VERSION ""

NS_ :

BS_:

BU_: MVS RCR_R RCR_L SNR ADAS ADAS_GW ENM THM CHR BAT BEV BEV_GW MET C_ECU C_ECU_GW

BO_ 824 ADAS338: 32 ADAS
 SG_ ADAS338_22_0_OBJECT16_WINKER : 176|2@1+ (1,0) [0|0] ""  MET
 SG_ ADAS338_22_2_OBJECT16_BRAKE : 178|1@1+ (1,0) [0|0] ""  MET
 SG_ ADAS338_22_3_OBJECT16_BLINK : 179|2@1+ (1,0) [0|0] ""  MET
 SG_ ADAS338_22_5_OBJECT16_Z : 181|11@1+ (0.1,-20) [0|0] "m"  MET
 SG_ ADAS338_20_0_OBJECT16_X : 160|9@1+ (0.1,-15) [0|0] "m"  MET
 SG_ ADAS338_19_1_OBJECT16_ANGLE : 153|7@1+ (5,0) [0|0] "deg"  MET
 SG_ ADAS338_18_0_OBJECT16_COLOR : 144|4@1+ (1,0) [0|0] ""  MET
 SG_ ADAS338_18_4_OBJECT16_SHAPE : 148|4@1+ (1,0) [0|0] ""  MET
 SG_ ADAS338_17_0_OBJECT15_WINKER : 136|2@1+ (1,0) [0|0] ""  MET
 SG_ ADAS338_17_2_OBJECT15_BRAKE : 138|1@1+ (1,0) [0|0] ""  MET
 SG_ ADAS338_17_3_OBJECT15_BLINK : 139|2@1+ (1,0) [0|0] ""  MET
 SG_ ADAS338_17_5_OBJECT15_Z : 141|11@1+ (0.1,-20) [0|0] "m"  MET
 SG_ ADAS338_15_0_OBJECT15_X : 120|9@1+ (0.1,-15) [0|0] "m"  MET
 SG_ ADAS338_14_1_OBJECT15_ANGLE : 113|7@1+ (5,0) [0|0] "deg"  MET
 SG_ ADAS338_13_0_OBJECT15_COLOR : 104|4@1+ (1,0) [0|0] ""  MET
 SG_ ADAS338_13_4_OBJECT15_SHAPE : 108|4@1+ (1,0) [0|0] ""  MET
 SG_ ADAS338_12_0_OBJECT14_WINKER : 96|2@1+ (1,0) [0|0] ""  MET
 SG_ ADAS338_12_2_OBJECT14_BRAKE : 98|1@1+ (1,0) [0|0] ""  MET
 SG_ ADAS338_12_3_OBJECT14_BLINK : 99|2@1+ (1,0) [0|0] ""  MET
 SG_ ADAS338_12_5_OBJECT14_Z : 101|11@1+ (0.1,-20) [0|0] "m"  MET
 SG_ ADAS338_10_0_OBJECT14_X : 80|9@1+ (0.1,-15) [0|0] "m"  MET
 SG_ ADAS338_9_1_OBJECT14_ANGLE : 73|7@1+ (5,0) [0|0] "deg"  MET
 SG_ ADAS338_8_0_OBJECT14_COLOR : 64|4@1+ (1,0) [0|0] ""  MET
 SG_ ADAS338_8_4_OBJECT14_SHAPE : 68|4@1+ (1,0) [0|0] ""  MET
 SG_ ADAS338_7_0_OBJECT13_WINKER : 56|2@1+ (1,0) [0|0] ""  MET
 SG_ ADAS338_7_2_OBJECT13_BRAKE : 58|1@1+ (1,0) [0|0] ""  MET
 SG_ ADAS338_7_3_OBJECT13_BLINK : 59|2@1+ (1,0) [0|0] ""  MET
 SG_ ADAS338_7_5_OBJECT13_Z : 61|11@1+ (0.1,-20) [0|0] "m"  MET
 SG_ ADAS338_5_0_OBJECT13_X : 40|9@1+ (0.1,-15) [0|0] "m"  MET
 SG_ ADAS338_4_1_OBJECT13_ANGLE : 33|7@1+ (5,0) [0|0] "deg"  MET
 SG_ ADAS338_3_0_OBJECT13_COLOR : 24|4@1+ (1,0) [0|0] ""  MET
 SG_ ADAS338_3_4_OBJECT13_SHAPE : 28|4@1+ (1,0) [0|0] ""  MET
 SG_ ADAS338_2_0_E2E_COUNTER : 16|8@1+ (1,0) [0|255] ""  MET
 SG_ ADAS338_0_0_E2E_CRC : 0|16@1+ (1,0) [0|65535] ""  MET

BO_ 823 ADAS337: 32 ADAS
 SG_ ADAS337_22_0_OBJECT12_WINKER : 176|2@1+ (1,0) [0|0] ""  MET
 SG_ ADAS337_22_2_OBJECT12_BRAKE : 178|1@1+ (1,0) [0|0] ""  MET
 SG_ ADAS337_22_3_OBJECT12_BLINK : 179|2@1+ (1,0) [0|0] ""  MET
 SG_ ADAS337_22_5_OBJECT12_Z : 181|11@1+ (0.1,-20) [0|0] "m"  MET
 SG_ ADAS337_20_0_OBJECT12_X : 160|9@1+ (0.1,-15) [0|0] "m"  MET
 SG_ ADAS337_19_1_OBJECT12_ANGLE : 153|7@1+ (5,0) [0|0] "deg"  MET
 SG_ ADAS337_18_0_OBJECT12_COLOR : 144|4@1+ (1,0) [0|0] ""  MET
 SG_ ADAS337_18_4_OBJECT12_SHAPE : 148|4@1+ (1,0) [0|0] ""  MET
 SG_ ADAS337_17_0_OBJECT11_WINKER : 136|2@1+ (1,0) [0|0] ""  MET
 SG_ ADAS337_17_2_OBJECT11_BRAKE : 138|1@1+ (1,0) [0|0] ""  MET
 SG_ ADAS337_17_3_OBJECT11_BLINK : 139|2@1+ (1,0) [0|0] ""  MET
 SG_ ADAS337_17_5_OBJECT11_Z : 141|11@1+ (0.1,-20) [0|0] "m"  MET
 SG_ ADAS337_15_0_OBJECT11_X : 120|9@1+ (0.1,-15) [0|0] "m"  MET
 SG_ ADAS337_14_1_OBJECT11_ANGLE : 113|7@1+ (5,0) [0|0] "deg"  MET
 SG_ ADAS337_13_0_OBJECT11_COLOR : 104|4@1+ (1,0) [0|0] ""  MET
 SG_ ADAS337_13_4_OBJECT11_SHAPE : 108|4@1+ (1,0) [0|0] ""  MET
 SG_ ADAS337_12_0_OBJECT10_WINKER : 96|2@1+ (1,0) [0|0] ""  MET
 SG_ ADAS337_12_2_OBJECT10_BRAKE : 98|1@1+ (1,0) [0|0] ""  MET
 SG_ ADAS337_12_3_OBJECT10_BLINK : 99|2@1+ (1,0) [0|0] ""  MET
 SG_ ADAS337_12_5_OBJECT10_Z : 101|11@1+ (0.1,-20) [0|0] "m"  MET
 SG_ ADAS337_10_0_OBJECT10_X : 80|9@1+ (0.1,-15) [0|0] "m"  MET
 SG_ ADAS337_9_1_OBJECT10_ANGLE : 73|7@1+ (5,0) [0|0] "deg"  MET
 SG_ ADAS337_8_0_OBJECT10_COLOR : 64|4@1+ (1,0) [0|0] ""  MET
 SG_ ADAS337_8_4_OBJECT10_SHAPE : 68|4@1+ (1,0) [0|0] ""  MET
 SG_ ADAS337_7_0_OBJECT9_WINKER : 56|2@1+ (1,0) [0|0] ""  MET
 SG_ ADAS337_7_2_OBJECT9_BRAKE : 58|1@1+ (1,0) [0|0] ""  MET
 SG_ ADAS337_7_3_OBJECT9_BLINK : 59|2@1+ (1,0) [0|0] ""  MET
 SG_ ADAS337_7_5_OBJECT9_Z : 61|11@1+ (0.1,-20) [0|0] "m"  MET
 SG_ ADAS337_5_0_OBJECT9_X : 40|9@1+ (0.1,-15) [0|0] "m"  MET
 SG_ ADAS337_4_1_OBJECT9_ANGLE : 33|7@1+ (5,0) [0|0] "deg"  MET
 SG_ ADAS337_3_0_OBJECT9_COLOR : 24|4@1+ (1,0) [0|0] ""  MET
 SG_ ADAS337_3_4_OBJECT9_SHAPE : 28|4@1+ (1,0) [0|0] ""  MET
 SG_ ADAS337_2_0_E2E_COUNTER : 16|8@1+ (1,0) [0|255] ""  MET
 SG_ ADAS337_0_0_E2E_CRC : 0|16@1+ (1,0) [0|65535] ""  MET

BO_ 822 ADAS336: 32 ADAS
 SG_ ADAS336_22_0_OBJECT8_WINKER : 176|2@1+ (1,0) [0|0] ""  MET
 SG_ ADAS336_22_2_OBJECT8_BRAKE : 178|1@1+ (1,0) [0|0] ""  MET
 SG_ ADAS336_22_3_OBJECT8_BLINK : 179|2@1+ (1,0) [0|0] ""  MET
 SG_ ADAS336_22_5_OBJECT8_Z : 181|11@1+ (0.1,-20) [0|0] "m"  MET
 SG_ ADAS336_20_0_OBJECT8_X : 160|9@1+ (0.1,-15) [0|0] "m"  MET
 SG_ ADAS336_19_1_OBJECT8_ANGLE : 153|7@1+ (5,0) [0|0] "deg"  MET
 SG_ ADAS336_18_0_OBJECT8_COLOR : 144|4@1+ (1,0) [0|0] ""  MET
 SG_ ADAS336_18_4_OBJECT8_SHAPE : 148|4@1+ (1,0) [0|0] ""  MET
 SG_ ADAS336_17_0_OBJECT7_WINKER : 136|2@1+ (1,0) [0|0] ""  MET
 SG_ ADAS336_17_2_OBJECT7_BRAKE : 138|1@1+ (1,0) [0|0] ""  MET
 SG_ ADAS336_17_3_OBJECT7_BLINK : 139|2@1+ (1,0) [0|0] ""  MET
 SG_ ADAS336_17_5_OBJECT7_Z : 141|11@1+ (0.1,-20) [0|0] "m"  MET
 SG_ ADAS336_15_0_OBJECT7_X : 120|9@1+ (0.1,-15) [0|0] "m"  MET
 SG_ ADAS336_14_1_OBJECT7_ANGLE : 113|7@1+ (5,0) [0|0] "deg"  MET
 SG_ ADAS336_13_0_OBJECT7_COLOR : 104|4@1+ (1,0) [0|0] ""  MET
 SG_ ADAS336_13_4_OBJECT7_SHAPE : 108|4@1+ (1,0) [0|0] ""  MET
 SG_ ADAS336_12_0_OBJECT6_WINKER : 96|2@1+ (1,0) [0|0] ""  MET
 SG_ ADAS336_12_2_OBJECT6_BRAKE : 98|1@1+ (1,0) [0|0] ""  MET
 SG_ ADAS336_12_3_OBJECT6_BLINK : 99|2@1+ (1,0) [0|0] ""  MET
 SG_ ADAS336_12_5_OBJECT6_Z : 101|11@1+ (0.1,-20) [0|0] "m"  MET
 SG_ ADAS336_10_0_OBJECT6_X : 80|9@1+ (0.1,-15) [0|0] "m"  MET
 SG_ ADAS336_9_1_OBJECT6_ANGLE : 73|7@1+ (5,0) [0|0] "deg"  MET
 SG_ ADAS336_8_0_OBJECT6_COLOR : 64|4@1+ (1,0) [0|0] ""  MET
 SG_ ADAS336_8_4_OBJECT6_SHAPE : 68|4@1+ (1,0) [0|0] ""  MET
 SG_ ADAS336_7_0_OBJECT5_WINKER : 56|2@1+ (1,0) [0|0] ""  MET
 SG_ ADAS336_7_2_OBJECT5_BRAKE : 58|1@1+ (1,0) [0|0] ""  MET
 SG_ ADAS336_7_3_OBJECT5_BLINK : 59|2@1+ (1,0) [0|0] ""  MET
 SG_ ADAS336_7_5_OBJECT5_Z : 61|11@1+ (0.1,-20) [0|0] "m"  MET
 SG_ ADAS336_5_0_OBJECT5_X : 40|9@1+ (0.1,-15) [0|0] "m"  MET
 SG_ ADAS336_4_1_OBJECT5_ANGLE : 33|7@1+ (5,0) [0|0] "deg"  MET
 SG_ ADAS336_3_0_OBJECT5_COLOR : 24|4@1+ (1,0) [0|0] ""  MET
 SG_ ADAS336_3_4_OBJECT5_SHAPE : 28|4@1+ (1,0) [0|0] ""  MET
 SG_ ADAS336_2_0_E2E_COUNTER : 16|8@1+ (1,0) [0|255] ""  MET
 SG_ ADAS336_0_0_E2E_CRC : 0|16@1+ (1,0) [0|65535] ""  MET

BO_ 821 ADAS335: 32 ADAS
 SG_ ADAS335_22_0_OBJECT4_WINKER : 176|2@1+ (1,0) [0|0] ""  MET
 SG_ ADAS335_22_2_OBJECT4_BRAKE : 178|1@1+ (1,0) [0|0] ""  MET
 SG_ ADAS335_22_3_OBJECT4_BLINK : 179|2@1+ (1,0) [0|0] ""  MET
 SG_ ADAS335_22_5_OBJECT4_Z : 181|11@1+ (0.1,-20) [0|0] "m"  MET
 SG_ ADAS335_20_0_OBJECT4_X : 160|9@1+ (0.1,-15) [0|0] "m"  MET
 SG_ ADAS335_19_1_OBJECT4_ANGLE : 153|7@1+ (5,0) [0|0] "deg"  MET
 SG_ ADAS335_18_0_OBJECT4_COLOR : 144|4@1+ (1,0) [0|0] ""  MET
 SG_ ADAS335_18_4_OBJECT4_SHAPE : 148|4@1+ (1,0) [0|0] ""  MET
 SG_ ADAS335_17_0_OBJECT3_WINKER : 136|2@1+ (1,0) [0|0] ""  MET
 SG_ ADAS335_17_2_OBJECT3_BRAKE : 138|1@1+ (1,0) [0|0] ""  MET
 SG_ ADAS335_17_3_OBJECT3_BLINK : 139|2@1+ (1,0) [0|0] ""  MET
 SG_ ADAS335_17_5_OBJECT3_Z : 141|11@1+ (0.1,-20) [0|0] "m"  MET
 SG_ ADAS335_15_0_OBJECT3_X : 120|9@1+ (0.1,-15) [0|0] "m"  MET
 SG_ ADAS335_14_1_OBJECT3_ANGLE : 113|7@1+ (5,0) [0|0] "deg"  MET
 SG_ ADAS335_13_0_OBJECT3_COLOR : 104|4@1+ (1,0) [0|0] ""  MET
 SG_ ADAS335_13_4_OBJECT3_SHAPE : 108|4@1+ (1,0) [0|0] ""  MET
 SG_ ADAS335_12_0_OBJECT2_WINKER : 96|2@1+ (1,0) [0|0] ""  MET
 SG_ ADAS335_12_2_OBJECT2_BRAKE : 98|1@1+ (1,0) [0|0] ""  MET
 SG_ ADAS335_12_3_OBJECT2_BLINK : 99|2@1+ (1,0) [0|0] ""  MET
 SG_ ADAS335_12_5_OBJECT2_Z : 101|11@1+ (0.1,-20) [0|0] "m"  MET
 SG_ ADAS335_10_0_OBJECT2_X : 80|9@1+ (0.1,-15) [0|0] "m"  MET
 SG_ ADAS335_9_1_OBJECT2_ANGLE : 73|7@1+ (5,0) [0|0] "deg"  MET
 SG_ ADAS335_8_0_OBJECT2_COLOR : 64|4@1+ (1,0) [0|0] ""  MET
 SG_ ADAS335_8_4_OBJECT2_SHAPE : 68|4@1+ (1,0) [0|0] ""  MET
 SG_ ADAS335_7_0_OBJECT1_WINKER : 56|2@1+ (1,0) [0|0] ""  MET
 SG_ ADAS335_7_2_OBJECT1_BRAKE : 58|1@1+ (1,0) [0|0] ""  MET
 SG_ ADAS335_7_3_OBJECT1_BLINK : 59|2@1+ (1,0) [0|0] ""  MET
 SG_ ADAS335_7_5_OBJECT1_Z : 61|11@1+ (0.1,-20) [0|0] "m"  MET
 SG_ ADAS335_5_0_OBJECT1_X : 40|9@1+ (0.1,-15) [0|0] "m"  MET
 SG_ ADAS335_4_1_OBJECT1_ANGLE : 33|7@1+ (5,0) [0|0] "deg"  MET
 SG_ ADAS335_3_0_OBJECT1_COLOR : 24|4@1+ (1,0) [0|0] ""  MET
 SG_ ADAS335_3_4_OBJECT1_SHAPE : 28|4@1+ (1,0) [0|0] ""  MET
 SG_ ADAS335_2_0_E2E_COUNTER : 16|8@1+ (1,0) [0|255] ""  MET
 SG_ ADAS335_0_0_E2E_CRC : 0|16@1+ (1,0) [0|65535] ""  MET

BO_ 817 ADAS331: 32 ADAS

BO_ 813 ADAS32D: 32 ADAS
 SG_ ADAS32D_2_0_E2E_COUNTER : 16|8@1+ (1,0) [0|255] ""  MET
 SG_ ADAS32D_0_0_E2E_CRC : 0|16@1+ (1,0) [0|65535] ""  MET

BO_ 812 ADAS32C: 32 ADAS
 SG_ ADAS32C_2_0_E2E_COUNTER : 16|8@1+ (1,0) [0|255] ""  MET
 SG_ ADAS32C_0_0_E2E_CRC : 0|16@1+ (1,0) [0|65535] ""  MET

BO_ 797 ADAS31D: 32 ADAS
 SG_ ADAS31D_7_0_LANE_DEP_EFFE_LANE : 56|3@1+ (1,0) [0|0] ""  MET
 SG_ ADAS31D_7_3_LANE_DEP_EFFE_BLINK : 59|1@1+ (1,0) [0|0] ""  MET
 SG_ ADAS31D_7_4_LANE_DEP_EFFE_COLOR : 60|2@1+ (1,0) [0|0] ""  MET
 SG_ ADAS31D_7_6_LANE_DEP_EFFE_LR : 62|2@1+ (1,0) [0|0] ""  MET
 SG_ ADAS31D_6_0_ALC_ICON_LEFT_COLOR : 48|2@1+ (1,0) [0|0] ""  MET
 SG_ ADAS31D_6_2_ALC_ICON_RIGHT_COLOR : 50|2@1+ (1,0) [0|0] ""  MET
 SG_ ADAS31D_6_4_ALC_ICON_LEFT : 52|2@1+ (1,0) [0|0] ""  MET
 SG_ ADAS31D_6_6_ALC_ICON_RIGHT : 54|2@1+ (1,0) [0|0] ""  MET
 SG_ ADAS31D_5_2_LANE_CHANGE_LANE3 : 42|3@1+ (1,0) [0|0] ""  MET
 SG_ ADAS31D_5_5_LANE_CHANGE_LANE2 : 45|3@1+ (1,0) [0|0] ""  MET
 SG_ ADAS31D_4_0_LANE_CHANGE_LANE1 : 32|3@1+ (1,0) [0|0] ""  MET
 SG_ ADAS31D_4_3_LANE_CHANGE_COLOR : 35|1@1+ (1,0) [0|0] ""  MET
 SG_ ADAS31D_4_4_LANE_CHANGE_LR : 36|2@1+ (1,0) [0|0] ""  MET
 SG_ ADAS31D_4_6_VEHICLE_OFFSET_COLOR : 38|2@1+ (1,0) [0|0] ""  MET
 SG_ ADAS31D_3_0_VEHICLE_OFFSET_WIDTH : 24|3@1+ (0.2,0) [0|0] "m"  MET
 SG_ ADAS31D_3_3_VEHICLE_OFFSET_LANE : 27|3@1+ (1,0) [0|0] ""  MET
 SG_ ADAS31D_3_6_VEHICLE_OFFSET_LR : 30|2@1+ (1,0) [0|0] ""  MET
 SG_ ADAS31D_2_0_E2E_COUNTER : 16|8@1+ (1,0) [0|255] ""  MET
 SG_ ADAS31D_0_0_E2E_CRC : 0|16@1+ (1,0) [0|65535] ""  MET

BO_ 796 ADAS31C: 32 ADAS
 SG_ ADAS31C_25_0_LANE6_END_X : 200|9@1+ (0.1,-15) [0|0] ""  MET
 SG_ ADAS31C_24_1_LANE6_END_Z : 193|7@1+ (2,-20) [0|0] ""  MET
 SG_ ADAS31C_23_0_LANE6_MID3_X : 184|9@1+ (0.1,-15) [0|0] ""  MET
 SG_ ADAS31C_22_1_LANE6_MID3_Z : 177|7@1+ (2,-20) [0|0] ""  MET
 SG_ ADAS31C_21_0_LANE6_MID2_X : 168|9@1+ (0.1,-15) [0|0] ""  MET
 SG_ ADAS31C_20_1_LANE6_MID2_Z : 161|7@1+ (2,-20) [0|0] ""  MET
 SG_ ADAS31C_19_0_LANE6_MID1_X : 152|9@1+ (0.1,-15) [0|0] ""  MET
 SG_ ADAS31C_18_1_LANE6_MID1_Z : 145|7@1+ (2,-20) [0|0] ""  MET
 SG_ ADAS31C_17_0_LANE6_START_X : 136|9@1+ (0.1,-15) [0|0] ""  MET
 SG_ ADAS31C_16_1_LANE6_START_Z : 129|7@1+ (2,-20) [0|0] ""  MET
 SG_ ADAS31C_15_0_LANE6_BLINK : 120|1@1+ (1,0) [0|0] ""  MET
 SG_ ADAS31C_15_1_LANE6_DISP : 121|1@1+ (1,0) [0|0] ""  MET
 SG_ ADAS31C_15_3_LANE6_COLOR : 123|3@1+ (1,0) [0|0] ""  MET
 SG_ ADAS31C_15_5_LANE6_TYPE : 125|3@1+ (1,0) [0|0] ""  MET
 SG_ ADAS31C_14_0_LANE6_NO : 112|3@1+ (1,0) [0|0] ""  MET
 SG_ ADAS31C_14_5_LANE5_NO : 117|3@1+ (1,0) [0|0] ""  MET
 SG_ ADAS31C_13_0_LANE5_END_X : 104|9@1+ (0.1,-15) [0|0] "m"  MET
 SG_ ADAS31C_12_1_LANE5_END_Z : 97|7@1+ (2,-20) [0|0] "m"  MET
 SG_ ADAS31C_11_0_LANE5_MID3_X : 88|9@1+ (0.1,-15) [0|0] "m"  MET
 SG_ ADAS31C_10_1_LANE5_MID3_Z : 81|7@1+ (2,-20) [0|0] "m"  MET
 SG_ ADAS31C_9_0_LANE5_MID2_X : 72|9@1+ (0.1,-15) [0|0] "m"  MET
 SG_ ADAS31C_8_1_LANE5_MID2_Z : 65|7@1+ (2,-20) [0|0] "m"  MET
 SG_ ADAS31C_7_0_LANE5_MID1_X : 56|9@1+ (0.1,-15) [0|0] "m"  MET
 SG_ ADAS31C_6_1_LANE5_MID1_Z : 49|7@1+ (2,-20) [0|0] "m"  MET
 SG_ ADAS31C_5_0_LANE5_START_X : 40|9@1+ (0.1,-15) [0|0] "m"  MET
 SG_ ADAS31C_4_1_LANE5_START_Z : 33|7@1+ (2,-20) [0|0] "m"  MET
 SG_ ADAS31C_3_0_LANE5_BLINK : 24|1@1+ (1,0) [0|0] ""  MET
 SG_ ADAS31C_3_1_LANE5_DISP : 25|1@1+ (1,0) [0|0] ""  MET
 SG_ ADAS31C_3_2_LANE5_COLOR : 26|3@1+ (1,0) [0|0] ""  MET
 SG_ ADAS31C_3_5_LANE5_TYPE : 29|3@1+ (1,0) [0|0] ""  MET
 SG_ ADAS31C_2_0_E2E_COUNTER : 16|8@1+ (1,0) [0|255] ""  MET
 SG_ ADAS31C_0_0_E2E_CRC : 0|16@1+ (1,0) [0|65535] ""  MET

BO_ 795 ADAS31B: 32 ADAS
 SG_ ADAS31B_31_0_LANE_DRAW_DISTANCE : 248|9@1+ (0.5,-20) [0|0] "m"  MET
 SG_ ADAS31B_30_1_INTERSECTION_MODE : 241|1@1+ (1,0) [0|0] ""  MET
 SG_ ADAS31B_29_0_ROAD2_END : 232|8@1+ (1,-20) [0|0] "m"  MET
 SG_ ADAS31B_28_0_ROAD2_START : 224|8@1+ (1,-20) [0|0] "m"  MET
 SG_ ADAS31B_27_1_ROAD2_LANE2 : 217|3@1+ (1,0) [0|0] ""  MET
 SG_ ADAS31B_27_4_ROAD2_LANE1 : 220|3@1+ (1,0) [0|0] ""  MET
 SG_ ADAS31B_27_7_ROAD2_BLINK : 223|1@1+ (1,0) [0|0] ""  MET
 SG_ ADAS31B_26_0_ROAD2_END_DRAW : 208|1@1+ (1,0) [0|0] ""  MET
 SG_ ADAS31B_26_1_ROAD2_START_DRAW : 209|1@1+ (1,0) [0|0] ""  MET
 SG_ ADAS31B_26_1_ROAD2_ANIMATION : 210|3@1+ (1,0) [0|0] ""  MET
 SG_ ADAS31B_26_5_ROAD2_COLOR : 213|3@1+ (1,0) [0|0] ""  MET
 SG_ ADAS31B_25_0_LANE4_END_X : 200|9@1+ (0.1,-15) [0|0] ""  MET
 SG_ ADAS31B_24_1_LANE4_END_Z : 193|7@1+ (2,-20) [0|0] ""  MET
 SG_ ADAS31B_23_0_LANE4_MID3_X : 184|9@1+ (0.1,-15) [0|0] ""  MET
 SG_ ADAS31B_22_1_LANE4_MID3_Z : 177|7@1+ (2,-20) [0|0] ""  MET
 SG_ ADAS31B_21_0_LANE4_MID2_X : 168|9@1+ (0.1,-15) [0|0] ""  MET
 SG_ ADAS31B_20_1_LANE4_MID2_Z : 161|7@1+ (2,-20) [0|0] ""  MET
 SG_ ADAS31B_19_0_LANE4_MID1_X : 152|9@1+ (0.1,-15) [0|0] ""  MET
 SG_ ADAS31B_18_1_LANE4_MID1_Z : 145|7@1+ (2,-20) [0|0] ""  MET
 SG_ ADAS31B_17_0_LANE4_START_X : 136|9@1+ (0.1,-15) [0|0] ""  MET
 SG_ ADAS31B_16_1_LANE4_START_Z : 129|7@1+ (2,-20) [0|0] ""  MET
 SG_ ADAS31B_15_0_LANE4_BLINK : 120|1@1+ (1,0) [0|0] ""  MET
 SG_ ADAS31B_15_1_LANE4_DISP : 121|1@1+ (1,0) [0|0] ""  MET
 SG_ ADAS31B_15_3_LANE4_COLOR : 123|3@1+ (1,0) [0|0] ""  MET
 SG_ ADAS31B_15_5_LANE4_TYPE : 125|3@1+ (1,0) [0|0] ""  MET
 SG_ ADAS31B_14_0_LANE4_NO : 112|3@1+ (1,0) [0|0] ""  MET
 SG_ ADAS31B_14_5_LANE3_NO : 117|3@1+ (1,0) [0|0] ""  MET
 SG_ ADAS31B_13_0_LANE3_END_X : 104|9@1+ (0.1,-15) [0|0] "m"  MET
 SG_ ADAS31B_12_1_LANE3_END_Z : 97|7@1+ (2,-20) [0|0] "m"  MET
 SG_ ADAS31B_11_0_LANE3_MID3_X : 88|9@1+ (0.1,-15) [0|0] "m"  MET
 SG_ ADAS31B_10_1_LANE3_MID3_Z : 81|7@1+ (2,-20) [0|0] "m"  MET
 SG_ ADAS31B_9_0_LANE3_MID2_X : 72|9@1+ (0.1,-15) [0|0] "m"  MET
 SG_ ADAS31B_8_1_LANE3_MID2_Z : 65|7@1+ (2,-20) [0|0] "m"  MET
 SG_ ADAS31B_7_0_LANE3_MID1_X : 56|9@1+ (0.1,-15) [0|0] "m"  MET
 SG_ ADAS31B_6_1_LANE3_MID1_Z : 49|7@1+ (2,-20) [0|0] "m"  MET
 SG_ ADAS31B_5_0_LANE3_START_X : 40|9@1+ (0.1,-15) [0|0] "m"  MET
 SG_ ADAS31B_4_1_LANE3_START_Z : 33|7@1+ (2,-20) [0|0] "m"  MET
 SG_ ADAS31B_3_0_LANE3_BLINK : 24|1@1+ (1,0) [0|0] ""  MET
 SG_ ADAS31B_3_1_LANE3_DISP : 25|1@1+ (1,0) [0|0] ""  MET
 SG_ ADAS31B_3_2_LANE3_COLOR : 26|3@1+ (1,0) [0|0] ""  MET
 SG_ ADAS31B_3_5_LANE3_TYPE : 29|3@1+ (1,0) [0|0] ""  MET

BO_ 794 ADAS31A: 32 ADAS
 SG_ ADAS31A_30_1_LANE_DEP_LANE_COLOR : 241|3@1+ (1,0) [0|7] ""  MET
 SG_ ADAS31A_30_4_LANE_DEP_LANE_TYPE : 244|2@1+ (1,0) [0|3] ""  MET
 SG_ ADAS31A_30_6_LANE_DEP_LANE_LEFT : 246|1@1+ (1,0) [0|1] ""  MET
 SG_ ADAS31A_30_7_LANE_DEP_LANE_RIGHT : 247|1@1+ (1,0) [0|1] ""  MET
 SG_ ADAS31A_29_0_ROAD1_END : 232|8@1+ (1,-20) [0|255] "m"  MET
 SG_ ADAS31A_28_0_ROAD1_START : 224|8@1+ (1,-20) [0|255] "m"  MET
 SG_ ADAS31A_27_1_ROAD1_LANE2 : 217|3@1+ (1,0) [0|7] ""  MET
 SG_ ADAS31A_27_4_ROAD1_LANE1 : 220|3@1+ (1,0) [0|7] ""  MET
 SG_ ADAS31A_27_7_ROAD1_BLINK : 223|1@1+ (1,0) [0|1] ""  MET
 SG_ ADAS31A_26_0_ROAD1_END_DRAW : 208|1@1+ (1,0) [0|1] ""  MET
 SG_ ADAS31A_26_1_ROAD1_START_DRAW : 209|1@1+ (1,0) [0|1] ""  MET
 SG_ ADAS31A_26_2_ROAD1_ANIMATION : 210|3@1+ (1,0) [0|7] ""  MET
 SG_ ADAS31A_26_5_ROAD1_COLOR : 213|3@1+ (1,0) [0|7] ""  MET
 SG_ ADAS31A_25_0_LANE2_END_X : 200|9@1+ (0.1,-15) [0|511] ""  MET
 SG_ ADAS31A_24_1_LANE2_END_Z : 193|7@1+ (2,-20) [0|127] ""  MET
 SG_ ADAS31A_23_0_LANE2_MID3_X : 184|9@1+ (0.1,-15) [0|511] ""  MET
 SG_ ADAS31A_22_1_LANE2_MID3_Z : 177|7@1+ (2,-20) [0|127] ""  MET
 SG_ ADAS31A_21_0_LANE2_MID2_X : 168|9@1+ (0.1,-15) [0|511] ""  MET
 SG_ ADAS31A_20_1_LANE2_MID2_Z : 161|7@1+ (2,-20) [0|127] ""  MET
 SG_ ADAS31A_19_0_LANE2_MID1_X : 152|9@1+ (0.1,-15) [0|511] ""  MET
 SG_ ADAS31A_18_1_LANE2_MID1_Z : 145|7@1+ (2,-20) [0|127] ""  MET
 SG_ ADAS31A_17_0_LANE2_START_X : 136|9@1+ (0.1,-15) [0|511] ""  MET
 SG_ ADAS31A_16_1_LANE2_START_Z : 129|7@1+ (2,-20) [0|127] ""  MET
 SG_ ADAS31A_15_0_LANE2_BLINK : 120|1@1+ (1,0) [0|1] ""  MET
 SG_ ADAS31A_15_1_LANE2_DISP : 121|1@1+ (1,0) [0|1] ""  MET
 SG_ ADAS31A_15_3_LANE2_COLOR : 123|3@1+ (1,0) [0|7] ""  MET
 SG_ ADAS31A_15_5_LANE2_TYPE : 125|3@1+ (1,0) [0|7] ""  MET
 SG_ ADAS31A_14_0_LANE2_NO : 112|3@1+ (1,0) [0|7] ""  MET
 SG_ ADAS31A_14_5_LANE1_NO : 117|3@1+ (1,0) [0|7] ""  MET
 SG_ ADAS31A_13_0_LANE1_END_X : 104|9@1+ (0.1,-15) [0|511] "m"  MET
 SG_ ADAS31A_12_1_LANE1_END_Z : 97|7@1+ (2,-20) [0|127] "m"  MET
 SG_ ADAS31A_11_0_LANE1_MID3_X : 88|9@1+ (0.1,-15) [0|511] "m"  MET
 SG_ ADAS31A_10_1_LANE1_MID3_Z : 81|7@1+ (2,-20) [0|127] "m"  MET
 SG_ ADAS31A_9_0_LANE1_MID2_X : 72|9@1+ (0.1,-15) [0|511] "m"  MET
 SG_ ADAS31A_8_1_LANE1_MID2_Z : 65|7@1+ (2,-20) [0|127] "m"  MET
 SG_ ADAS31A_7_0_LANE1_MID1_X : 56|9@1+ (0.1,-15) [0|511] "m"  MET
 SG_ ADAS31A_6_1_LANE1_MID1_Z : 49|7@1+ (2,-20) [0|127] "m"  MET
 SG_ ADAS31A_5_0_LANE1_START_X : 40|9@1+ (0.1,-15) [0|511] "m"  MET
 SG_ ADAS31A_4_1_LANE1_START_Z : 33|7@1+ (2,-20) [0|127] "m"  MET
 SG_ ADAS31A_3_0_LANE1_BLINK : 24|1@1+ (1,0) [0|1] ""  MET
 SG_ ADAS31A_3_1_LANE1_DISP : 25|1@1+ (1,0) [0|1] ""  MET
 SG_ ADAS31A_3_2_LANE1_COLOR : 26|3@1+ (1,0) [0|7] ""  MET
 SG_ ADAS31A_3_5_LANE1_TYPE : 29|3@1+ (1,0) [0|7] ""  MET
 SG_ ADAS31A_2_0_E2E_COUNTER : 16|8@1+ (1,0) [0|255] ""  MET
 SG_ ADAS31A_0_0_E2E_CRC : 0|16@1+ (1,0) [0|65535] ""  MET

BO_ 793 ADAS319: 32 ADAS
 SG_ ADAS319_2_0_E2E_COUNTER : 16|8@1+ (1,0) [0|255] ""  MET
 SG_ ADAS319_0_0_E2E_CRC : 0|16@1+ (1,0) [0|65535] ""  MET

BO_ 792 ADAS318: 32 ADAS
 SG_ ADAS318_31_3_FCW_INIT_LAMP : 251|1@1+ (1,0) [0|1] ""  MET
 SG_ ADAS318_31_2_ADAS_CAUTION_INIT : 250|1@1+ (1,0) [0|1] ""  MET
 SG_ ADAS318_31_1_LANE_DEP_INIT : 249|1@1+ (1,0) [0|1] ""  MET
 SG_ ADAS318_31_0_PRECRASH_INIT : 248|1@1+ (1,0) [0|1] ""  MET
 SG_ ADAS318_18_0_DISP_RE_WRNG : 144|2@1+ (1,0) [0|3] ""  MET
 SG_ ADAS318_17_6_DISP_RE_SIDE_WRNG : 142|2@1+ (1,0) [0|3] ""  MET
 SG_ ADAS318_17_4_DISP_FR_SIDE_WRNG : 140|2@1+ (1,0) [0|3] ""  MET
 SG_ ADAS318_17_2_DISP_FR_WRNG : 138|2@1+ (1,0) [0|3] ""  MET
 SG_ ADAS318_17_0_DISP_ALL_WRNG : 136|2@1+ (1,0) [0|3] ""  MET
 SG_ ADAS318_13_0_MSG_SIGN_UNRECOG : 104|1@1+ (1,0) [0|1] ""  MET
 SG_ ADAS318_12_7_MSG_STRG_TS_WRNG : 103|1@1+ (1,0) [0|1] ""  MET
 SG_ ADAS318_12_6_MSG_ADAS_SYS_ICON : 102|1@1+ (1,0) [0|1] ""  MET
 SG_ ADAS318_12_5_MSG_ADAS_FUNC_OFF : 101|1@1+ (1,0) [0|1] ""  MET
 SG_ ADAS318_12_4_MSG_ADAS_HALT : 100|1@1+ (1,0) [0|1] ""  MET
 SG_ ADAS318_12_3_MSG_ADAS_FAIL : 99|1@1+ (1,0) [0|1] ""  MET
 SG_ ADAS318_12_2_MSG_PASS_MRM_HALT : 98|1@1+ (1,0) [0|1] ""  MET
 SG_ ADAS318_12_1_MSG_PASS_MRM_FAIL : 97|1@1+ (1,0) [0|1] ""  MET
 SG_ ADAS318_12_0_MSG_SNR_HALT : 96|1@1+ (1,0) [0|1] ""  MET
 SG_ ADAS318_11_7_MSG_RAB_PED_HALT : 95|1@1+ (1,0) [0|1] ""  MET
 SG_ ADAS318_11_6_MSG_RAB_PED_FAIL : 94|1@1+ (1,0) [0|1] ""  MET
 SG_ ADAS318_11_5_MSG_RAB_HALT : 93|1@1+ (1,0) [0|1] ""  MET
 SG_ ADAS318_11_4_MSG_RAB_FAIL : 92|1@1+ (1,0) [0|1] ""  MET
 SG_ ADAS318_11_3_MSG_RCR_HALT_BLK : 91|1@1+ (1,0) [0|1] ""  MET
 SG_ ADAS318_11_2_MSG_RCR_HALT : 90|1@1+ (1,0) [0|1] ""  MET
 SG_ ADAS318_11_1_MSG_RCR_FAIL : 89|1@1+ (1,0) [0|1] ""  MET
 SG_ ADAS318_11_0_MSG_FCR_HALT : 88|1@1+ (1,0) [0|1] ""  MET
 SG_ ADAS318_10_7_MSG_FCR_FAIL : 87|1@1+ (1,0) [0|1] ""  MET
 SG_ ADAS318_10_6_MSG_MCAM_HALT : 86|1@1+ (1,0) [0|1] ""  MET
 SG_ ADAS318_10_5_MSG_MCAM_FAIL : 85|1@1+ (1,0) [0|1] ""  MET
 SG_ ADAS318_10_4_MSG_EYE_HALT : 84|1@1+ (1,0) [0|1] ""  MET
 SG_ ADAS318_10_3_MSG_EYE_HALT_TEMP : 83|1@1+ (1,0) [0|1] ""  MET
 SG_ ADAS318_10_2_MSG_EYE_HALT_WTR : 82|1@1+ (1,0) [0|1] ""  MET
 SG_ ADAS318_10_1_MSG_EYE_FAIL : 81|1@1+ (1,0) [0|1] ""  MET
 SG_ ADAS318_10_0_MSG_ADASECU_FAIL : 80|1@1+ (1,0) [0|1] ""  MET
 SG_ ADAS318_9_1_STRG_HAP_WRNG_IND : 73|1@1+ (1,0) [0|1] ""  MET
 SG_ ADAS318_9_0_STRG_TS_WRNG_IND : 72|1@1+ (1,0) [0|1] ""  MET
 SG_ ADAS318_8_7_ELK_OFF_IND : 71|1@1+ (1,0) [0|1] ""  MET
 SG_ ADAS318_8_6_AES_OFF_IND : 70|1@1+ (1,0) [0|1] ""  MET
 SG_ ADAS318_8_5_LDP_OFF_IND : 69|1@1+ (1,0) [0|1] ""  MET
 SG_ ADAS318_8_4_LKS_WRNG_IND : 68|1@1+ (1,0) [0|1] ""  MET
 SG_ ADAS318_8_3_ACC_WRNG_IND : 67|1@1+ (1,0) [0|1] ""  MET
 SG_ ADAS318_8_2_MRM_WRNG_IND : 66|1@1+ (1,0) [0|1] ""  MET
 SG_ ADAS318_8_0_DDAW_STATE_IND : 64|2@1+ (1,0) [0|3] ""  MET
 SG_ ADAS318_7_6_ISA_STATE_IND : 62|2@1+ (1,0) [0|3] ""  MET
 SG_ ADAS318_7_4_RAB_STATE_IND : 60|2@1+ (1,0) [0|3] ""  MET
 SG_ ADAS318_7_2_ACPE_STATE_IND : 58|2@1+ (1,0) [0|3] ""  MET
 SG_ ADAS318_7_0_ADAS_STATE_IND : 56|2@1+ (1,0) [0|3] ""  MET
 SG_ ADAS318_6_2_RAB_PED_STATE_IND : 50|2@1+ (1,0) [0|3] ""  MET
 SG_ ADAS318_6_0_SNR_STATE_IND : 48|2@1+ (1,0) [0|3] ""  MET
 SG_ ADAS318_5_6_SRVD_STATE_IND : 46|2@1+ (1,0) [0|3] ""  MET
 SG_ ADAS318_5_4_FCTB_STATE_IND : 44|2@1+ (1,0) [0|3] ""  MET
 SG_ ADAS318_5_2_MCAM_STATE_IND : 42|2@1+ (1,0) [0|3] ""  MET
 SG_ ADAS318_5_0_EYESIGHT_STATE_IND : 40|2@1+ (1,0) [0|3] ""  MET
 SG_ ADAS318_3_4_ADAS_CAUTION_IND : 28|2@1+ (1,0) [0|3] ""  MET
 SG_ ADAS318_3_2_LANE_DEP_STATE_IND : 26|2@1+ (1,0) [0|3] ""  MET
 SG_ ADAS318_3_0_PRECRASH_STATE_IND : 24|2@1+ (1,0) [0|3] ""  MET
 SG_ ADAS318_2_0_E2E_COUNTER : 16|8@1+ (1,0) [0|255] ""  MET
 SG_ ADAS318_0_0_E2E_CRC : 0|16@1+ (1,0) [0|65535] ""  MET

BO_ 791 ADAS317: 32 ADAS
 SG_ ADAS317_18_0_LIGHT_EAM_GREEN2 : 144|2@1+ (1,0) [0|3] "" Vector__XXX
 SG_ ADAS317_17_0_LIGHT_EAM_GREEN1 : 136|2@1+ (1,0) [0|3] "" Vector__XXX
 SG_ ADAS317_17_4_LIGHT_EAM_BLUE : 140|2@1+ (1,0) [0|3] "" Vector__XXX
 SG_ ADAS317_16_0_LIGHT_EAM_YELLOW : 128|4@1+ (1,0) [0|15] "" Vector__XXX
 SG_ ADAS317_16_4_LIGHT_EAM_RED : 132|4@1+ (1,0) [0|15] "" Vector__XXX
 SG_ ADAS317_15_0_LINK_ICON_POSITION : 120|2@1+ (1,0) [0|3] ""  MET
 SG_ ADAS317_15_2_LINK_ICON_SPD_SIGN : 122|2@1+ (1,0) [0|3] ""  MET
 SG_ ADAS317_15_4_LINK_ICON_CC : 124|2@1+ (1,0) [0|3] ""  MET
 SG_ ADAS317_14_0_SPD_CONT_ICON_COLOR : 112|3@1+ (1,0) [0|7] ""  MET
 SG_ ADAS317_14_3_SPD_CONT_ICON_BLINK : 115|1@1+ (1,0) [0|1] ""  MET
 SG_ ADAS317_14_4_SPD_CONT_ICON_DIST : 116|12@1+ (1,0) [0|4095] ""  MET
 SG_ ADAS317_12_0_SPD_CONT_ICON_SPEED : 96|8@1+ (1,0) [0|255] ""  MET
 SG_ ADAS317_11_0_SPD_CONT_ICON_TYPE : 88|6@1+ (1,0) [0|63] ""  MET
 SG_ ADAS317_10_0_SAFETY_MODE_PATTERN : 80|2@1+ (1,0) [0|3] ""  MET
 SG_ ADAS317_10_2_SAFETY_MODE_COLOR : 82|3@1+ (1,0) [0|7] ""  MET
 SG_ ADAS317_10_5_PDA_STEER_ICON : 85|2@1+ (1,0) [0|3] ""  MET
 SG_ ADAS317_9_0_FCW_INIT : 72|1@1+ (1,0) [0|1] ""  MET
 SG_ ADAS317_9_1_FCTI_ICON_LEFT : 73|2@1+ (1,0) [0|3] ""  MET
 SG_ ADAS317_9_3_FCTI_ICON_RIGHT : 75|2@1+ (1,0) [0|3] ""  MET
 SG_ ADAS317_9_5_IND_SAFETY_MODE : 77|1@1+ (1,0) [0|1] ""  MET
 SG_ ADAS317_9_6_LIMITER_BACK_SPEED : 78|1@1+ (1,0) [0|1] ""  MET
 SG_ ADAS317_8_0_LCF_ICON : 64|3@1+ (1,0) [0|7] ""  MET
 SG_ ADAS317_8_3_LCF_ICON_WORD : 67|1@1+ (1,0) [0|1] ""  MET
 SG_ ADAS317_8_4_AD_DRV_ICON : 68|2@1+ (1,0) [0|3] ""  MET
 SG_ ADAS317_8_6_ODD_ROAD_ICON : 70|1@1+ (1,0) [0|1] ""  MET
 SG_ ADAS317_7_0_INFO_SET_SPD : 56|8@1+ (1,0) [0|255] "km/h or MPH"  MET
 SG_ ADAS317_6_0_INFO_MAIN_CC : 48|3@1+ (1,0) [0|7] ""  MET
 SG_ ADAS317_6_3_HOLD_DISP : 51|1@1+ (1,0) [0|1] ""  MET
 SG_ ADAS317_5_1_ATTENUAT_MUTE : 41|2@1+ (1,0) [0|3] ""  MET
 SG_ ADAS317_5_3_SOUND_STOP_FLAG : 43|1@1+ (1,0) [0|1] ""  MET
 SG_ ADAS317_5_4_ALARMCODE_SOUND : 44|10@1+ (1,0) [0|1023] ""  MET
 SG_ ADAS317_4_6_ALARMCODE_DISP : 38|10@1+ (1,0) [0|1023] ""  MET
 SG_ ADAS317_2_0_E2E_COUNTER : 16|8@1+ (1,0) [0|255] ""  MET
 SG_ ADAS317_0_0_E2E_CRC : 0|16@1+ (1,0) [0|65535] ""  MET

BO_ 276 SNR114: 32 Vector__XXX

BO_ 2564481097 OBC18DAE049: 8 BEV_GW
 SG_ OBC18DAE049_DIAG_DATA : 7|64@0+ (1,0) [0|1.844674407371E+19] ""  C_ECU_GW

BO_ 2564442592 DNT18DA49E0: 8 C_ECU_GW
 SG_ DNT18DA49E0_DIAG_DATA : 7|64@0+ (1,0) [0|1.844674407371E+19] ""  BEV_GW

BO_ 1099 EVCC44B: 32 C_ECU_GW
 SG_ EVCC44B_27_0_EVSE_ID_7_EVCC : 216|32@1+ (1,0) [0|31] ""  CHR
 SG_ EVCC44B_23_0_EVSE_ID_6_EVCC : 184|32@1+ (1,0) [0|31] ""  CHR
 SG_ EVCC44B_19_0_EVSE_ID_5_EVCC : 152|32@1+ (1,0) [0|31] ""  CHR
 SG_ EVCC44B_15_0_EVSE_ID_4_EVCC : 120|32@1+ (1,0) [0|31] ""  CHR
 SG_ EVCC44B_11_0_EVSE_ID_3_EVCC : 88|32@1+ (1,0) [0|31] ""  CHR
 SG_ EVCC44B_7_0_EVSE_ID_2_EVCC : 56|32@1+ (1,0) [0|31] ""  CHR
 SG_ EVCC44B_3_0_EVSE_ID_1_EVCC : 24|32@1+ (1,0) [0|31] ""  CHR
 SG_ EVCC44B_2_0_E2E_COUNTER : 16|8@1+ (1,0) [0|255] "" Vector__XXX
 SG_ EVCC44B_0_0_E2E_CRC : 0|16@1+ (1,0) [0|65535] "" Vector__XXX

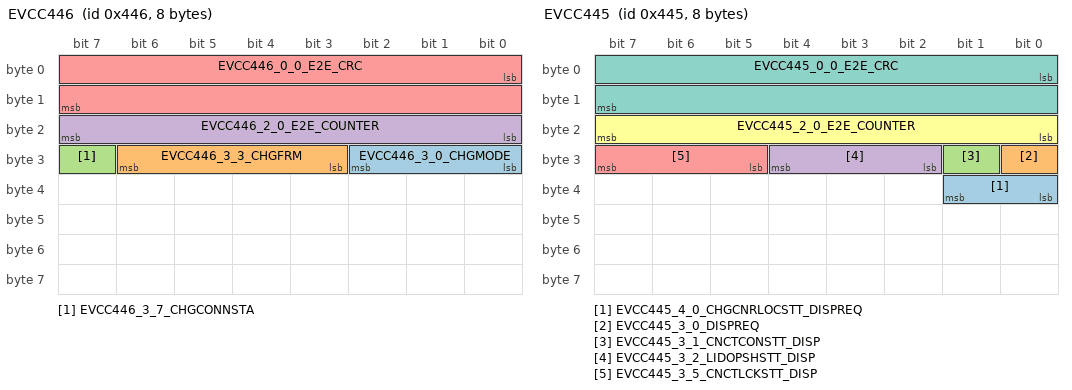
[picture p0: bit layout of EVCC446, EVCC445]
BO_ 1094 EVCC446: 8 C_ECU_GW
 SG_ EVCC446_3_0_CHGMODE : 24|3@1+ (1,0) [0|7] ""  MET
 SG_ EVCC446_3_3_CHGFRM : 27|4@1+ (1,0) [0|15] ""  MET
 SG_ EVCC446_3_7_CHGCONNSTA : 31|1@1+ (1,0) [0|1] ""  MET
 SG_ EVCC446_2_0_E2E_COUNTER : 16|8@1+ (1,0) [0|255] ""  MET
 SG_ EVCC446_0_0_E2E_CRC : 0|16@1+ (1,0) [0|65535] ""  MET

BO_ 1093 EVCC445: 8 C_ECU_GW
 SG_ EVCC445_4_0_CHGCNRLOCSTT_DISPREQ : 32|2@1+ (1,0) [0|2] ""  MET
 SG_ EVCC445_3_0_DISPREQ : 24|1@1+ (1,0) [0|1] "" Vector__XXX
 SG_ EVCC445_3_1_CNCTCONSTT_DISP : 25|1@1+ (1,0) [0|1] ""  MET
 SG_ EVCC445_3_2_LIDOPSHSTT_DISP : 26|3@1+ (1,0) [0|2] ""  MET
 SG_ EVCC445_3_5_CNCTLCKSTT_DISP : 29|3@1+ (1,0) [0|2] ""  MET
 SG_ EVCC445_2_0_E2E_COUNTER : 16|8@1+ (1,0) [0|255] "" Vector__XXX
 SG_ EVCC445_0_0_E2E_CRC : 0|16@1+ (1,0) [0|65535] "" Vector__XXX

BO_ 112 SFT070: 64 BEV_GW
 SG_ SFT070_10_1_PER_UNLOCK : 81|1@1+ (1,0) [0|0] "" Vector__XXX
 SG_ SFT070_6_1_SFT_SYS_FAIL : 49|1@1+ (1,0) [0|1] "" Vector__XXX
 SG_ SFT070_6_2_SFT_DIAGCODE_INFO : 50|22@1+ (1,0) [0|4194303] "" Vector__XXX
 SG_ SFT070_5_2_SFT_FAILSAFE_REQ : 42|2@1+ (1,0) [0|3] "" Vector__XXX
 SG_ SFT070_5_4_SFT_FAILMASSAGE_REQ : 44|3@1+ (1,0) [0|7] ""  MET
 SG_ SFT070_5_7_SFT_REJECT_AUTOPARK : 47|1@1+ (1,0) [0|1] "" Vector__XXX
 SG_ SFT070_4_0_SFT_DRIVER_OPR : 32|3@1+ (1,0) [0|7] ""  C_ECU
 SG_ SFT070_4_3_SFT_PSW : 35|1@1+ (1,0) [0|1] ""  C_ECU
 SG_ SFT070_4_4_SFT_BUZZER : 36|3@1+ (1,0) [0|7] ""  MET
 SG_ SFT070_4_7_SFT_MASSAGE_REQ : 39|3@1+ (1,0) [0|7] ""  MET
 SG_ SFT070_3_0_TARGET_RANGE : 24|3@1+ (1,0) [0|7] ""  C_ECU
 SG_ SFT070_3_3_PARKING_GEAR_INFO : 27|2@1+ (1,0) [0|3] "" Vector__XXX
 SG_ SFT070_3_5_DRIVER_REQ_RANGE : 29|3@1+ (1,0) [0|7] ""  C_ECU
 SG_ SFT070_2_0_E2E_COUNTER : 16|8@1+ (1,0) [0|255] ""  MET,C_ECU
 SG_ SFT070_0_0_E2E_CRC : 0|16@1+ (1,0) [0|65535] ""  MET,C_ECU

BO_ 1551 ENM60F: 32 ENM
 SG_ ENM60F_26_0_ACCMHVPWR_LC : 208|17@1+ (1,0) [0|101060] "kWh"  C_ECU_GW
 SG_ ENM60F_23_7_ACCMHVPWR_TRIPB : 191|17@1+ (1,0) [0|131060] "kWh"  C_ECU_GW
 SG_ ENM60F_21_6_ACCMHVPWR_TRIPA : 174|17@1+ (1,0) [0|131060] "kWh"  C_ECU_GW
 SG_ ENM60F_20_4_OTRACCMHVRATE_LC : 164|10@1+ (0.1,0) [0|100] "％"  C_ECU_GW
 SG_ ENM60F_19_2_ACOUTACCMRATE_LC : 154|10@1+ (0.1,0) [0|100] "％"  C_ECU_GW
 SG_ ENM60F_18_0_BADJACCMHVRATE_LC : 144|10@1+ (0.1,0) [0|100] "％"  C_ECU_GW
 SG_ ENM60F_16_6_ACNACCMHVRATE_LC : 134|10@1+ (0.1,0) [0|100] "％"  C_ECU_GW
 SG_ ENM60F_15_4_MOTACCMHVRATE_LC : 124|10@1+ (0.1,0) [0|100] "％"  C_ECU_GW
 SG_ ENM60F_14_2_OTRACCMHVRATE_TRIPB : 114|10@1+ (0.1,0) [0|100] "％"  C_ECU_GW
 SG_ ENM60F_13_0_ACOUTACCMRATE_TRIPB : 104|10@1+ (0.1,0) [0|100] "％"  C_ECU_GW
 SG_ ENM60F_11_6_BADJACCMHVRATE_TRIPB : 94|10@1+ (0.1,0) [0|100] "％"  C_ECU_GW
 SG_ ENM60F_10_4_ACNACCMHVRATE_TRIPB : 84|10@1+ (0.1,0) [0|100] "％"  C_ECU_GW
 SG_ ENM60F_9_2_MOTACCMHVRATE_TRIPB : 74|10@1+ (0.1,0) [0|100] "％"  C_ECU_GW
 SG_ ENM60F_8_0_OTRACCMHVRATE_TRIPA : 64|10@1+ (0.1,0) [0|100] "％"  C_ECU_GW
 SG_ ENM60F_6_6_ACOUTACCMRATE_TRIPA : 54|10@1+ (0.1,0) [0|100] "％"  C_ECU_GW
 SG_ ENM60F_5_4_BADJACCMHVRATE_TRIPA : 44|10@1+ (0.1,0) [0|100] "％"  C_ECU_GW
 SG_ ENM60F_4_2_ACNACCMHVRATE_TRIPA : 34|10@1+ (0.1,0) [0|100] "％"  C_ECU_GW
 SG_ ENM60F_3_0_MOTACCMHVRATE_TRIPA : 24|10@1+ (0.1,0) [0|100] "％"  C_ECU_GW
 SG_ ENM60F_2_0_E2E_COUNTER : 16|8@1+ (1,0) [0|255] ""  C_ECU_GW
 SG_ ENM60F_0_0_E2E_CRC : 0|16@1+ (1,0) [0|65535] ""  C_ECU_GW

BO_ 1550 ENM60E: 32 ENM
 SG_ ENM60E_28_0_DRNDISPREQ : 224|5@1+ (1,0) [0|31] ""  C_ECU_GW
 SG_ ENM60E_27_0_INJDISPREQ : 216|5@1+ (1,0) [0|31] ""  C_ECU_GW
 SG_ ENM60E_26_0_HVBTHMADJSTT : 208|1@1+ (1,0) [0|1] ""  C_ECU_GW
 SG_ ENM60E_26_1_ACNOFFCMD : 209|2@1+ (1,0) [0|3] ""  C_ECU_GW
 SG_ ENM60E_26_3_IJDRMDONOFF : 210|1@1+ (1,0) [0|1] ""  C_ECU_GW
 SG_ ENM60E_26_4_ACNHVDDRVADM : 211|1@1+ (1,0) [0|1] ""  C_ECU,C_ECU_GW
 SG_ ENM60E_26_5_ACNINHSIG : 212|1@1+ (1,0) [0|1] ""  C_ECU_GW
 SG_ ENM60E_25_0_CNSPPWR_RATE : 200|8@1+ (1,0) [0|100] "%"  C_ECU_GW
 SG_ ENM60E_24_0_V2LPWR_RATE : 192|8@1+ (1,0) [0|100] "%"  C_ECU_GW
 SG_ ENM60E_23_0_HVBCNSPPWR_RATE : 184|8@1+ (1,0) [0|100] "%"  C_ECU_GW
 SG_ ENM60E_22_0_ACNPWR_RATE : 176|8@1+ (1,0) [0|100] "%"  C_ECU_GW
 SG_ ENM60E_21_0_DRVPWR_RATE : 168|8@1+ (1,0) [0|100] "%"  C_ECU_GW
 SG_ ENM60E_20_0_AVECNSPPWR15 : 160|8@1+ (0.1,0) [0|25.5] "km/kWh"  C_ECU_GW
 SG_ ENM60E_19_0_AVECNSPPWR14 : 152|8@1+ (0.1,0) [0|25.5] "km/kWh"  C_ECU_GW
 SG_ ENM60E_18_0_AVECNSPPWR13 : 144|8@1+ (0.1,0) [0|25.5] "km/kWh"  C_ECU_GW
 SG_ ENM60E_17_0_AVECNSPPWR12 : 136|8@1+ (0.1,0) [0|25.5] "km/kWh"  C_ECU_GW
 SG_ ENM60E_16_0_AVECNSPPWR11 : 128|8@1+ (0.1,0) [0|25.5] "km/kWh"  C_ECU_GW
 SG_ ENM60E_15_0_AVECNSPPWR10 : 120|8@1+ (0.1,0) [0|25.5] "km/kWh"  C_ECU_GW
 SG_ ENM60E_14_0_AVECNSPPWR9 : 112|8@1+ (0.1,0) [0|25.5] "km/kWh"  C_ECU_GW
 SG_ ENM60E_13_0_AVECNSPPWR8 : 104|8@1+ (0.1,0) [0|25.5] "km/kWh"  C_ECU_GW
 SG_ ENM60E_12_0_AVECNSPPWR7 : 96|8@1+ (0.1,0) [0|25.5] "km/kWh"  C_ECU_GW
 SG_ ENM60E_11_0_AVECNSPPWR6 : 88|8@1+ (0.1,0) [0|25.5] "km/kWh"  C_ECU_GW
 SG_ ENM60E_10_0_AVECNSPPWR5 : 80|8@1+ (0.1,0) [0|25.5] "km/kWh"  C_ECU_GW
 SG_ ENM60E_9_0_AVECNSPPWR4 : 72|8@1+ (0.1,0) [0|25.5] "km/kWh"  C_ECU_GW
 SG_ ENM60E_8_0_AVECNSPPWR3 : 64|8@1+ (0.1,0) [0|25.5] "km/kWh"  C_ECU_GW
 SG_ ENM60E_7_0_AVECNSPPWR2 : 56|8@1+ (0.1,0) [0|25.5] "km/kWh"  C_ECU_GW
 SG_ ENM60E_6_0_AVECNSPPWR1 : 48|8@1+ (0.1,0) [0|25.5] "km/kWh"  C_ECU_GW
 SG_ ENM60E_5_0_HVBAVETEMP : 40|8@1+ (0.5,-40) [-40|87.5] "℃"  C_ECU_GW
 SG_ ENM60E_4_0_AUXCNSPPWR : 32|8@1+ (20,0) [0|5100] "W"  C_ECU_GW
 SG_ ENM60E_3_0_ACNCNSPPWR : 24|8@1+ (100,0) [0|25500] "W"  C_ECU_GW
 SG_ ENM60E_2_0_E2E_COUNTER : 16|8@1+ (1,0) [0|255] ""  C_ECU,C_ECU_GW
 SG_ ENM60E_0_0_E2E_CRC : 0|16@1+ (1,0) [0|65535] ""  C_ECU,C_ECU_GW

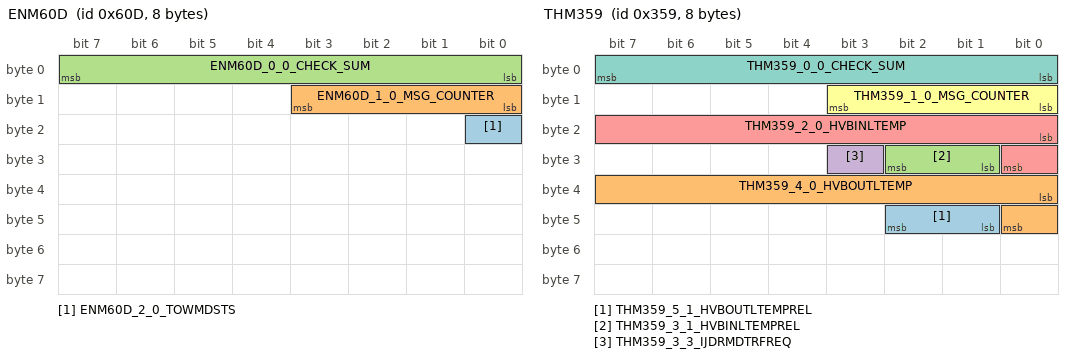
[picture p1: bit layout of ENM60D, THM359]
BO_ 1549 ENM60D: 8 ENM
 SG_ ENM60D_2_0_TOWMDSTS : 16|1@1+ (1,0) [0|1] ""  MVS,RCR_L,SNR,ADAS,MET,C_ECU_GW
 SG_ ENM60D_1_0_MSG_COUNTER : 8|4@1+ (1,0) [0|15] ""  MVS,RCR_L,SNR,ADAS,MET,C_ECU_GW
 SG_ ENM60D_0_0_CHECK_SUM : 0|8@1+ (1,0) [0|255] ""  MVS,RCR_L,SNR,ADAS,MET,C_ECU_GW

BO_ 1548 ENM60C: 32 ENM
 SG_ ENM60C_27_2_VEHPWRTRIPLOG : 218|27@1+ (0.01,0) [0|999999.99] "kWh"  C_ECU_GW
 SG_ ENM60C_26_0_HVBWIN : 208|10@1+ (1,0) [0|999] "kW"  C_ECU_GW
 SG_ ENM60C_24_6_THMADJPRDWIN : 198|10@1+ (1,0) [0|100] "%"  C_ECU_GW
 SG_ ENM60C_23_3_ACNOFF_DRVRANG : 187|11@1+ (1,0) [0|1999] "km"  MET,C_ECU_GW
 SG_ ENM60C_22_0_ACNON_DRVRANG : 176|11@1+ (1,0) [0|1999] "km"  MET,C_ECU_GW
 SG_ ENM60C_21_2_HVBTEMPSTT : 170|3@1+ (1,0) [0|7] ""  MET,C_ECU_GW
 SG_ ENM60C_20_4_OUTLMTDISREQ : 164|3@1+ (1,0) [0|7] ""  MET,C_ECU_GW
 SG_ ENM60C_20_7_CHGLMTDISREQ : 167|3@1+ (1,0) [0|7] ""  MET,C_ECU_GW
 SG_ ENM60C_19_1_VEHPWREFF_TRIPB : 153|11@1+ (0.1,0) [0|19.9] "km/kWh"  MET,C_ECU_GW
 SG_ ENM60C_17_6_VEHPWREFF_TRIPA : 142|11@1+ (0.1,0) [0|19.9] "km/kWh"  MET,C_ECU_GW
 SG_ ENM60C_16_3_VEHPWREFF_ODO : 131|11@1+ (0.1,0) [0|19.9] "km/kWh"  C_ECU_GW
 SG_ ENM60C_15_0_VEHPWREFF : 120|11@1+ (0.1,0) [0|19.9] "km/kWh"  MET,C_ECU_GW
 SG_ ENM60C_14_0_PRCNSTT : 112|2@1+ (1,0) [0|3] ""  C_ECU_GW
 SG_ ENM60C_14_2_PRCNSTTFBK : 114|2@1+ (1,0) [0|3] ""  C_ECU_GW
 SG_ ENM60C_14_4_ACNLMTDISREQ : 116|3@1+ (1,0) [0|7] ""  MET,C_ECU_GW
 SG_ ENM60C_13_0_STCTDISPREQ : 104|3@1+ (1,0) [0|7] ""  C_ECU_GW
 SG_ ENM60C_13_3_VEHPRDDIS_JDG : 107|3@1+ (1,0) [0|7] ""  MET,C_ECU_GW
 SG_ ENM60C_13_6_PFOMDJDG : 110|2@1+ (1,0) [0|3] ""  C_ECU_GW
 SG_ ENM60C_12_0_HVBTEMP : 96|8@1+ (0.5,-40) [-40|87.5] "℃"  C_ECU_GW
 SG_ ENM60C_11_0_HVBTGTTEMP : 88|8@1+ (0.5,-40) [-40|87.5] "℃"  C_ECU_GW
 SG_ ENM60C_10_0_PFOMDSTP : 80|3@1+ (1,0) [0|7] ""  C_ECU_GW
 SG_ ENM60C_10_3_HVBTHMADJSTT : 83|3@1+ (1,0) [0|7] ""  MET,C_ECU_GW
 SG_ ENM60C_10_6_PFOMDCNTN : 86|1@1+ (1,0) [0|1] ""  C_ECU_GW
 SG_ THM60C_10_7_PWRMDJDG : 87|1@1+ (1,0) [0|1] ""  C_ECU_GW
 SG_ ENM60C_9_0_ENHCHGTIM : 72|8@1+ (1,0) [0|240] "min"  MET,C_ECU_GW
 SG_ ENM60C_8_0_THMADJTIM_PRCNSW : 64|8@1+ (1,0) [0|240] "min"  C_ECU_GW
 SG_ ENM60C_7_0_THMADJPRDSOC : 56|8@1+ (1,0) [0|100] "%"  C_ECU_GW
 SG_ ENM60C_6_0_HVBTHMADJPWR : 48|8@1+ (0.1,0) [0|25] "kW"  MET,C_ECU_GW
 SG_ ENM60C_5_0_THMADJTIM_PFOMD : 40|8@1+ (1,0) [0|255] "min"  C_ECU_GW
 SG_ ENM60C_4_0_HVBTHMADJTIM : 32|8@1+ (1,0) [0|240] "min"  MET,C_ECU_GW
 SG_ ENM60C_3_1_TRLSTSDISREQ : 25|2@1+ (1,0) [0|3] ""  C_ECU_GW
 SG_ ENM60C_3_3_TOWMDFAILDISREQ : 27|1@1+ (1,0) [0|1] ""  C_ECU_GW
 SG_ ENM60C_3_6_CHGTIPDISPREQ : 30|2@1+ (1,0) [0|3] ""  C_ECU_GW
 SG_ ENM60C_2_0_E2E_COUNTER : 16|8@1+ (1,0) [0|255] ""  MET,C_ECU_GW
 SG_ ENM60C_0_0_E2E_CRC : 0|16@1+ (1,0) [0|65535] ""  MET,C_ECU_GW

BO_ 857 THM359: 8 THM
 SG_ THM359_5_1_HVBOUTLTEMPREL : 41|2@1+ (1,0) [0|3] ""  C_ECU_GW
 SG_ THM359_4_0_HVBOUTLTEMP : 32|9@1+ (0.5,-40) [-40|215.5] "℃"  C_ECU_GW
 SG_ THM359_3_1_HVBINLTEMPREL : 25|2@1+ (1,0) [0|3] ""  C_ECU_GW
 SG_ THM359_3_3_IJDRMDTRFREQ : 27|1@1+ (1,0) [0|1] ""  C_ECU_GW
 SG_ THM359_2_0_HVBINLTEMP : 16|9@1+ (0.5,-40) [-40|215.5] "℃"  C_ECU_GW
 SG_ THM359_1_0_MSG_COUNTER : 8|4@1+ (1,0) [0|15] ""  C_ECU_GW
 SG_ THM359_0_0_CHECK_SUM : 0|8@1+ (1,0) [0|255] ""  C_ECU_GW

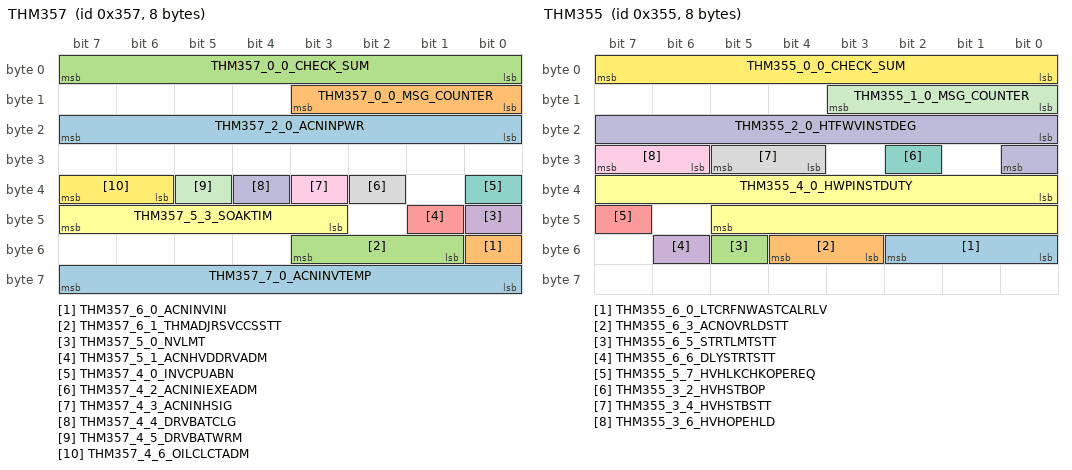
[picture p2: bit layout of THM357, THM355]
BO_ 855 THM357: 8 THM
 SG_ THM357_7_0_ACNINVTEMP : 56|8@1+ (1,-60) [-60|195] "℃"  C_ECU_GW
 SG_ THM357_6_0_ACNINVINI : 48|1@1+ (1,0) [0|1] ""  C_ECU_GW
 SG_ THM357_6_1_THMADJRSVCCSSTT : 49|3@1+ (1,0) [0|7] ""  C_ECU_GW
 SG_ THM357_5_0_NVLMT : 40|1@1+ (1,0) [0|1] ""  C_ECU_GW
 SG_ THM357_5_1_ACNHVDDRVADM : 41|1@1+ (1,0) [0|1] ""  C_ECU_GW
 SG_ THM357_5_3_SOAKTIM : 43|5@1+ (1,0) [0|31] "Hr"  C_ECU_GW
 SG_ THM357_4_0_INVCPUABN : 32|1@1+ (1,0) [0|1] ""  C_ECU_GW
 SG_ THM357_4_2_ACNINIEXEADM : 34|1@1+ (1,0) [0|1] ""  C_ECU_GW
 SG_ THM357_4_3_ACNINHSIG : 35|1@1+ (1,0) [0|1] ""  C_ECU_GW
 SG_ THM357_4_4_DRVBATCLG : 36|1@1+ (1,0) [0|1] ""  C_ECU_GW
 SG_ THM357_4_5_DRVBATWRM : 37|1@1+ (1,0) [0|1] ""  C_ECU_GW
 SG_ THM357_4_6_OILCLCTADM : 38|2@1+ (1,0) [0|3] ""  C_ECU_GW
 SG_ THM357_2_0_ACNINPWR : 16|8@1+ (50,0) [0|12750] "W"  C_ECU_GW
 SG_ THM357_0_0_MSG_COUNTER : 8|4@1+ (1,0) [0|15] ""  C_ECU_GW
 SG_ THM357_0_0_CHECK_SUM : 0|8@1+ (1,0) [0|255] ""  C_ECU_GW

BO_ 854 THM356: 8 THM
 SG_ THM356_7_0_INVTEMPSNSABN : 56|1@1+ (1,0) [0|1] ""  C_ECU_GW
 SG_ THM356_7_1_STBSTT : 57|1@1+ (1,0) [0|1] ""  C_ECU_GW
 SG_ THM356_7_2_INVINTERR : 58|2@1+ (1,0) [0|3] ""  C_ECU_GW
 SG_ THM356_7_4_SELFINVCHK : 60|1@1+ (1,0) [0|1] ""  C_ECU_GW
 SG_ THM356_7_5_INVINTPWRABN : 61|2@1+ (1,0) [0|3] ""  C_ECU_GW
 SG_ THM356_6_0_INVCURSNSABN : 48|1@1+ (1,0) [0|1] ""  C_ECU_GW
 SG_ THM356_6_1_ACNMOTCTRLABN : 49|2@1+ (1,0) [0|3] ""  C_ECU_GW
 SG_ THM356_6_3_ACNCMNSTT_INV : 51|1@1+ (1,0) [0|1] ""  C_ECU_GW
 SG_ THM356_6_4_CMPSTT : 52|3@1+ (1,0) [0|7] ""  C_ECU_GW
 SG_ THM356_6_7_RESLOTEMPABN : 55|1@1+ (1,0) [0|1] ""  C_ECU_GW
 SG_ THM356_5_2_FRCDAIRCYCLREQ : 42|1@1+ (1,0) [0|1] ""  C_ECU_GW
 SG_ THM356_5_3_ACNCMNSTT_ICU : 43|1@1+ (1,0) [0|1] ""  C_ECU_GW
 SG_ THM356_5_4_INVMAINVLTDIAG : 44|2@1+ (1,0) [0|3] ""  C_ECU_GW
 SG_ THM356_5_6_INVOVRHEAT : 46|2@1+ (1,0) [0|3] ""  C_ECU_GW
 SG_ THM356_4_0_ACNSYSADMPWR : 32|10@1+ (50,0) [0|17400] "W"  C_ECU_GW
 SG_ THM356_2_0_ACNMOTSPD : 16|16@1+ (1,0) [0|65535] "rpm"  C_ECU_GW
 SG_ THM356_1_0_MSG_COUNTER : 8|4@1+ (1,0) [0|15] ""  C_ECU_GW
 SG_ THM356_0_0_CHECK_SUM : 0|8@1+ (1,0) [0|255] ""  C_ECU_GW

BO_ 853 THM355: 8 THM
 SG_ THM355_6_0_LTCRFNWASTCALRLV : 48|3@1+ (1,0) [0|7] ""  C_ECU_GW
 SG_ THM355_6_3_ACNOVRLDSTT : 51|2@1+ (1,0) [0|3] ""  C_ECU_GW
 SG_ THM355_6_5_STRTLMTSTT : 53|1@1+ (1,0) [0|1] ""  C_ECU_GW
 SG_ THM355_6_6_DLYSTRTSTT : 54|1@1+ (1,0) [0|1] ""  C_ECU_GW
 SG_ THM355_5_7_HVHLKCHKOPEREQ : 47|1@1+ (1,0) [0|1] ""  C_ECU_GW
 SG_ THM355_4_0_HWPINSTDUTY : 32|14@1+ (0.006103515625,0) [0|100] "%"  C_ECU_GW
 SG_ THM355_3_2_HVHSTBOP : 26|1@1+ (1,0) [0|1] ""  C_ECU_GW
 SG_ THM355_3_4_HVHSTBSTT : 28|2@1+ (1,0) [0|3] ""  C_ECU_GW
 SG_ THM355_3_6_HVHOPEHLD : 30|2@1+ (1,0) [0|3] ""  C_ECU_GW
 SG_ THM355_2_0_HTFWVINSTDEG : 16|9@1+ (1,0) [0|360] "deg"  C_ECU_GW
 SG_ THM355_1_0_MSG_COUNTER : 8|4@1+ (1,0) [0|15] ""  C_ECU_GW
 SG_ THM355_0_0_CHECK_SUM : 0|8@1+ (1,0) [0|255] ""  C_ECU_GW

BO_ 852 THM354: 8 THM
 SG_ THM354_7_0_HVHCLTPHI : 56|1@1+ (1,0) [0|1] ""  C_ECU_GW
 SG_ THM354_7_5_HVHOVHTSTT : 61|1@1+ (1,0) [0|1] ""  C_ECU_GW
 SG_ THM354_7_7_HVHINTCMNABN : 63|1@1+ (1,0) [0|1] ""  C_ECU_GW
 SG_ THM354_6_0_HVHVLT : 48|8@1+ (0.1,0) [0|25.5] "V"  C_ECU_GW
 SG_ THM354_5_0_HVHACTCNSPCUR : 40|8@1+ (0.25,0) [0|63.75] "A"  C_ECU_GW
 SG_ THM354_4_0_HVHINLCLTP : 32|8@1+ (1,-40) [-40|215] "℃"  C_ECU_GW
 SG_ THM354_3_0_HVHOUTLCLTP : 24|8@1+ (1,-40) [-40|215] "℃"  C_ECU_GW
 SG_ THM354_2_0_HVHIGBTABN : 16|1@1+ (1,0) [0|1] ""  C_ECU_GW
 SG_ THM354_2_1_HVHSTBSTT : 17|2@1+ (1,0) [0|3] ""  C_ECU_GW
 SG_ THM354_2_3_HVHMEMABN : 19|1@1+ (1,0) [0|1] ""  C_ECU_GW
 SG_ THM354_2_4_HVHSERVREQ : 20|1@1+ (1,0) [0|1] ""  C_ECU_GW
 SG_ THM354_2_5_HVHSTTFBK : 21|3@1+ (1,0) [0|7] ""  C_ECU_GW
 SG_ THM354_1_0_MSG_COUNTER : 8|4@1+ (1,0) [0|15] ""  C_ECU_GW
 SG_ THM354_1_4_HVHINLCLTPABN : 12|1@1+ (1,0) [0|1] ""  C_ECU_GW
 SG_ THM354_1_5_HVHOUTLCLTPABN : 13|1@1+ (1,0) [0|1] ""  C_ECU_GW
 SG_ THM354_1_6_HVHOVHTABN : 14|1@1+ (1,0) [0|1] ""  C_ECU_GW
 SG_ THM354_1_7_HVHLINABN : 15|1@1+ (1,0) [0|1] ""  C_ECU_GW
 SG_ THM354_0_0_CHECK_SUM : 0|8@1+ (1,0) [0|255] ""  C_ECU_GW

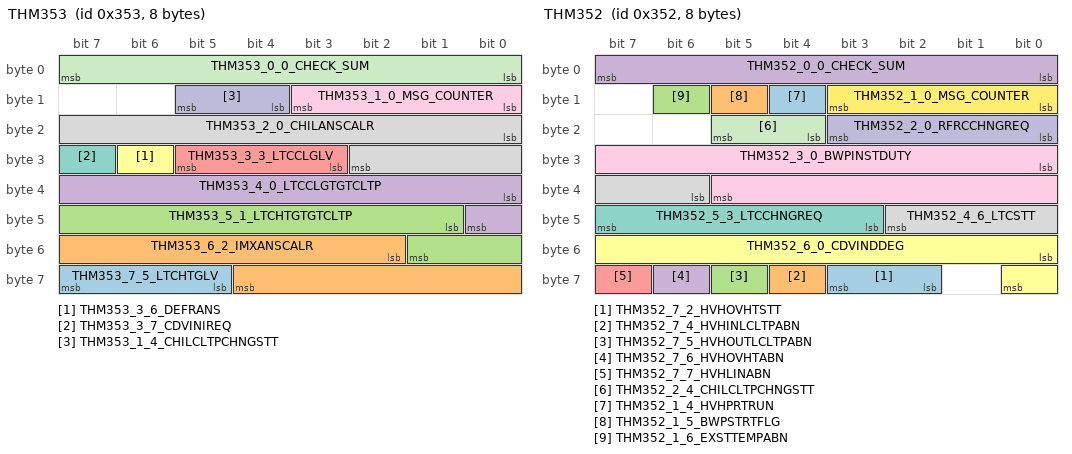
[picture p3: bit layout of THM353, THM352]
BO_ 851 THM353: 8 THM
 SG_ THM353_7_5_LTCHTGLV : 61|3@1+ (1,0) [0|7] ""  C_ECU_GW
 SG_ THM353_6_2_IMXANSCALR : 50|11@1+ (10,0) [0|20470] "W"  C_ECU_GW
 SG_ THM353_5_1_LTCHTGTGTCLTP : 41|9@1+ (0.5,-40) [-40|215.5] "℃"  C_ECU_GW
 SG_ THM353_4_0_LTCCLGTGTCLTP : 32|9@1+ (0.5,-40) [-40|215.5] "℃"  C_ECU_GW
 SG_ THM353_3_3_LTCCLGLV : 27|3@1+ (1,0) [0|7] ""  C_ECU_GW
 SG_ THM353_3_6_DEFRANS : 30|1@1+ (1,0) [0|1] ""  C_ECU_GW
 SG_ THM353_3_7_CDVINIREQ : 31|1@1+ (1,0) [0|1] ""  C_ECU_GW
 SG_ THM353_2_0_CHILANSCALR : 16|11@1+ (10,0) [0|20470] "W"  C_ECU_GW
 SG_ THM353_1_0_MSG_COUNTER : 8|4@1+ (1,0) [0|15] ""  C_ECU_GW
 SG_ THM353_1_4_CHILCLTPCHNGSTT : 12|2@1+ (1,0) [0|3] ""  C_ECU_GW
 SG_ THM353_0_0_CHECK_SUM : 0|8@1+ (1,0) [0|255] ""  C_ECU_GW

BO_ 850 THM352: 8 THM
 SG_ THM352_7_2_HVHOVHTSTT : 58|2@1+ (1,0) [0|1] ""  C_ECU_GW
 SG_ THM352_7_4_HVHINLCLTPABN : 60|1@1+ (1,0) [0|1] ""  C_ECU_GW
 SG_ THM352_7_5_HVHOUTLCLTPABN : 61|1@1+ (1,0) [0|1] ""  C_ECU_GW
 SG_ THM352_7_6_HVHOVHTABN : 62|1@1+ (1,0) [0|1] ""  C_ECU_GW
 SG_ THM352_7_7_HVHLINABN : 63|1@1+ (1,0) [0|1] ""  C_ECU_GW
 SG_ THM352_6_0_CDVINDDEG : 48|9@1+ (1,0) [0|360] "deg"  C_ECU_GW
 SG_ THM352_5_3_LTCCHNGREQ : 43|5@1+ (1,0) [0|13] ""  C_ECU_GW
 SG_ THM352_4_6_LTCSTT : 38|5@1+ (1,0) [0|13] ""  C_ECU_GW
 SG_ THM352_3_0_BWPINSTDUTY : 24|14@1+ (0.006103515625,0) [0|100] "%"  C_ECU_GW
 SG_ THM352_2_0_RFRCCHNGREQ : 16|4@1+ (1,0) [0|8] ""  C_ECU_GW
 SG_ THM352_2_4_CHILCLTPCHNGSTT : 20|2@1+ (1,0) [0|3] ""  C_ECU_GW
 SG_ THM352_1_0_MSG_COUNTER : 8|4@1+ (1,0) [0|15] ""  C_ECU_GW
 SG_ THM352_1_4_HVHPRTRUN : 12|1@1+ (1,0) [0|1] ""  C_ECU_GW
 SG_ THM352_1_5_BWPSTRTFLG : 13|1@1+ (1,0) [0|1] ""  C_ECU_GW
 SG_ THM352_1_6_EXSTTEMPABN : 14|1@1+ (1,0) [0|1] ""  C_ECU_GW
 SG_ THM352_0_0_CHECK_SUM : 0|8@1+ (1,0) [0|255] ""  C_ECU_GW

BO_ 1485 CHR5CD: 32 CHR
 SG_ CHR5CD_27_0_EVSE_ID_7_CHR : 216|32@1+ (1,0) [0|31] ""  C_ECU_GW
 SG_ CHR5CD_23_0_EVSE_ID_6_CHR : 184|32@1+ (1,0) [0|31] ""  C_ECU_GW
 SG_ CHR5CD_19_0_EVSE_ID_5_CHR : 152|32@1+ (1,0) [0|31] ""  C_ECU_GW
 SG_ CHR5CD_15_0_EVSE_ID_4_CHR : 120|32@1+ (1,0) [0|31] ""  C_ECU_GW
 SG_ CHR5CD_11_0_EVSE_ID_3_CHR : 88|32@1+ (1,0) [0|31] ""  C_ECU_GW
 SG_ CHR5CD_7_0_EVSE_ID_2_CHR : 56|32@1+ (1,0) [0|31] ""  C_ECU_GW
 SG_ CHR5CD_3_0_EVSE_ID_1_CHR : 24|32@1+ (1,0) [0|31] ""  C_ECU_GW
 SG_ CHR5CD_2_0_E2E_COUNTER : 16|8@1+ (1,0) [0|255] ""  C_ECU_GW
 SG_ CHR5CD_0_0_E2E_CRC : 0|16@1+ (1,0) [0|65535] ""  C_ECU_GW

BO_ 1116 CHR45C: 32 CHR
 SG_ CHR45C_29_0_BYTE21 : 232|8@1+ (1,0) [0|255] ""  MET,C_ECU_GW
 SG_ CHR45C_28_0_BYTE20 : 224|8@1+ (1,0) [0|255] ""  MET,C_ECU_GW
 SG_ CHR45C_27_0_BYTE19 : 216|8@1+ (1,0) [0|255] ""  MET,C_ECU_GW
 SG_ CHR45C_26_0_BYTE18 : 208|8@1+ (1,0) [0|255] ""  MET,C_ECU_GW
 SG_ CHR45C_25_0_BYTE17 : 200|8@1+ (1,0) [0|255] ""  MET,C_ECU_GW
 SG_ CHR45C_24_0_BYTE16 : 192|8@1+ (1,0) [0|255] ""  MET,C_ECU_GW
 SG_ CHR45C_23_0_BYTE15 : 184|8@1+ (1,0) [0|255] ""  MET,C_ECU_GW
 SG_ CHR45C_22_0_BYTE14 : 176|8@1+ (1,0) [0|255] ""  MET,C_ECU_GW
 SG_ CHR45C_21_0_BYTE13 : 168|8@1+ (1,0) [0|255] ""  MET,C_ECU_GW
 SG_ CHR45C_20_0_BYTE12 : 160|8@1+ (1,0) [0|255] ""  MET,C_ECU_GW
 SG_ CHR45C_19_0_BYTE11 : 152|8@1+ (1,0) [0|255] ""  MET,C_ECU_GW
 SG_ CHR45C_18_0_BYTE10 : 144|8@1+ (1,0) [0|255] ""  MET,C_ECU_GW
 SG_ CHR45C_17_0_BYTE9 : 136|8@1+ (1,0) [0|255] ""  MET,C_ECU_GW
 SG_ CHR45C_16_0_BYTE8 : 128|8@1+ (1,0) [0|255] ""  MET,C_ECU_GW
 SG_ CHR45C_15_0_BYTE7 : 120|8@1+ (1,0) [0|255] ""  MET,C_ECU_GW
 SG_ CHR45C_14_0_BYTE6 : 112|8@1+ (1,0) [0|255] ""  MET,C_ECU_GW
 SG_ CHR45C_13_0_BYTE5 : 104|8@1+ (1,0) [0|255] ""  MET,C_ECU_GW
 SG_ CHR45C_12_0_BYTE4 : 96|8@1+ (1,0) [0|255] ""  MET,C_ECU_GW
 SG_ CHR45C_11_0_BYTE3 : 88|8@1+ (1,0) [0|255] ""  MET,C_ECU_GW
 SG_ CHR45C_10_0_BYTE2 : 80|8@1+ (1,0) [0|255] ""  MET,C_ECU_GW
 SG_ CHR45C_9_0_LIDLOCK_DISC_DT : 72|2@1+ (1,0) [0|3] ""  C_ECU,C_ECU_GW
 SG_ CHR45C_9_2_LIDOP : 74|2@1+ (1,0) [0|3] ""  MET,C_ECU,C_ECU_GW
 SG_ CHR45C_8_3_CHGSTARTSTOP : 67|4@1+ (1,0) [0|15] ""  MET,C_ECU_GW
 SG_ CHR45C_8_2_LIDOP_BUZ_REQ : 66|1@1+ (1,0) [0|1] ""  MET,C_ECU_GW
 SG_ CHR45C_8_1_LIDOP_WARDISP_REQ : 65|1@1+ (1,0) [0|1] ""  MET,C_ECU_GW
 SG_ CHR45C_8_0_CHG_CNRCNTSTT : 64|1@1+ (1,0) [0|1] ""  MET,C_ECU_GW
 SG_ CHR45C_6_0_FEDPWR_DISP : 48|16@1+ (1,0) [0|65535] "kW"  MET,C_ECU_GW
 SG_ CHR45C_4_0_CHGPWR_DISP : 32|16@1+ (1,0) [0|65535] "kW"  MET,C_ECU_GW
 SG_ CHR45C_3_0_CHGFEDSTT : 24|8@1+ (1,0) [0|6] ""  MET,C_ECU_GW
 SG_ CHR45C_2_0_E2E_COUNTER : 16|8@1+ (1,0) [0|255] ""  MET,C_ECU_GW
 SG_ CHR45C_0_0_E2E_CRC : 0|16@1+ (1,0) [0|65535] ""  MET,C_ECU_GW

BO_ 1111 CHR457: 32 CHR
 SG_ CHR457_31_0_BYTE29 : 248|8@1+ (1,0) [0|255] ""  C_ECU_GW
 SG_ CHR457_30_0_BYTE28 : 240|8@1+ (1,0) [0|255] ""  C_ECU_GW
 SG_ CHR457_29_0_BYTE27 : 232|8@1+ (1,0) [0|255] ""  C_ECU_GW
 SG_ CHR457_28_0_BYTE26 : 224|8@1+ (1,0) [0|255] ""  C_ECU_GW
 SG_ CHR457_27_0_BYTE25 : 216|8@1+ (1,0) [0|255] ""  C_ECU_GW
 SG_ CHR457_26_0_BYTE24 : 208|8@1+ (1,0) [0|255] ""  C_ECU_GW
 SG_ CHR457_25_0_BYTE23 : 200|8@1+ (1,0) [0|255] ""  C_ECU_GW
 SG_ CHR457_24_0_BYTE22 : 192|8@1+ (1,0) [0|255] ""  C_ECU_GW
 SG_ CHR457_23_0_BYTE21 : 184|8@1+ (1,0) [0|255] ""  C_ECU_GW
 SG_ CHR457_22_0_BYTE20 : 176|8@1+ (1,0) [0|255] ""  C_ECU_GW
 SG_ CHR457_21_0_BYTE19 : 168|8@1+ (1,0) [0|255] ""  C_ECU_GW
 SG_ CHR457_20_0_BYTE18 : 160|8@1+ (1,0) [0|255] ""  C_ECU_GW
 SG_ CHR457_19_0_BYTE17 : 152|8@1+ (1,0) [0|255] ""  C_ECU_GW
 SG_ CHR457_18_0_BYTE16 : 144|8@1+ (1,0) [0|255] ""  C_ECU_GW
 SG_ CHR457_17_0_BYTE15 : 136|8@1+ (1,0) [0|255] ""  C_ECU_GW
 SG_ CHR457_16_0_BYTE14 : 128|8@1+ (1,0) [0|255] ""  C_ECU_GW
 SG_ CHR457_15_0_BYTE13 : 120|8@1+ (1,0) [0|255] ""  C_ECU_GW
 SG_ CHR457_14_0_BYTE12 : 112|8@1+ (1,0) [0|255] ""  C_ECU_GW
 SG_ CHR457_13_0_BYTE11 : 104|8@1+ (1,0) [0|255] ""  C_ECU_GW
 SG_ CHR457_12_6_ENERGY_CHARGED_DISP : 102|16@1+ (1,0) [0|65535] "kWh"  C_ECU_GW
 SG_ CHR457_11_7_DLTSOCCALC_FIN : 95|7@1+ (1,0) [0|127] "%"  C_ECU_GW
 SG_ CHR457_11_0_DLTSOCCALC_STRT : 88|7@1+ (1,0) [0|127] "%"  C_ECU_GW
 SG_ CHR457_10_6_STLMT_TYPE : 86|2@1+ (1,0) [0|2] ""  C_ECU_GW
 SG_ CHR457_10_4_ACDC_INFO : 84|2@1+ (1,0) [0|2] ""  C_ECU_GW
 SG_ CHR457_9_0_CHGTIM : 72|12@1+ (1,0) [0|63] "min"  C_ECU_GW
 SG_ CHR457_8_0_BYTE6 : 64|8@1+ (1,0) [0|255] ""  C_ECU_GW
 SG_ CHR457_7_0_BYTE5 : 56|8@1+ (1,0) [0|255] ""  C_ECU_GW
 SG_ CHR457_6_4_DCPWRSUPSTOP_DISP : 52|4@1+ (1,0) [0|1] ""  C_ECU_GW
 SG_ CHR457_6_0_DCPWRSUPSTRT_DISP : 48|4@1+ (1,0) [0|1] ""  C_ECU_GW
 SG_ CHR457_5_0_CHGSTRTNTCE_DISP : 40|4@1+ (1,0) [0|1] ""  C_ECU_GW
 SG_ CHR457_5_4_CHGENDNTCE_DISP : 44|4@1+ (1,0) [0|1] ""  C_ECU_GW
 SG_ CHR457_4_0_FEDSTPRSN_DISP : 32|8@1+ (1,0) [0|255] ""  MET,C_ECU_GW
 SG_ CHR457_3_0_CHGSTPRSN_DISP : 24|8@1+ (1,0) [0|255] ""  MET,C_ECU_GW
 SG_ CHR457_2_0_E2E_COUNTER : 16|8@1+ (1,0) [0|255] ""  C_ECU_GW
 SG_ CHR457_0_0_E2E_CRC : 0|16@1+ (1,0) [0|65535] ""  C_ECU_GW

BO_ 1109 CHR455: 32 CHR
 SG_ CHR455_31_3_CHGCNRLOCSTT_DISPREQ : 251|2@1+ (1,0) [0|2] ""  MET,C_ECU_GW
 SG_ CHR455_28_4_VEH_CHGPWRUPLMT : 228|17@1+ (1,0) [0|131071] "kW"  MET,C_ECU_GW
 SG_ CHR455_27_4_V2H_MODE : 220|8@1+ (1,0) [0|1] ""  MET,C_ECU_GW
 SG_ CHR455_26_4_DCPWRSUPSTT : 212|8@1+ (1,0) [0|255] ""  MET,C_ECU_GW
 SG_ CHR455_26_3_CHGMNTDISP_REQ : 211|1@1+ (1,0) [0|1] ""  MET,C_ECU_GW
 SG_ CHR455_26_2_MNTLIT_REQ : 210|1@1+ (1,0) [0|1] ""  MET,C_ECU_GW
 SG_ CHR455_25_0_CHGVLT_DISP : 200|10@1+ (1,0) [0|1023] "V"  MET,C_ECU_GW
 SG_ CHR455_23_0_CHGCUR_DISP : 184|16@1+ (1,0) [0|65535] "A"  MET,C_ECU_GW
 SG_ CHR455_22_1_CHGSTPCOMP : 177|1@1+ (1,0) [0|1] ""  C_ECU_GW
 SG_ CHR455_20_1_ENERGY_CHARGED_DISP : 161|16@1+ (1,0) [0|65535] "kWh"  C_ECU_GW
 SG_ CHR455_19_2_DLTSOCCALC_FIN : 154|7@1+ (1,0) [0|127] "%"  C_ECU_GW
 SG_ CHR455_18_3_DLTSOCCALC_STRT : 147|7@1+ (1,0) [0|127] "%"  C_ECU_GW
 SG_ CHR455_18_2_STLMT_TYPE : 146|1@1+ (1,0) [0|1] ""  C_ECU_GW
 SG_ CHR455_18_1_ACDC_INFO : 145|1@1+ (1,0) [0|1] ""  C_ECU_GW
 SG_ CHR455_16_6_EVSEOUTPWR : 134|10@1+ (1,0) [0|1023] "kW"  MET,C_ECU_GW
 SG_ CHR455_13_3_CHG_FINTIM : 107|27@1+ (1,0) [0|134217727] ""  C_ECU_GW
 SG_ CHR455_12_0_CHGTIM : 96|12@1+ (1,0) [0|63] "min"  C_ECU_GW
 SG_ CHR455_10_7_DCPWRSUP_PWR_DISP : 87|8@1+ (1,0) [0|255] "kW"  MET,C_ECU_GW
 SG_ CHR455_8_7_CHGPWR_DISP : 71|16@1+ (1,0) [0|65535] "kW"  C_ECU_GW
 SG_ CHR455_7_1_DCPWRSUP_ADMTIM : 57|14@1+ (1,0) [0|16383] "min"  MET,C_ECU_GW
 SG_ CHR455_6_1_CHGSTT : 49|8@1+ (1,0) [0|255] ""  MET,C_ECU_GW
 SG_ CHR455_5_2_FED_LOLMT : 42|7@1+ (1,0) [0|100] "%"  C_ECU_GW
 SG_ CHR455_4_6_DCCHG_PWRUPLMT : 38|4@1+ (1,0) [0|15] ""  C_ECU_GW
 SG_ CHR455_4_2_ACCHG_CURUPLMT : 34|4@1+ (1,0) [0|15] ""  C_ECU_GW
 SG_ CHR455_3_3_CHG_HILMT : 27|7@1+ (1,0) [0|127] "%"  MET,C_ECU_GW
 SG_ CHR455_3_1_CHG_CNRLOCSTT : 25|2@1+ (1,0) [0|3] ""  MET,C_ECU_GW
 SG_ CHR455_3_0_CHG_CNRCNTSTT : 24|1@1+ (1,0) [0|1] ""  MET,C_ECU_GW
 SG_ CHR455_2_0_E2E_COUNTER : 16|8@1+ (1,0) [0|255] ""  C_ECU_GW
 SG_ CHR455_0_0_E2E_CRC : 0|16@1+ (1,0) [0|65535] ""  C_ECU_GW

BO_ 1547 BAT60B: 32 BAT
 SG_ BAT60B_8_0_EXWATTMPERR_CNTR : 64|1@1+ (1,0) [0|1] "" Vector__XXX
 SG_ BAT60B_7_7_SNSWATTMPERR_CNTR : 63|1@1+ (1,0) [0|1] "" Vector__XXX
 SG_ BAT60B_7_6_SNSSMKEMSERR_CNTR : 62|1@1+ (1,0) [0|1] "" Vector__XXX
 SG_ BAT60B_7_5_SNSEXTMP2ERR_CNTR : 61|1@1+ (1,0) [0|1] "" Vector__XXX
 SG_ BAT60B_7_4_SNSEXTMP1ERR_CNTR : 60|1@1+ (1,0) [0|1] "" Vector__XXX
 SG_ BAT60B_7_3_DEVTSTCK3ERR_CNTR : 59|1@1+ (1,0) [0|1] "" Vector__XXX
 SG_ BAT60B_7_2_DEVTSTCK2ERR_CNTR : 58|1@1+ (1,0) [0|1] "" Vector__XXX
 SG_ BAT60B_7_1_DEVTSTCK1ERR_CNTR : 57|1@1+ (1,0) [0|1] "" Vector__XXX
 SG_ BAT60B_7_0_OVERTLVL2ERR_CNTR : 56|1@1+ (1,0) [0|1] "" Vector__XXX
 SG_ BAT60B_6_7_OVERTLVL1ERR_CNTR : 55|1@1+ (1,0) [0|1] "" Vector__XXX
 SG_ BAT60B_6_6_RESDEVERR_CNTR : 54|1@1+ (1,0) [0|1] "" Vector__XXX
 SG_ BAT60B_6_5_PWLINEOV6ERR_CNTR : 53|1@1+ (1,0) [0|1] "" Vector__XXX
 SG_ BAT60B_6_4_PWLINEOV5ERR_CNTR : 52|1@1+ (1,0) [0|1] "" Vector__XXX
 SG_ BAT60B_6_3_PWLINEOV4ERR_CNTR : 51|1@1+ (1,0) [0|1] "" Vector__XXX
 SG_ BAT60B_6_2_PWLINEOV3ERR_CNTR : 50|1@1+ (1,0) [0|1] "" Vector__XXX
 SG_ BAT60B_6_1_PWLINEOV2ERR_CNTR : 49|1@1+ (1,0) [0|1] "" Vector__XXX
 SG_ BAT60B_6_0_PWLINEOV1ERR_CNTR : 48|1@1+ (1,0) [0|1] "" Vector__XXX
 SG_ BAT60B_5_7_VWOUTOVERERR_CNTR : 47|1@1+ (1,0) [0|1] "" Vector__XXX
 SG_ BAT60B_5_6_VWINOVERERR_CNTR : 46|1@1+ (1,0) [0|1] "" Vector__XXX
 SG_ BAT60B_5_5_ACTESTDEVERR_CNTR : 45|1@1+ (1,0) [0|1] "" Vector__XXX
 SG_ BAT60B_5_4_RWOUTUNDERR_CNTR : 44|1@1+ (1,0) [0|1] "" Vector__XXX
 SG_ BAT60B_5_3_RWINOVRERR_CNTR : 43|1@1+ (1,0) [0|1] "" Vector__XXX
 SG_ BAT60B_5_2_HVOFFISOERR_CNTR : 42|1@1+ (1,0) [0|1] "" Vector__XXX
 SG_ BAT60B_5_1_HVONISOERR_CNTR : 41|1@1+ (1,0) [0|1] "" Vector__XXX
 SG_ BAT60B_5_0_HVSUMCOMPERR_CNTR : 40|1@1+ (1,0) [0|1] "" Vector__XXX
 SG_ BAT60B_4_7_CEUNDULV2ERR_CNTR : 39|1@1+ (1,0) [0|1] "" Vector__XXX
 SG_ BAT60B_4_6_CEOVRULV2ERR_CNTR : 38|1@1+ (1,0) [0|1] "" Vector__XXX
 SG_ BAT60B_4_5_ICHPEAKERR_CNTR : 37|1@1+ (1,0) [0|1] "" Vector__XXX
 SG_ BAT60B_4_4_IDCHAPEAKERR_CNTR : 36|1@1+ (1,0) [0|1] "" Vector__XXX
 SG_ BAT60B_4_3_HVOVRULV2ERR_CNTR : 35|1@1+ (1,0) [0|1] "" Vector__XXX
 SG_ BAT60B_4_2_HVUNDULV2ERR_CNTR : 34|1@1+ (1,0) [0|1] "" Vector__XXX
 SG_ BAT60B_4_1_CEUNDULV1ERR_CNTR : 33|1@1+ (1,0) [0|1] "" Vector__XXX
 SG_ BAT60B_4_0_CEOVRULV1ERR_CNTR : 32|1@1+ (1,0) [0|1] "" Vector__XXX
 SG_ BAT60B_3_7_HVOVRULV1ERR_CNTR : 31|1@1+ (1,0) [0|1] "" Vector__XXX
 SG_ BAT60B_3_6_CEUDIFDYNERR_CNTR : 30|1@1+ (1,0) [0|1] "" Vector__XXX
 SG_ BAT60B_3_5_OVERSOCERR_CNTR : 29|1@1+ (1,0) [0|1] "" Vector__XXX
 SG_ BAT60B_3_4_UNDERSOCERR_CNTR : 28|1@1+ (1,0) [0|1] "" Vector__XXX
 SG_ BAT60B_3_3_HVUNDULV1ERR_CNTR : 27|1@1+ (1,0) [0|1] "" Vector__XXX
 SG_ BAT60B_3_2_ISOMEASERR_CNTR : 26|1@1+ (1,0) [0|1] "" Vector__XXX
 SG_ BAT60B_3_1_CHGAWINOVERR_CNTR : 25|1@1+ (1,0) [0|1] "" Vector__XXX
 SG_ BAT60B_3_0_CEUHIDIFERR_CNTR : 24|1@1+ (1,0) [0|1] "" Vector__XXX
 SG_ BAT60B_2_0_E2E_COUNTER : 16|8@1+ (1,0) [0|255] "" Vector__XXX
 SG_ BAT60B_0_0_E2E_CRC : 0|16@1+ (1,0) [0|65535] "" Vector__XXX

BO_ 1546 BAT60A: 32 BAT
 SG_ BAT60A_29_4_LVB_VOL : 236|8@1+ (0.1,0) [0|25] "V"  C_ECU_GW
 SG_ BAT60A_29_3_EXWATTMPERR : 235|1@1+ (1,0) [0|1] ""  C_ECU_GW
 SG_ BAT60A_29_2_SNSWATTMPERR : 234|1@1+ (1,0) [0|1] ""  C_ECU_GW
 SG_ BAT60A_29_1_SNSSMKEMSERR : 233|1@1+ (1,0) [0|1] ""  C_ECU_GW
 SG_ BAT60A_29_0_SNSEXTMP2ERR : 232|1@1+ (1,0) [0|1] ""  C_ECU_GW
 SG_ BAT60A_28_7_SNSEXTMP1ERR : 231|1@1+ (1,0) [0|1] ""  C_ECU_GW
 SG_ BAT60A_28_6_DEVTSTCK3ERR : 230|1@1+ (1,0) [0|1] ""  C_ECU_GW
 SG_ BAT60A_28_5_DEVTSTCK2ERR : 229|1@1+ (1,0) [0|1] ""  C_ECU_GW
 SG_ BAT60A_28_4_DEVTSTCK1ERR : 228|1@1+ (1,0) [0|1] ""  C_ECU_GW
 SG_ BAT60A_28_3_OVERTLVL2ERR : 227|1@1+ (1,0) [0|1] ""  C_ECU_GW
 SG_ BAT60A_28_2_OVERTLVL1ERR : 226|1@1+ (1,0) [0|1] ""  C_ECU_GW
 SG_ BAT60A_28_1_RESDEVERR : 225|1@1+ (1,0) [0|1] ""  C_ECU_GW
 SG_ BAT60A_28_0_PWLINEOV6ERR : 224|1@1+ (1,0) [0|1] ""  C_ECU_GW
 SG_ BAT60A_27_7_PWLINEOV5ERR : 223|1@1+ (1,0) [0|1] ""  C_ECU_GW
 SG_ BAT60A_27_6_PWLINEOV4ERR : 222|1@1+ (1,0) [0|1] ""  C_ECU_GW
 SG_ BAT60A_27_5_PWLINEOV3ERR : 221|1@1+ (1,0) [0|1] ""  C_ECU_GW
 SG_ BAT60A_27_4_PWLINEOV2ERR : 220|1@1+ (1,0) [0|1] ""  C_ECU_GW
 SG_ BAT60A_27_3_PWLINEOV1ERR : 219|1@1+ (1,0) [0|1] ""  C_ECU_GW
 SG_ BAT60A_27_2_VWOUTOVERERR : 218|1@1+ (1,0) [0|1] ""  C_ECU_GW
 SG_ BAT60A_27_1_VWINOVERERR : 217|1@1+ (1,0) [0|1] ""  C_ECU_GW
 SG_ BAT60A_27_0_ACTESTDEVERR : 216|1@1+ (1,0) [0|1] ""  C_ECU_GW
 SG_ BAT60A_26_7_RWOUTUNDERR : 215|1@1+ (1,0) [0|1] ""  C_ECU_GW
 SG_ BAT60A_26_6_RWINOVRERR : 214|1@1+ (1,0) [0|1] ""  C_ECU_GW
 SG_ BAT60A_26_5_HVOFFISOERR : 213|1@1+ (1,0) [0|1] ""  C_ECU_GW
 SG_ BAT60A_26_4_HVONISOERR : 212|1@1+ (1,0) [0|1] ""  C_ECU_GW
 SG_ BAT60A_26_3_HVSUMCOMPERR : 211|1@1+ (1,0) [0|1] ""  C_ECU_GW
 SG_ BAT60A_26_2_CEUNDULV2ERR : 210|1@1+ (1,0) [0|1] ""  C_ECU_GW
 SG_ BAT60A_26_1_CEOVRULV2ERR : 209|1@1+ (1,0) [0|1] ""  C_ECU_GW
 SG_ BAT60A_26_0_ICHPEAKERR : 208|1@1+ (1,0) [0|1] ""  C_ECU_GW
 SG_ BAT60A_25_7_IDCHAPEAKERR : 207|1@1+ (1,0) [0|1] ""  C_ECU_GW
 SG_ BAT60A_25_6_HVOVRULV2ERR : 206|1@1+ (1,0) [0|1] ""  C_ECU_GW
 SG_ BAT60A_25_5_HVUNDULV2ERR : 205|1@1+ (1,0) [0|1] ""  C_ECU_GW
 SG_ BAT60A_25_4_CEUNDULV1ERR : 204|1@1+ (1,0) [0|1] ""  C_ECU_GW
 SG_ BAT60A_25_3_CEOVRULV1ERR : 203|1@1+ (1,0) [0|1] ""  C_ECU_GW
 SG_ BAT60A_25_2_HVOVRULV1ERR : 202|1@1+ (1,0) [0|1] ""  C_ECU_GW
 SG_ BAT60A_25_1_CEUDIFDYNERR : 201|1@1+ (1,0) [0|1] ""  C_ECU_GW
 SG_ BAT60A_25_0_OVERSOCERR : 200|1@1+ (1,0) [0|1] ""  C_ECU_GW
 SG_ BAT60A_24_7_UNDERSOCERR : 199|1@1+ (1,0) [0|1] ""  C_ECU_GW
 SG_ BAT60A_24_6_HVUNDULV1ERR : 198|1@1+ (1,0) [0|1] ""  C_ECU_GW
 SG_ BAT60A_24_5_ISOMEASERR : 197|1@1+ (1,0) [0|1] ""  C_ECU_GW
 SG_ BAT60A_24_4_CHGAWINOVERR : 196|1@1+ (1,0) [0|1] ""  C_ECU_GW
 SG_ BAT60A_24_3_CEUHIDIFERR : 195|1@1+ (1,0) [0|1] ""  C_ECU_GW
 SG_ BAT60A_23_6_HVB_OUTLIMFCT : 190|5@1+ (1,0) [0|30] ""  C_ECU_GW
 SG_ BAT60A_23_1_HVB_INLIMFCT : 185|5@1+ (1,0) [0|30] ""  C_ECU_GW
 SG_ BAT60A_22_4_HVB_WOUT : 180|10@1- (1,-510) [-510|511] "kW"  C_ECU_GW
 SG_ BAT60A_21_2_HVB_WIN : 170|10@1- (1,-510) [-510|511] "kW"  C_ECU_GW
 SG_ BAT60A_20_5_HVB_OPRMODE : 165|5@1+ (1,0) [0|30] ""  C_ECU_GW
 SG_ BAT60A_19_1_HVB_CELLSOHRMIN : 153|7@1+ (1,0) [0|100] "%"  C_ECU_GW
 SG_ BAT60A_18_2_HVB_CELLSOHRMAX : 146|7@1+ (1,0) [0|100] "%"  C_ECU_GW
 SG_ BAT60A_17_3_HVB_CELLSOHCMIN : 139|7@1+ (1,0) [0|100] "%"  C_ECU_GW
 SG_ BAT60A_16_4_HVB_CELLSOHCMAX : 132|7@1+ (1,0) [0|100] "%"  C_ECU_GW
 SG_ BAT60A_15_5_HVB_SOC : 125|7@1+ (1,0) [0|100] "%"  C_ECU_GW
 SG_ BAT60A_14_5_HVB_WATTEMP : 117|8@1- (1,-125) [-125|126] "℃"  C_ECU_GW
 SG_ BAT60A_13_5_JB_TEMPSNS : 109|8@1- (1,-125) [-125|126] "℃"  C_ECU_GW
 SG_ BAT60A_12_5_HVB_CELLTEMPMINNO : 101|8@1+ (1,0) [0|255] ""  C_ECU_GW
 SG_ BAT60A_11_5_HVB_CELLTEMPMAXNO : 93|8@1+ (1,0) [0|255] ""  C_ECU_GW
 SG_ BAT60A_10_5_HVB_CELLTEMPMIN : 85|8@1- (1,-125) [-125|126] "℃"  C_ECU_GW
 SG_ BAT60A_9_5_HVB_CELLTEMPMAX : 77|8@1- (1,-125) [-125|126] "℃"  C_ECU_GW
 SG_ BAT60A_8_2_HVB_CUR : 66|11@1- (1,-1020) [-1020|1021] "A"  C_ECU_GW
 SG_ BAT60A_7_2_HVB_CELLVOLMINNO : 58|8@1+ (1,0) [0|255] ""  C_ECU_GW
 SG_ BAT60A_6_2_HVB_CELLVOLMAXNO : 50|8@1+ (1,0) [0|255] ""  C_ECU_GW
 SG_ BAT60A_4_5_HVB_CELLVOLMIN : 37|13@1+ (1,0) [0|8190] "mV"  C_ECU_GW
 SG_ BAT60A_3_0_HVB_CELLVOLMAX : 24|13@1+ (1,0) [0|8190] "mV"  C_ECU_GW
 SG_ BAT60A_2_0_E2E_COUNTER : 16|8@1+ (1,0) [0|255] ""  C_ECU_GW
 SG_ BAT60A_0_0_E2E_CRC : 0|16@1+ (1,0) [0|65535] ""  C_ECU_GW

BO_ 1680 BAT690: 32 BAT
 SG_ BAT690_28_2_CHG_REMTI_GRF26 : 226|8@1+ (45,0) [0|10800] "sec"  C_ECU_GW
 SG_ BAT690_27_2_CHG_REMTI_GRF25 : 218|8@1+ (45,0) [0|10800] "sec"  C_ECU_GW
 SG_ BAT690_26_2_CHG_REMTI_GRF24 : 210|8@1+ (45,0) [0|10800] "sec"  C_ECU_GW
 SG_ BAT690_25_2_CHG_REMTI_GRF23 : 202|8@1+ (45,0) [0|10800] "sec"  C_ECU_GW
 SG_ BAT690_24_2_CHG_REMTI_GRF22 : 194|8@1+ (45,0) [0|10800] "sec"  C_ECU_GW
 SG_ BAT690_23_2_CHG_REMTI_GRF21 : 186|8@1+ (45,0) [0|10800] "sec"  C_ECU_GW
 SG_ BAT690_22_2_CHG_REMTI_GRF20 : 178|8@1+ (45,0) [0|10800] "sec"  C_ECU_GW
 SG_ BAT690_21_2_CHG_REMTI_GRF19 : 170|8@1+ (45,0) [0|10800] "sec"  C_ECU_GW
 SG_ BAT690_20_2_CHG_REMTI_GRF18 : 162|8@1+ (45,0) [0|10800] "sec"  C_ECU_GW
 SG_ BAT690_19_2_CHG_REMTI_GRF17 : 154|8@1+ (45,0) [0|10800] "sec"  C_ECU_GW
 SG_ BAT690_18_2_CHG_REMTI_GRF16 : 146|8@1+ (45,0) [0|10800] "sec"  C_ECU_GW
 SG_ BAT690_17_2_CHG_REMTI_GRF15 : 138|8@1+ (45,0) [0|10800] "sec"  C_ECU_GW
 SG_ BAT690_16_2_CHG_REMTI_GRF14 : 130|8@1+ (45,0) [0|10800] "sec"  C_ECU_GW
 SG_ BAT690_15_2_CHG_REMTI_GRF13 : 122|8@1+ (45,0) [0|10800] "sec"  C_ECU_GW
 SG_ BAT690_14_2_CHG_REMTI_GRF12 : 114|8@1+ (45,0) [0|10800] "sec"  C_ECU_GW
 SG_ BAT690_13_2_CHG_REMTI_GRF11 : 106|8@1+ (45,0) [0|10800] "sec"  C_ECU_GW
 SG_ BAT690_12_2_CHG_REMTI_GRF10 : 98|8@1+ (45,0) [0|10800] "sec"  C_ECU_GW
 SG_ BAT690_11_2_CHG_REMTI_GRF9 : 90|8@1+ (45,0) [0|10800] "sec"  C_ECU_GW
 SG_ BAT690_10_2_CHG_REMTI_GRF8 : 82|8@1+ (45,0) [0|10800] "sec"  C_ECU_GW
 SG_ BAT690_9_2_CHG_REMTI_GRF7 : 74|8@1+ (45,0) [0|10800] "sec"  C_ECU_GW
 SG_ BAT690_8_2_CHG_REMTI_GRF6 : 66|8@1+ (45,0) [0|10800] "sec"  C_ECU_GW
 SG_ BAT690_7_2_CHG_REMTI_GRF5 : 58|8@1+ (45,0) [0|10800] "sec"  C_ECU_GW
 SG_ BAT690_6_2_CHG_REMTI_GRF4 : 50|8@1+ (45,0) [0|10800] "sec"  C_ECU_GW
 SG_ BAT690_5_2_CHG_REMTI_GRF3 : 42|8@1+ (45,0) [0|10800] "sec"  C_ECU_GW
 SG_ BAT690_4_2_CHG_REMTI_GRF2 : 34|8@1+ (45,0) [0|10800] "sec"  C_ECU_GW
 SG_ BAT690_3_2_CHG_REMTI_GRF1 : 26|8@1+ (45,0) [0|10800] "sec"  C_ECU_GW
 SG_ BAT690_3_0_CHG_REMTI_GRF : 24|2@1+ (1,0) [0|3] ""  C_ECU_GW
 SG_ BAT690_2_0_E2E_COUNTER : 16|8@1+ (1,0) [0|255] ""  C_ECU_GW
 SG_ BAT690_0_0_E2E_CRC : 0|16@1+ (1,0) [0|65535] ""  C_ECU_GW

BO_ 134 BAT086: 32 BAT
 SG_ BAT086_2_0_E2E_COUNTER : 16|8@1+ (1,0) [0|255] ""  MET
 SG_ BAT086_0_0_E2E_CRC : 0|16@1+ (1,0) [0|65535] ""  MET

BO_ 862 BAT35E: 32 BAT
 SG_ BAT35E_4_4_HVB_CONDCHK_FLG : 36|2@1+ (1,0) [0|3] ""  MET,C_ECU_GW
 SG_ BAT35E_3_2_HVB_CTRLSOC_PERC : 26|10@1+ (0.1,0) [0|100] "%"  C_ECU,C_ECU_GW
 SG_ BAT35E_3_0_HVB_WRN_TEMP : 24|2@1+ (1,0) [0|3] ""  MET,C_ECU_GW
 SG_ BAT35E_2_0_E2E_COUNTER : 16|8@1+ (1,0) [0|255] ""  C_ECU,C_ECU_GW
 SG_ BAT35E_0_0_E2E_CRC : 0|16@1+ (1,0) [0|65535] ""  C_ECU,C_ECU_GW

BO_ 861 BAT35D: 32 BAT
 SG_ BAT35D_28_5_HVB_ACTCHGWIN : 229|16@1+ (1,0) [0|65533] "kW"  MET,C_ECU_GW
 SG_ BAT35D_27_2_HVB_TEMPAVE : 218|11@1+ (0.5,-50) [-50|150] "℃"  C_ECU_GW
 SG_ BAT35D_25_1_HVB_AVBENE_UPL : 201|17@1+ (1,0) [0|131000] "Wh"  C_ECU_GW
 SG_ BAT35D_23_0_HVB_AVBENE_CUR : 184|17@1+ (1,0) [0|131000] "Wh"  C_ECU_GW
 SG_ BAT35D_20_7_HVB_AVBENE_LOL : 167|17@1+ (1,0) [0|131000] "Wh"  C_ECU_GW
 SG_ BAT35D_18_2_HVB_DISPSOHODO : 146|21@1+ (1,0) [0|1609343] "km"  MET,C_ECU_GW
 SG_ BAT35D_17_0_HVB_DISPSOH_PERC : 136|8@1+ (1,0) [0|100] "%"  MET,C_ECU_GW
 SG_ BAT35D_15_7_HVB_DISPSOH_R_AH : 127|9@1+ (1,0) [0|500] "Ah"  MET,C_ECU_GW
 SG_ BAT35D_14_6_HVB_DISPSOH_AH : 118|9@1+ (1,0) [0|500] "Ah"  MET,C_ECU_GW
 SG_ BAT35D_13_0_CHG_REMTI_UPS_ACN : 104|14@1+ (1,0) [0|15840] "min"  MET,C_ECU_GW
 SG_ BAT35D_11_2_CHG_REMTI_UPS : 90|14@1+ (1,0) [0|15840] "min"  MET,C_ECU_GW
 SG_ BAT35D_9_4_CHG_REMTI_BLK_ACN : 76|14@1+ (1,0) [0|15840] "min"  MET,C_ECU_GW
 SG_ BAT35D_7_6_CHG_REMTI_BLK : 62|14@1+ (1,0) [0|15840] "min"  MET,C_ECU_GW
 SG_ BAT35D_6_0_CHG_REMTI_ACN : 48|14@1+ (1,0) [0|15840] "min"  C_ECU_GW
 SG_ BAT35D_4_2_CHG_REMTI : 34|14@1+ (1,0) [0|15840] "min"  C_ECU_GW
 SG_ BAT35D_3_0_HVB_DISPSOC_PERC : 24|8@1+ (1,0) [0|100] "%"  MET,C_ECU_GW
 SG_ BAT35D_2_0_E2E_COUNTER : 16|8@1+ (1,0) [0|255] ""  C_ECU_GW
 SG_ BAT35D_0_0_E2E_CRC : 0|16@1+ (1,0) [0|65535] ""  C_ECU_GW

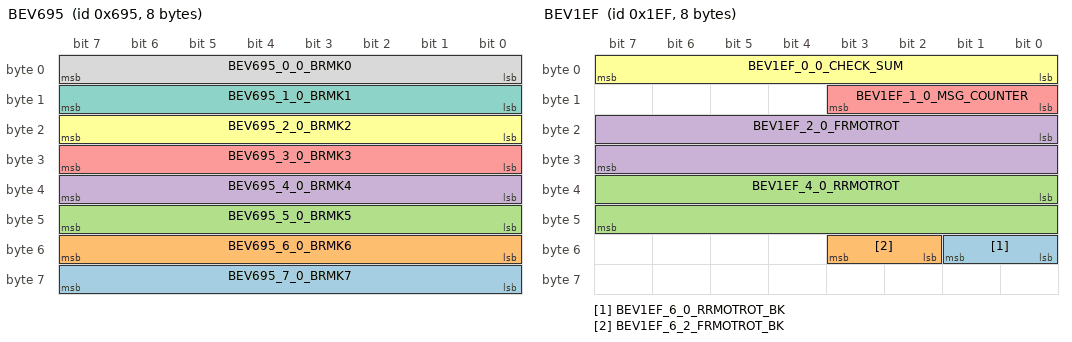
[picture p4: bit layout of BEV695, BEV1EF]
BO_ 1685 BEV695: 8 BEV
 SG_ BEV695_7_0_BRMK7 : 56|8@1+ (1,0) [0|255] "" Vector__XXX
 SG_ BEV695_6_0_BRMK6 : 48|8@1+ (1,0) [0|255] "" Vector__XXX
 SG_ BEV695_5_0_BRMK5 : 40|8@1+ (1,0) [0|255] "" Vector__XXX
 SG_ BEV695_4_0_BRMK4 : 32|8@1+ (1,0) [0|255] "" Vector__XXX
 SG_ BEV695_3_0_BRMK3 : 24|8@1+ (1,0) [0|255] "" Vector__XXX
 SG_ BEV695_2_0_BRMK2 : 16|8@1+ (1,0) [0|255] "" Vector__XXX
 SG_ BEV695_1_0_BRMK1 : 8|8@1+ (1,0) [0|255] "" Vector__XXX
 SG_ BEV695_0_0_BRMK0 : 0|8@1+ (1,0) [0|255] "" Vector__XXX

BO_ 1539 BEV603: 32 BEV
 SG_ BEV603_15_0_BATTEMPSTS_DISP : 120|3@1+ (1,0) [0|5] ""  MET,C_ECU_GW
 SG_ BEV603_14_0_RR_MTRTEMPSTS_DISP : 112|3@1+ (1,0) [0|5] ""  MET,C_ECU_GW
 SG_ BEV603_14_3_FR_MTRTEMPSTS_DISP : 115|3@1+ (1,0) [0|5] ""  MET,C_ECU_GW
 SG_ BEV603_13_0_BATTEMP_DISP : 104|8@1+ (1,-30) [-30|225] "℃"  MET,C_ECU_GW
 SG_ BEV603_12_0_RR_MTRTEMP_DISP : 96|8@1+ (1,-30) [-30|225] "℃"  MET,C_ECU_GW
 SG_ BEV603_11_0_FR_MTRTEMP_DISP : 88|8@1+ (1,-30) [-30|225] "℃"  MET,C_ECU_GW
 SG_ BEV603_10_2_TRQFLCREQ : 82|2@1+ (1,0) [0|3] ""  MET,C_ECU_GW
 SG_ BEV603_10_4_TRQFLCNG : 84|1@1+ (1,0) [0|1] ""  C_ECU_GW
 SG_ BEV603_10_5_TRQFLCSTATE : 85|1@1+ (1,0) [0|1] ""  C_ECU_GW
 SG_ BEV603_10_6_TRQFLCDISP : 86|1@1+ (1,0) [0|1] ""  C_ECU_GW
 SG_ BEV603_10_7_TRQVIBREQ : 87|1@1+ (1,0) [0|1] ""  MET,C_ECU_GW
 SG_ BEV603_9_4_PADL_INHBUZ : 76|1@1+ (1,0) [0|1] ""  C_ECU_GW
 SG_ BEV603_9_5_PADL_LVL : 77|3@1+ (1,0) [0|7] ""  C_ECU_GW
 SG_ BEV603_8_1_XMODE_INH : 65|1@1+ (1,0) [0|1] ""  C_ECU_GW
 SG_ BEV603_8_2_SIDRIVE_INH : 66|1@1+ (1,0) [0|1] ""  C_ECU_GW
 SG_ BEV603_8_3_SIDRIVE_INHBUZ : 67|1@1+ (1,0) [0|1] ""  MET,C_ECU_GW
 SG_ BEV603_8_4_ARBIT_SIDR : 68|1@1+ (1,0) [0|1] ""  MET,C_ECU_GW
 SG_ BEV603_8_5_SIDRIVE_DISP : 69|3@1+ (1,0) [0|7] ""  MET,C_ECU_GW
 SG_ BEV603_7_4_ADPDEC_INHBUZ : 60|1@1+ (1,0) [0|1] ""  MET,C_ECU_GW
 SG_ BEV603_7_5_ADPDEC_INH_ALL : 61|1@1+ (1,0) [0|1] ""  C_ECU_GW
 SG_ BEV603_7_6_ADPDEC_DISP : 62|1@1+ (1,0) [0|1] ""  MET,C_ECU_GW
 SG_ BEV603_7_7_ADPDEC_EQ : 63|1@1+ (1,0) [0|1] ""  C_ECU_GW
 SG_ BEV603_6_0_AWD_MODE : 48|3@1+ (1,0) [0|7] ""  MET,C_ECU_GW
 SG_ BEV603_6_3_AWD_STS_DISP : 51|4@1+ (1,0) [0|7] ""  MET,C_ECU_GW
 SG_ BEV603_6_4_DECSEL_INHMSG : 52|4@1+ (1,0) [0|15] ""  C_ECU_GW
 SG_ BEV603_6_7_AWD_MODE_EQUIP : 55|1@1+ (1,0) [0|1] ""  MET,C_ECU_GW
 SG_ BEV603_5_0_PDLBZR : 40|1@1+ (1,0) [0|1] ""  MET,C_ECU_GW
 SG_ BEV603_5_1_SFTDN_PERM : 41|1@1+ (1,0) [0|1] ""  MET,C_ECU_GW
 SG_ BEV603_5_2_SFTUP_PERM : 42|1@1+ (1,0) [0|1] ""  MET,C_ECU_GW
 SG_ BEV603_5_3_GEARSFT_MODE : 43|2@1+ (1,0) [0|3] ""  MET,C_ECU_GW
 SG_ BEV603_5_4_DECSEL_INH_INDI : 44|1@1+ (1,0) [0|1] ""  C_ECU_GW
 SG_ BEV603_5_5_DECSEL_INH_B : 45|1@1+ (1,0) [0|1] ""  C_ECU_GW
 SG_ BEV603_5_6_DECSEL_INH_D : 46|1@1+ (1,0) [0|1] ""  C_ECU_GW
 SG_ BEV603_5_7_DECSEL_INH_ALL : 47|1@1+ (1,0) [0|1] ""  C_ECU_GW
 SG_ BEV603_4_1_DECSEL_DISP_INDI : 33|1@1+ (1,0) [0|1] ""  C_ECU_GW
 SG_ BEV603_4_2_DECSEL_DISP_B : 34|2@1+ (1,0) [0|3] ""  C_ECU_GW
 SG_ BEV603_4_4_DECLV_DECSEL : 36|4@1+ (1,0) [0|8] ""  MET,C_ECU_GW
 SG_ BEV603_4_6_DECSEL_DISP_ALL : 38|2@1+ (1,0) [0|3] ""  C_ECU_GW
 SG_ BEV603_3_0_GEARLV_MANU : 24|4@1+ (1,0) [0|8] ""  MET,C_ECU_GW
 SG_ BEV603_3_1_DECSEL_EQ_INDI : 25|1@1+ (1,0) [0|1] ""  C_ECU_GW
 SG_ BEV603_3_2_DECSEL_EQ_B : 26|2@1+ (1,0) [0|3] ""  C_ECU_GW
 SG_ BEV603_3_4_GEARLV_AUTO : 28|4@1+ (1,0) [0|8] ""  MET,C_ECU_GW
 SG_ BEV603_3_6_DECSEL_EQ_ALL : 30|2@1+ (1,0) [0|3] ""  C_ECU_GW
 SG_ BEV603_2_0_E2E_COUNTER : 16|8@1+ (1,0) [0|255] ""  MET,C_ECU_GW
 SG_ BEV603_0_0_E2E_CRC : 0|16@1+ (1,0) [0|65535] ""  MET,C_ECU_GW

BO_ 1538 BEV602: 32 BEV
 SG_ BEV602_18_0_V2L_OUTLET_VOLTAGE : 144|8@1+ (0.01,0) [0|250] "V"  C_ECU_GW
 SG_ BEV602_16_0_LV_SYS_STATUS : 128|2@1+ (1,0) [0|3] ""  C_ECU,C_ECU_GW
 SG_ BEV602_15_0_DCM_REMOTE_INFO : 120|4@1+ (1,0) [0|7] ""  C_ECU_GW
 SG_ BEV602_14_7_RR_DISPMSG_RES_UNADJ : 119|1@1+ (1,0) [0|1] ""  MET,C_ECU_GW
 SG_ BEV602_14_6_FR_DISPMSG_RES_UNADJ : 118|1@1+ (1,0) [0|1] ""  MET,C_ECU_GW
 SG_ BEV602_14_4_DISPMSG_SC_SGLPH : 116|2@1+ (1,0) [0|3] ""  MET,C_ECU_GW
 SG_ BEV602_14_2_CERT2_MODE : 114|2@1+ (1,0) [0|2] ""  C_ECU_GW
 SG_ BEV602_14_0_SW_PWR_SPL : 112|2@1+ (1,0) [0|3] ""  C_ECU_GW
 SG_ BEV602_13_0_TCSLMP_REQ : 104|1@1+ (1,0) [0|1] ""  MET,C_ECU_GW
 SG_ BEV602_13_1_AWDLMP_REQ : 105|2@1+ (1,0) [0|3] ""  ADAS,MET,C_ECU_GW
 SG_ BEV602_13_3_AWDWRNMSG_REQ : 107|4@1+ (1,0) [0|2] ""  ADAS,MET,C_ECU_GW
 SG_ BEV602_12_0_BOSLMP_REQ : 96|2@1+ (1,0) [0|3] ""  MET,C_ECU_GW
 SG_ BEV602_11_3_LVB_ABN : 91|3@1+ (1,0) [0|4] ""  C_ECU_GW
 SG_ BEV602_11_6_CERT4_MODE : 94|1@1+ (1,0) [0|1] ""  C_ECU_GW
 SG_ BEV602_11_7_CERT2_MODE : 95|1@1+ (1,0) [0|1] ""  C_ECU_GW
 SG_ BEV602_10_0_FACT_CERT_MODE : 80|1@1+ (1,0) [0|1] ""  C_ECU_GW
 SG_ BEV602_10_1_FACT_MODE : 81|1@1+ (1,0) [0|1] ""  C_ECU_GW
 SG_ BEV602_10_2_EVBATLO_CAU : 82|3@1+ (1,0) [0|7] ""  MET,C_ECU,C_ECU_GW
 SG_ BEV602_10_5_PWRLMT_ID : 85|3@1+ (1,0) [0|3] ""  MET,C_ECU_GW
 SG_ BEV602_9_1_DCRCHK_DSP_REQ : 73|3@1+ (1,0) [0|4] ""  MET,C_ECU_GW
 SG_ BEV602_9_4_LVB_FNCLMT_MSG : 76|3@1+ (1,0) [0|3] ""  MET,C_ECU_GW
 SG_ BEV602_9_7_CHG_MSG : 79|1@1+ (1,0) [0|1] ""  MET,C_ECU_GW
 SG_ BEV602_8_0_LVB_ABN_DCDC : 64|3@1+ (1,0) [0|2] ""  MET,C_ECU_GW
 SG_ BEV602_8_4_LVB_ABN_LIB : 68|3@1+ (1,0) [0|3] ""  MET,C_ECU_GW
 SG_ BEV602_8_7_CHG_CAU : 71|1@1+ (1,0) [0|1] ""  MET,C_ECU_GW
 SG_ BEV602_7_0_V2L_STOP_MSG : 56|8@1+ (1,0) [0|8] ""  C_ECU_GW
 SG_ BEV602_6_0_V2L_SOC_LOWLMT : 48|8@1+ (0.01,0) [0|255] "%"  MET,C_ECU_GW
 SG_ BEV602_5_0_V2L_OUTSTS_2 : 40|1@1+ (1,0) [0|1] ""  C_ECU_GW
 SG_ BEV602_5_1_V2L_OUTSTS_1 : 41|1@1+ (1,0) [0|1] ""  C_ECU_GW
 SG_ BEV602_5_2_ACCHCAU : 42|1@1+ (1,0) [0|1] ""  MET,C_ECU_GW
 SG_ BEV602_5_3_EVIND : 43|5@1+ (1,0) [0|49] ""  MET,C_ECU_GW
 SG_ BEV602_4_0_BEV_OBD_CAU : 32|3@1+ (1,0) [0|7] ""  MET,C_ECU_GW
 SG_ BEV602_4_3_EV_CAU : 35|2@1+ (1,0) [0|3] ""  MET,C_ECU_GW
 SG_ BEV602_4_5_PIROFF_MSG : 37|1@1+ (1,0) [0|1] ""  MET,C_ECU_GW
 SG_ BEV602_3_0_DRVRDY : 24|2@1+ (1,0) [0|3] ""  MET,C_ECU_GW
 SG_ BEV602_3_2_RANGE_POS : 26|3@1+ (1,0) [0|7] ""  C_ECU_GW
 SG_ BEV602_2_0_E2E_COUNTER : 16|8@1+ (1,0) [0|255] ""  ADAS,MET,C_ECU,C_ECU_GW
 SG_ BEV602_0_0_E2E_CRC : 0|16@1+ (1,0) [0|65535] ""  ADAS,MET,C_ECU,C_ECU_GW

BO_ 541 BEV21D: 32 BEV
 SG_ BEV21D_4_0_V2L_PWR_2 : 32|8@1+ (0.1,0) [0|25.5] "kW"  C_ECU_GW
 SG_ BEV21D_3_0_V2L_PWR_1 : 24|8@1+ (0.1,0) [0|25.5] "kW"  C_ECU_GW
 SG_ BEV21D_2_0_E2E_COUNTER : 16|8@1+ (1,0) [0|255] ""  MET,C_ECU_GW
 SG_ BEV21D_0_0_E2E_CRC : 0|16@1+ (1,0) [0|65535] ""  MET,C_ECU_GW

BO_ 269 BEV10D: 32 BEV
 SG_ BEV10D_22_0_SNDGAIN_CHG : 176|4@1+ (1,0) [0|15] ""  C_ECU_GW
 SG_ BEV10D_21_0_EVENT_VOL_B : 168|8@1+ (1,0) [0|255] ""  C_ECU_GW
 SG_ BEV10D_20_0_EVENT_VOL_A : 160|8@1+ (1,0) [0|255] ""  C_ECU_GW
 SG_ BEV10D_18_0_RR_MTRTRQ_SND : 144|16@1- (0.03125,0) [-1024|1023.96875] "Nm"  C_ECU_GW
 SG_ BEV10D_16_0_FR_MTRTRQ_SND : 128|16@1- (0.03125,0) [-1024|1023.96875] "Nm"  C_ECU_GW
 SG_ BEV10D_15_6_ENGON_SND : 126|1@1+ (1,0) [0|1] ""  C_ECU_GW
 SG_ BEV10D_15_7_BKF_SND : 127|1@1+ (1,0) [0|1] ""  C_ECU_GW
 SG_ BEV10D_14_0_V_ENGRPM_SND : 112|14@1+ (1,0) [0|16383] "rpm"  C_ECU_GW
 SG_ BEV10D_12_0_V_RZRPM_DISP : 96|8@1+ (50,5000) [5000|17750] "rpm"  MET,C_ECU_GW
 SG_ BEV10D_11_6_SNDOUT_SET : 94|1@1+ (1,0) [0|1] ""  C_ECU_GW
 SG_ BEV10D_10_0_V_ENGRPM_DISP : 80|14@1+ (1,0) [0|16383] "rpm"  MET,C_ECU_GW
 SG_ BEV10D_9_1_PMINPWRLMTNTC : 73|7@1+ (1,0) [0|100] "%"  MET,C_ECU_GW
 SG_ BEV10D_8_0_PMOUTPWRLMTNTC : 64|9@1+ (1,0) [0|511] "%"  MET,C_ECU_GW
 SG_ BEV10D_7_2_DCLLO_DISP : 58|2@1+ (1,0) [0|3] ""  MET,C_ECU_GW
 SG_ BEV10D_7_4_PMINPWRLMTSTS : 60|1@1+ (1,0) [0|1] ""  MET,C_ECU_GW
 SG_ BEV10D_7_5_PMOUTPWRLMTSTS : 61|1@1+ (1,0) [0|1] ""  MET,C_ECU_GW
 SG_ BEV10D_6_0_PMPWR : 48|10@1- (1,0) [-512|511] "%"  MET,C_ECU_GW
 SG_ BEV10D_5_1_PMINPWRLMT : 41|7@1+ (1,0) [0|100] "%"  MET,C_ECU_GW
 SG_ BEV10D_4_0_PMOUTPWRLMT : 32|9@1+ (1,0) [0|511] "%"  MET,C_ECU_GW
 SG_ BEV10D_3_0_LVB_SOC_LIB : 24|8@1+ (1,0) [0|255] ""  C_ECU_GW
 SG_ BEV10D_2_0_E2E_COUNTER : 16|8@1+ (1,0) [0|255] ""  MET,C_ECU_GW
 SG_ BEV10D_0_0_E2E_CRC : 0|16@1+ (1,0) [0|65535] ""  MET,C_ECU_GW

BO_ 495 BEV1EF: 8 BEV
 SG_ BEV1EF_6_0_RRMOTROT_BK : 48|2@1+ (1,0) [0|3] ""  C_ECU_GW
 SG_ BEV1EF_6_2_FRMOTROT_BK : 50|2@1+ (1,0) [0|3] ""  C_ECU_GW
 SG_ BEV1EF_4_0_RRMOTROT : 32|16@1- (1,0) [-32768|32767] "rpm"  ADAS,C_ECU_GW
 SG_ BEV1EF_2_0_FRMOTROT : 16|16@1- (1,0) [-32768|32767] "rpm"  ADAS,C_ECU_GW
 SG_ BEV1EF_1_0_MSG_COUNTER : 8|4@1+ (1,0) [0|15] ""  ADAS,C_ECU_GW
 SG_ BEV1EF_0_0_CHECK_SUM : 0|8@1+ (1,0) [0|255] ""  ADAS,C_ECU_GW

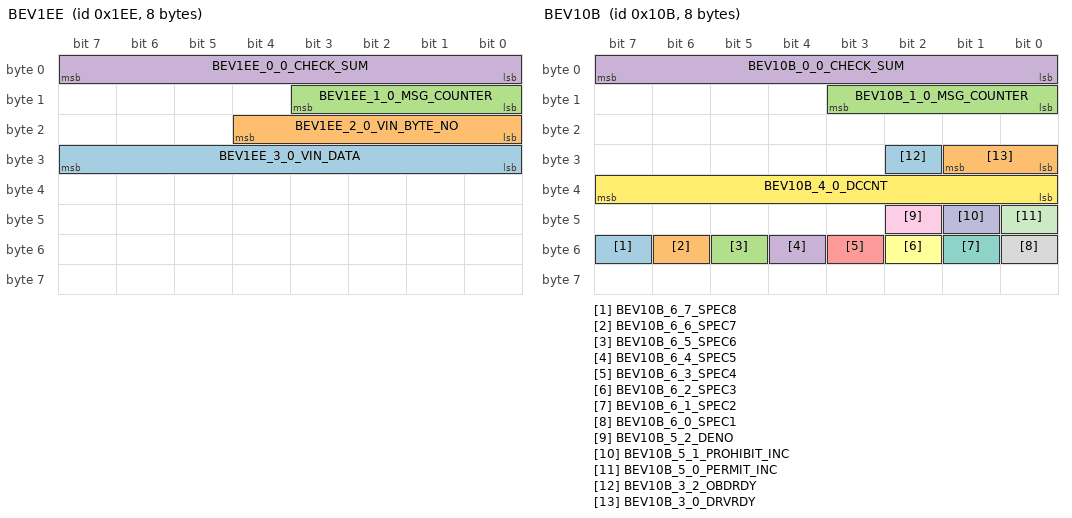
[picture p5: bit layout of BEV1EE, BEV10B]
BO_ 494 BEV1EE: 8 BEV
 SG_ BEV1EE_3_0_VIN_DATA : 24|8@1+ (1,0) [0|255] ""  C_ECU,C_ECU_GW
 SG_ BEV1EE_2_0_VIN_BYTE_NO : 16|5@1+ (1,0) [0|17] ""  C_ECU,C_ECU_GW
 SG_ BEV1EE_1_0_MSG_COUNTER : 8|4@1+ (1,0) [0|15] ""  C_ECU_GW
 SG_ BEV1EE_0_0_CHECK_SUM : 0|8@1+ (1,0) [0|255] ""  C_ECU_GW

BO_ 267 BEV10B: 8 BEV
 SG_ BEV10B_6_7_SPEC8 : 55|1@1+ (1,0) [0|1] ""  C_ECU_GW
 SG_ BEV10B_6_6_SPEC7 : 54|1@1+ (1,0) [0|1] ""  C_ECU_GW
 SG_ BEV10B_6_5_SPEC6 : 53|1@1+ (1,0) [0|1] ""  C_ECU_GW
 SG_ BEV10B_6_4_SPEC5 : 52|1@1+ (1,0) [0|1] ""  C_ECU_GW
 SG_ BEV10B_6_3_SPEC4 : 51|1@1+ (1,0) [0|1] ""  C_ECU_GW
 SG_ BEV10B_6_2_SPEC3 : 50|1@1+ (1,0) [0|1] ""  C_ECU_GW
 SG_ BEV10B_6_1_SPEC2 : 49|1@1+ (1,0) [0|1] ""  C_ECU_GW
 SG_ BEV10B_6_0_SPEC1 : 48|1@1+ (1,0) [0|1] ""  C_ECU_GW
 SG_ BEV10B_5_2_DENO : 42|1@1+ (1,0) [0|1] ""  C_ECU_GW
 SG_ BEV10B_5_1_PROHIBIT_INC : 41|1@1+ (1,0) [0|1] ""  C_ECU_GW
 SG_ BEV10B_5_0_PERMIT_INC : 40|1@1+ (1,0) [0|1] ""  C_ECU_GW
 SG_ BEV10B_4_0_DCCNT : 32|8@1+ (1,0) [0|255] ""  C_ECU_GW
 SG_ BEV10B_3_2_OBDRDY : 26|1@1+ (1,0) [0|1] ""  C_ECU_GW
 SG_ BEV10B_3_0_DRVRDY : 24|2@1+ (1,0) [0|3] ""  C_ECU_GW
 SG_ BEV10B_1_0_MSG_COUNTER : 8|4@1+ (1,0) [0|15] ""  C_ECU_GW
 SG_ BEV10B_0_0_CHECK_SUM : 0|8@1+ (1,0) [0|255] ""  C_ECU_GW

BO_ 117 BEV075: 8 BEV
 SG_ BEV075_1_0_MSG_COUNTER : 8|4@1+ (1,0) [0|15] ""  C_ECU_GW
 SG_ BEV075_0_0_CHECK_SUM : 0|8@1+ (1,0) [0|255] ""  C_ECU_GW

BO_ 116 BEV074: 8 BEV
 SG_ BEV074_7_0_LVPWRDWN : 56|6@1+ (1,0) [0|3] ""  C_ECU_GW
 SG_ BEV074_7_6_CHRCONSTA : 62|1@1+ (1,0) [0|1] ""  ADAS,C_ECU_GW
 SG_ BEV074_7_7_VEHICLE_IGN : 63|1@1+ (1,0) [0|1] ""  C_ECU_GW
 SG_ BEV074_6_0_EV_CAU : 48|2@1+ (1,0) [0|3] ""  C_ECU_GW
 SG_ BEV074_6_2_BEV_OBD_CAU : 50|3@1+ (1,0) [0|7] ""  C_ECU_GW
 SG_ BEV074_6_5_SIDRIVE_DISP : 53|3@1+ (1,0) [0|7] ""  C_ECU_GW
 SG_ BEV074_5_0_ACCHG_STATE : 40|1@1+ (1,0) [0|1] ""  C_ECU,C_ECU_GW
 SG_ BEV074_5_1_DCCHG_STATE : 41|1@1+ (1,0) [0|1] ""  C_ECU,C_ECU_GW
 SG_ BEV074_5_2_RANGE_DG : 42|1@1+ (1,0) [0|1] ""  MVS,RCR_R,RCR_L,SNR,ADAS,C_ECU_GW
 SG_ BEV074_5_3_ACCP_DG : 43|1@1+ (1,0) [0|1] ""  ADAS,C_ECU_GW
 SG_ BEV074_5_4_REZ_SPD_BK : 44|2@1+ (1,0) [0|3] ""  C_ECU_GW
 SG_ BEV074_5_6_OBDRDY : 46|1@1+ (1,0) [0|1] ""  C_ECU_GW
 SG_ BEV074_5_7_FHVB : 47|1@1+ (1,0) [0|1] ""  C_ECU,C_ECU_GW
 SG_ BEV074_3_0_RANGE_POS : 24|3@1+ (1,0) [0|7] ""  MVS,RCR_R,RCR_L,SNR,ADAS,MET,C_ECU,C_ECU_GW
 SG_ BEV074_3_3_DRVRDY : 27|2@1+ (1,0) [0|3] ""  ADAS,C_ECU,C_ECU_GW
 SG_ BEV074_3_5_HVSYSTS : 29|2@1+ (1,0) [0|3] ""  C_ECU,C_ECU_GW
 SG_ BEV074_3_7_REZ_SPD_GL : 31|9@1- (1,0) [-256|255] "km/h"  C_ECU_GW
 SG_ BEV074_2_0_ACCP_USR : 16|8@1+ (0.5,0) [0|127.5] "%"  SNR,C_ECU,C_ECU_GW
 SG_ BEV074_1_0_MSG_COUNTER : 8|4@1+ (1,0) [0|15] ""  MVS,RCR_R,RCR_L,SNR,ADAS,C_ECU,C_ECU_GW
 SG_ BEV074_1_4_RANGE_DG2 : 12|1@1+ (1,0) [0|1] ""  MVS,RCR_R,RCR_L,SNR,C_ECU_GW
 SG_ BEV074_1_5_REZ_SPD_BK : 13|3@1+ (1,0) [0|5] ""  C_ECU_GW
 SG_ BEV074_0_0_CHECK_SUM : 0|8@1+ (1,0) [0|255] ""  MVS,RCR_R,RCR_L,SNR,ADAS,C_ECU,C_ECU_GW

BO_TX_BU_ 1549 : ADAS_GW,ENM;
CM_ SG_ 824 ADAS338_22_0_OBJECT16_WINKER "移動物16_ウインカ状態
";
CM_ SG_ 824 ADAS338_22_2_OBJECT16_BRAKE "移動物16_ブレーキランプ
";
CM_ SG_ 824 ADAS338_22_3_OBJECT16_BLINK "移動物16_点灯滅
";
CM_ SG_ 824 ADAS338_22_5_OBJECT16_Z "移動物16_z座標
";
CM_ SG_ 824 ADAS338_20_0_OBJECT16_X "移動物16_x座標
";
CM_ SG_ 824 ADAS338_19_1_OBJECT16_ANGLE "移動物16_角度
";
CM_ SG_ 824 ADAS338_18_0_OBJECT16_COLOR "移動物16_色
";
CM_ SG_ 824 ADAS338_18_4_OBJECT16_SHAPE "移動物16_形状
";
CM_ SG_ 824 ADAS338_17_0_OBJECT15_WINKER "移動物15_ウインカ状態
";
CM_ SG_ 824 ADAS338_17_2_OBJECT15_BRAKE "移動物15_ブレーキランプ
";
CM_ SG_ 824 ADAS338_17_3_OBJECT15_BLINK "移動物15_点灯滅
";
CM_ SG_ 824 ADAS338_17_5_OBJECT15_Z "移動物15_z座標
";
CM_ SG_ 824 ADAS338_15_0_OBJECT15_X "移動物15_x座標
";
CM_ SG_ 824 ADAS338_14_1_OBJECT15_ANGLE "移動物15_角度
";
CM_ SG_ 824 ADAS338_13_0_OBJECT15_COLOR "移動物15_色
";
CM_ SG_ 824 ADAS338_13_4_OBJECT15_SHAPE "移動物15_形状
";
CM_ SG_ 824 ADAS338_12_0_OBJECT14_WINKER "移動物14_ウインカ状態
";
CM_ SG_ 824 ADAS338_12_2_OBJECT14_BRAKE "移動物14_ブレーキランプ
";
CM_ SG_ 824 ADAS338_12_3_OBJECT14_BLINK "移動物14_点灯滅
";
CM_ SG_ 824 ADAS338_12_5_OBJECT14_Z "移動物14_z座標
";
CM_ SG_ 824 ADAS338_10_0_OBJECT14_X "移動物14_x座標
";
CM_ SG_ 824 ADAS338_9_1_OBJECT14_ANGLE "移動物14_角度
";
CM_ SG_ 824 ADAS338_8_0_OBJECT14_COLOR "移動物14_色
";
CM_ SG_ 824 ADAS338_8_4_OBJECT14_SHAPE "移動物14_形状
";
CM_ SG_ 824 ADAS338_7_0_OBJECT13_WINKER "移動物13_ウインカ状態
";
CM_ SG_ 824 ADAS338_7_2_OBJECT13_BRAKE "移動物13_ブレーキランプ
";
CM_ SG_ 824 ADAS338_7_3_OBJECT13_BLINK "移動物13_点灯滅
";
CM_ SG_ 824 ADAS338_7_5_OBJECT13_Z "移動物13_z座標
";
CM_ SG_ 824 ADAS338_5_0_OBJECT13_X "移動物13_x座標
";
CM_ SG_ 824 ADAS338_4_1_OBJECT13_ANGLE "移動物13_角度
";
CM_ SG_ 824 ADAS338_3_0_OBJECT13_COLOR "移動物13_色
";
CM_ SG_ 824 ADAS338_3_4_OBJECT13_SHAPE "移動物13_形状
";
CM_ SG_ 824 ADAS338_2_0_E2E_COUNTER "E2Eカウンタ
";
CM_ SG_ 824 ADAS338_0_0_E2E_CRC "CRC
";
CM_ SG_ 823 ADAS337_22_0_OBJECT12_WINKER "移動物12_ウインカ状態
";
CM_ SG_ 823 ADAS337_22_2_OBJECT12_BRAKE "移動物12_ブレーキランプ
";
CM_ SG_ 823 ADAS337_22_3_OBJECT12_BLINK "移動物12_点灯滅
";
CM_ SG_ 823 ADAS337_22_5_OBJECT12_Z "移動物12_z座標
";
CM_ SG_ 823 ADAS337_20_0_OBJECT12_X "移動物12_x座標
";
CM_ SG_ 823 ADAS337_19_1_OBJECT12_ANGLE "移動物12_角度
";
CM_ SG_ 823 ADAS337_18_0_OBJECT12_COLOR "移動物12_色
";
CM_ SG_ 823 ADAS337_18_4_OBJECT12_SHAPE "移動物12_形状
";
CM_ SG_ 823 ADAS337_17_0_OBJECT11_WINKER "移動物11_ウインカ状態
";
CM_ SG_ 823 ADAS337_17_2_OBJECT11_BRAKE "移動物11_ブレーキランプ
";
CM_ SG_ 823 ADAS337_17_3_OBJECT11_BLINK "移動物11_点灯滅
";
CM_ SG_ 823 ADAS337_17_5_OBJECT11_Z "移動物11_z座標
";
CM_ SG_ 823 ADAS337_15_0_OBJECT11_X "移動物11_x座標
";
CM_ SG_ 823 ADAS337_14_1_OBJECT11_ANGLE "移動物11_角度
";
CM_ SG_ 823 ADAS337_13_0_OBJECT11_COLOR "移動物11_色
";
CM_ SG_ 823 ADAS337_13_4_OBJECT11_SHAPE "移動物11_形状
";
CM_ SG_ 823 ADAS337_12_0_OBJECT10_WINKER "移動物10_ウインカ状態
";
CM_ SG_ 823 ADAS337_12_2_OBJECT10_BRAKE "移動物10_ブレーキランプ
";
CM_ SG_ 823 ADAS337_12_3_OBJECT10_BLINK "移動物10_点灯滅
";
CM_ SG_ 823 ADAS337_12_5_OBJECT10_Z "移動物10_z座標
";
CM_ SG_ 823 ADAS337_10_0_OBJECT10_X "移動物10_x座標
";
CM_ SG_ 823 ADAS337_9_1_OBJECT10_ANGLE "移動物10_角度
";
CM_ SG_ 823 ADAS337_8_0_OBJECT10_COLOR "移動物10_色
";
CM_ SG_ 823 ADAS337_8_4_OBJECT10_SHAPE "移動物10_形状
";
CM_ SG_ 823 ADAS337_7_0_OBJECT9_WINKER "移動物9_ウインカ状態
";
CM_ SG_ 823 ADAS337_7_2_OBJECT9_BRAKE "移動物9_ブレーキランプ
";
CM_ SG_ 823 ADAS337_7_3_OBJECT9_BLINK "移動物9_点灯滅
";
CM_ SG_ 823 ADAS337_7_5_OBJECT9_Z "移動物9_z座標
";
CM_ SG_ 823 ADAS337_5_0_OBJECT9_X "移動物9_x座標
";
CM_ SG_ 823 ADAS337_4_1_OBJECT9_ANGLE "移動物9_角度
";
CM_ SG_ 823 ADAS337_3_0_OBJECT9_COLOR "移動物9_色
";
CM_ SG_ 823 ADAS337_3_4_OBJECT9_SHAPE "移動物9_形状
";
CM_ SG_ 823 ADAS337_2_0_E2E_COUNTER "E2Eカウンタ
";
CM_ SG_ 823 ADAS337_0_0_E2E_CRC "CRC
";
CM_ SG_ 822 ADAS336_22_0_OBJECT8_WINKER "移動物8_ウインカ状態
";
CM_ SG_ 822 ADAS336_22_2_OBJECT8_BRAKE "移動物8_ブレーキランプ
";
CM_ SG_ 822 ADAS336_22_3_OBJECT8_BLINK "移動物8_点灯滅
";
CM_ SG_ 822 ADAS336_22_5_OBJECT8_Z "移動物8_z座標
";
CM_ SG_ 822 ADAS336_20_0_OBJECT8_X "移動物8_x座標
";
CM_ SG_ 822 ADAS336_19_1_OBJECT8_ANGLE "移動物8_角度
";
CM_ SG_ 822 ADAS336_18_0_OBJECT8_COLOR "移動物8_色
";
CM_ SG_ 822 ADAS336_18_4_OBJECT8_SHAPE "移動物8_形状
";
CM_ SG_ 822 ADAS336_17_0_OBJECT7_WINKER "移動物7_ウインカ状態
";
CM_ SG_ 822 ADAS336_17_2_OBJECT7_BRAKE "移動物7_ブレーキランプ
";
CM_ SG_ 822 ADAS336_17_3_OBJECT7_BLINK "移動物7_点灯滅
";
CM_ SG_ 822 ADAS336_17_5_OBJECT7_Z "移動物7_z座標
";
CM_ SG_ 822 ADAS336_15_0_OBJECT7_X "移動物7_x座標
";
CM_ SG_ 822 ADAS336_14_1_OBJECT7_ANGLE "移動物7_角度
";
CM_ SG_ 822 ADAS336_13_0_OBJECT7_COLOR "移動物7_色
";
CM_ SG_ 822 ADAS336_13_4_OBJECT7_SHAPE "移動物7_形状
";
CM_ SG_ 822 ADAS336_12_0_OBJECT6_WINKER "移動物6_ウインカ状態
";
CM_ SG_ 822 ADAS336_12_2_OBJECT6_BRAKE "移動物6_ブレーキランプ
";
CM_ SG_ 822 ADAS336_12_3_OBJECT6_BLINK "移動物6_点灯滅
";
CM_ SG_ 822 ADAS336_12_5_OBJECT6_Z "移動物6_z座標
";
CM_ SG_ 822 ADAS336_10_0_OBJECT6_X "移動物6_x座標
";
CM_ SG_ 822 ADAS336_9_1_OBJECT6_ANGLE "移動物6_角度
";
CM_ SG_ 822 ADAS336_8_0_OBJECT6_COLOR "移動物6_色
";
CM_ SG_ 822 ADAS336_8_4_OBJECT6_SHAPE "移動物6_形状
";
CM_ SG_ 822 ADAS336_7_0_OBJECT5_WINKER "移動物5_ウインカ状態
";
CM_ SG_ 822 ADAS336_7_2_OBJECT5_BRAKE "移動物5_ブレーキランプ
";
CM_ SG_ 822 ADAS336_7_3_OBJECT5_BLINK "移動物5_点灯滅
";
CM_ SG_ 822 ADAS336_7_5_OBJECT5_Z "移動物5_z座標
";
CM_ SG_ 822 ADAS336_5_0_OBJECT5_X "移動物5_x座標
";
CM_ SG_ 822 ADAS336_4_1_OBJECT5_ANGLE "移動物5_角度
";
CM_ SG_ 822 ADAS336_3_0_OBJECT5_COLOR "移動物5_色
";
CM_ SG_ 822 ADAS336_3_4_OBJECT5_SHAPE "移動物5_形状
";
CM_ SG_ 822 ADAS336_2_0_E2E_COUNTER "E2Eカウンタ
";
CM_ SG_ 822 ADAS336_0_0_E2E_CRC "CRC
";
CM_ SG_ 821 ADAS335_22_0_OBJECT4_WINKER "移動物4_ウインカ状態
";
CM_ SG_ 821 ADAS335_22_2_OBJECT4_BRAKE "移動物4_ブレーキランプ
";
CM_ SG_ 821 ADAS335_22_3_OBJECT4_BLINK "移動物4_点灯滅
";
CM_ SG_ 821 ADAS335_22_5_OBJECT4_Z "移動物4_z座標
";
CM_ SG_ 821 ADAS335_20_0_OBJECT4_X "移動物4_x座標
";
CM_ SG_ 821 ADAS335_19_1_OBJECT4_ANGLE "移動物4_角度
";
CM_ SG_ 821 ADAS335_18_0_OBJECT4_COLOR "移動物4_色
";
CM_ SG_ 821 ADAS335_18_4_OBJECT4_SHAPE "移動物4_形状
";
CM_ SG_ 821 ADAS335_17_0_OBJECT3_WINKER "移動物3_ウインカ状態
";
CM_ SG_ 821 ADAS335_17_2_OBJECT3_BRAKE "移動物3_ブレーキランプ
";
CM_ SG_ 821 ADAS335_17_3_OBJECT3_BLINK "移動物3_点灯滅
";
CM_ SG_ 821 ADAS335_17_5_OBJECT3_Z "移動物3_z座標
";
CM_ SG_ 821 ADAS335_15_0_OBJECT3_X "移動物3_x座標
";
CM_ SG_ 821 ADAS335_14_1_OBJECT3_ANGLE "移動物3_角度
";
CM_ SG_ 821 ADAS335_13_0_OBJECT3_COLOR "移動物3_色
";
CM_ SG_ 821 ADAS335_13_4_OBJECT3_SHAPE "移動物3_形状
";
CM_ SG_ 821 ADAS335_12_0_OBJECT2_WINKER "移動物2_ウインカ状態
";
CM_ SG_ 821 ADAS335_12_2_OBJECT2_BRAKE "移動物2_ブレーキランプ
";
CM_ SG_ 821 ADAS335_12_3_OBJECT2_BLINK "移動物2_点灯滅
";
CM_ SG_ 821 ADAS335_12_5_OBJECT2_Z "移動物2_z座標
";
CM_ SG_ 821 ADAS335_10_0_OBJECT2_X "移動物2_x座標
";
CM_ SG_ 821 ADAS335_9_1_OBJECT2_ANGLE "移動物2_角度
";
CM_ SG_ 821 ADAS335_8_0_OBJECT2_COLOR "移動物2_色
";
CM_ SG_ 821 ADAS335_8_4_OBJECT2_SHAPE "移動物2_形状
";
CM_ SG_ 821 ADAS335_7_0_OBJECT1_WINKER "移動物1_ウインカ状態
";
CM_ SG_ 821 ADAS335_7_2_OBJECT1_BRAKE "移動物1_ブレーキランプ
";
CM_ SG_ 821 ADAS335_7_3_OBJECT1_BLINK "移動物1_点灯滅
";
CM_ SG_ 821 ADAS335_7_5_OBJECT1_Z "移動物1_z座標
";
CM_ SG_ 821 ADAS335_5_0_OBJECT1_X "移動物1_x座標
";
CM_ SG_ 821 ADAS335_4_1_OBJECT1_ANGLE "移動物1_角度
";
CM_ SG_ 821 ADAS335_3_0_OBJECT1_COLOR "移動物1_色
";
CM_ SG_ 821 ADAS335_3_4_OBJECT1_SHAPE "移動物1_形状
";
CM_ SG_ 821 ADAS335_2_0_E2E_COUNTER "E2Eカウンタ
";
CM_ SG_ 821 ADAS335_0_0_E2E_CRC "CRC
";
CM_ SG_ 813 ADAS32D_2_0_E2E_COUNTER "E2Eカウンタ
";
CM_ SG_ 813 ADAS32D_0_0_E2E_CRC "CRC
";
CM_ SG_ 812 ADAS32C_2_0_E2E_COUNTER "E2Eカウンタ
";
CM_ SG_ 812 ADAS32C_0_0_E2E_CRC "CRC
";
CM_ SG_ 797 ADAS31D_7_0_LANE_DEP_EFFE_LANE "車線逸脱エフェクト_区画線
";
CM_ SG_ 797 ADAS31D_7_3_LANE_DEP_EFFE_BLINK "車線逸脱エフェクト_点灯滅
";
CM_ SG_ 797 ADAS31D_7_4_LANE_DEP_EFFE_COLOR "車線逸脱エフェクト_色
";
CM_ SG_ 797 ADAS31D_7_6_LANE_DEP_EFFE_LR "車線逸脱エフェクト_左右
";
CM_ SG_ 797 ADAS31D_6_0_ALC_ICON_LEFT_COLOR "ALCアイコン_左色
";
CM_ SG_ 797 ADAS31D_6_2_ALC_ICON_RIGHT_COLOR "ALCアイコン_右色
";
CM_ SG_ 797 ADAS31D_6_4_ALC_ICON_LEFT "ALCアイコン_左
";
CM_ SG_ 797 ADAS31D_6_6_ALC_ICON_RIGHT "ALCアイコン_右
";
CM_ SG_ 797 ADAS31D_5_2_LANE_CHANGE_LANE3 "レーンチェンジ_区画線3
";
CM_ SG_ 797 ADAS31D_5_5_LANE_CHANGE_LANE2 "レーンチェンジ_区画線2
";
CM_ SG_ 797 ADAS31D_4_0_LANE_CHANGE_LANE1 "レーンチェンジ_区画線1
";
CM_ SG_ 797 ADAS31D_4_3_LANE_CHANGE_COLOR "レーンチェンジ_色
";
CM_ SG_ 797 ADAS31D_4_4_LANE_CHANGE_LR "レーンチェンジ_左右
";
CM_ SG_ 797 ADAS31D_4_6_VEHICLE_OFFSET_COLOR "車両避け_色
";
CM_ SG_ 797 ADAS31D_3_0_VEHICLE_OFFSET_WIDTH "車両避け_幅
";
CM_ SG_ 797 ADAS31D_3_3_VEHICLE_OFFSET_LANE "車両避け_区画線
";
CM_ SG_ 797 ADAS31D_3_6_VEHICLE_OFFSET_LR "車両避け_左右
";
CM_ SG_ 797 ADAS31D_2_0_E2E_COUNTER "E2Eカウンタ
";
CM_ SG_ 797 ADAS31D_0_0_E2E_CRC "CRC
";
CM_ SG_ 796 ADAS31C_25_0_LANE6_END_X "区画線6_終点_x座標
";
CM_ SG_ 796 ADAS31C_24_1_LANE6_END_Z "区画線6_終点_z座標
";
CM_ SG_ 796 ADAS31C_23_0_LANE6_MID3_X "区画線6_中点3_x座標
";
CM_ SG_ 796 ADAS31C_22_1_LANE6_MID3_Z "区画線6_中点3_z座標
";
CM_ SG_ 796 ADAS31C_21_0_LANE6_MID2_X "区画線6_中点2_x座標
";
CM_ SG_ 796 ADAS31C_20_1_LANE6_MID2_Z "区画線6_中点2_z座標
";
CM_ SG_ 796 ADAS31C_19_0_LANE6_MID1_X "区画線6_中点2_x座標
";
CM_ SG_ 796 ADAS31C_18_1_LANE6_MID1_Z "区画線6_中点2_z座標
";
CM_ SG_ 796 ADAS31C_17_0_LANE6_START_X "区画線6_始点_x座標
";
CM_ SG_ 796 ADAS31C_16_1_LANE6_START_Z "区画線6_始点_z座標
";
CM_ SG_ 796 ADAS31C_15_0_LANE6_BLINK "区画線6_点灯滅
";
CM_ SG_ 796 ADAS31C_15_1_LANE6_DISP "区画線6_表示指示
";
CM_ SG_ 796 ADAS31C_15_3_LANE6_COLOR "区画線6_色
";
CM_ SG_ 796 ADAS31C_15_5_LANE6_TYPE "区画線6_種別
";
CM_ SG_ 796 ADAS31C_14_0_LANE6_NO "区画線6_No
";
CM_ SG_ 796 ADAS31C_14_5_LANE5_NO "区画線5_No
";
CM_ SG_ 796 ADAS31C_13_0_LANE5_END_X "区画線5_終点_x座標
";
CM_ SG_ 796 ADAS31C_12_1_LANE5_END_Z "区画線5_終点_z座標
";
CM_ SG_ 796 ADAS31C_11_0_LANE5_MID3_X "区画線5_中点3_x座標
";
CM_ SG_ 796 ADAS31C_10_1_LANE5_MID3_Z "区画線5_中点3_z座標
";
CM_ SG_ 796 ADAS31C_9_0_LANE5_MID2_X "区画線5_中点2_x座標
";
CM_ SG_ 796 ADAS31C_8_1_LANE5_MID2_Z "区画線5_中点2_z座標
";
CM_ SG_ 796 ADAS31C_7_0_LANE5_MID1_X "区画線5_中点1_x座標
";
CM_ SG_ 796 ADAS31C_6_1_LANE5_MID1_Z "区画線5_中点1_z座標
";
CM_ SG_ 796 ADAS31C_5_0_LANE5_START_X "区画線5_始点_x座標
";
CM_ SG_ 796 ADAS31C_4_1_LANE5_START_Z "区画線5_始点_z座標
";
CM_ SG_ 796 ADAS31C_3_0_LANE5_BLINK "区画線5_点灯滅
";
CM_ SG_ 796 ADAS31C_3_1_LANE5_DISP "区画線5_表示指示
";
CM_ SG_ 796 ADAS31C_3_2_LANE5_COLOR "区画線5_色
";
CM_ SG_ 796 ADAS31C_3_5_LANE5_TYPE "区画線5_種別
";
CM_ SG_ 796 ADAS31C_2_0_E2E_COUNTER "E2Eカウンタ
";
CM_ SG_ 796 ADAS31C_0_0_E2E_CRC "CRC
";
CM_ SG_ 795 ADAS31B_31_0_LANE_DRAW_DISTANCE "車線描画距離
";
CM_ SG_ 795 ADAS31B_30_1_INTERSECTION_MODE "交差点モード
";
CM_ SG_ 795 ADAS31B_29_0_ROAD2_END "路面2_終点
";
CM_ SG_ 795 ADAS31B_28_0_ROAD2_START "路面2_始点
";
CM_ SG_ 795 ADAS31B_27_1_ROAD2_LANE2 "路面2_区画線2
";
CM_ SG_ 795 ADAS31B_27_4_ROAD2_LANE1 "路面2_区画線1
";
CM_ SG_ 795 ADAS31B_27_7_ROAD2_BLINK "路面2_点灯滅
";
CM_ SG_ 795 ADAS31B_26_0_ROAD2_END_DRAW "路面2_終点描画
";
CM_ SG_ 795 ADAS31B_26_1_ROAD2_START_DRAW "路面2_始点描画
";
CM_ SG_ 795 ADAS31B_26_1_ROAD2_ANIMATION "路面2_アニメーション
";
CM_ SG_ 795 ADAS31B_26_5_ROAD2_COLOR "路面2_色
";
CM_ SG_ 795 ADAS31B_25_0_LANE4_END_X "区画線4_終点_x座標
";
CM_ SG_ 795 ADAS31B_24_1_LANE4_END_Z "区画線4_終点_z座標
";
CM_ SG_ 795 ADAS31B_23_0_LANE4_MID3_X "区画線4_中点3_x座標
";
CM_ SG_ 795 ADAS31B_22_1_LANE4_MID3_Z "区画線4_中点3_z座標
";
CM_ SG_ 795 ADAS31B_21_0_LANE4_MID2_X "区画線4_中点2_x座標
";
CM_ SG_ 795 ADAS31B_20_1_LANE4_MID2_Z "区画線4_中点2_z座標
";
CM_ SG_ 795 ADAS31B_19_0_LANE4_MID1_X "区画線4_中点2_x座標
";
CM_ SG_ 795 ADAS31B_18_1_LANE4_MID1_Z "区画線4_中点2_z座標
";
CM_ SG_ 795 ADAS31B_17_0_LANE4_START_X "区画線4_始点_x座標
";
CM_ SG_ 795 ADAS31B_16_1_LANE4_START_Z "区画線4_始点_z座標
";
CM_ SG_ 795 ADAS31B_15_0_LANE4_BLINK "区画線4_点灯滅
";
CM_ SG_ 795 ADAS31B_15_1_LANE4_DISP "区画線4_表示指示
";
CM_ SG_ 795 ADAS31B_15_3_LANE4_COLOR "区画線4_色
";
CM_ SG_ 795 ADAS31B_15_5_LANE4_TYPE "区画線4_種別
";
CM_ SG_ 795 ADAS31B_14_0_LANE4_NO "区画線4_No
";
CM_ SG_ 795 ADAS31B_14_5_LANE3_NO "区画線3_No
";
CM_ SG_ 795 ADAS31B_13_0_LANE3_END_X "区画線3_終点_x座標
";
CM_ SG_ 795 ADAS31B_12_1_LANE3_END_Z "区画線3_終点_z座標
";
CM_ SG_ 795 ADAS31B_11_0_LANE3_MID3_X "区画線3_中点3_x座標
";
CM_ SG_ 795 ADAS31B_10_1_LANE3_MID3_Z "区画線3_中点3_z座標
";
CM_ SG_ 795 ADAS31B_9_0_LANE3_MID2_X "区画線3_中点2_x座標
";
CM_ SG_ 795 ADAS31B_8_1_LANE3_MID2_Z "区画線3_中点2_z座標
";
CM_ SG_ 795 ADAS31B_7_0_LANE3_MID1_X "区画線3_中点1_x座標
";
CM_ SG_ 795 ADAS31B_6_1_LANE3_MID1_Z "区画線3_中点1_z座標
";
CM_ SG_ 795 ADAS31B_5_0_LANE3_START_X "区画線3_始点_x座標
";
CM_ SG_ 795 ADAS31B_4_1_LANE3_START_Z "区画線3_始点_z座標
";
CM_ SG_ 795 ADAS31B_3_0_LANE3_BLINK "区画線3_点灯滅
";
CM_ SG_ 795 ADAS31B_3_1_LANE3_DISP "区画線3_表示指示
";
CM_ SG_ 795 ADAS31B_3_2_LANE3_COLOR "区画線3_色
";
CM_ SG_ 795 ADAS31B_3_5_LANE3_TYPE "区画線3_種別
";
CM_ SG_ 794 ADAS31A_30_1_LANE_DEP_LANE_COLOR "車線逸脱_区画線_色
";
CM_ SG_ 794 ADAS31A_30_4_LANE_DEP_LANE_TYPE "車線逸脱_区画線_形状
";
CM_ SG_ 794 ADAS31A_30_6_LANE_DEP_LANE_LEFT "車線逸脱_区画線_左
";
CM_ SG_ 794 ADAS31A_30_7_LANE_DEP_LANE_RIGHT "車線逸脱_区画線_右
";
CM_ SG_ 794 ADAS31A_29_0_ROAD1_END "路面1_終点
";
CM_ SG_ 794 ADAS31A_28_0_ROAD1_START "路面1_始点
";
CM_ SG_ 794 ADAS31A_27_1_ROAD1_LANE2 "路面1_区画線2
";
CM_ SG_ 794 ADAS31A_27_4_ROAD1_LANE1 "路面1_区画線1
";
CM_ SG_ 794 ADAS31A_27_7_ROAD1_BLINK "路面1_点灯滅
";
CM_ SG_ 794 ADAS31A_26_0_ROAD1_END_DRAW "路面1_終点描画
";
CM_ SG_ 794 ADAS31A_26_1_ROAD1_START_DRAW "路面1_始点描画
";
CM_ SG_ 794 ADAS31A_26_2_ROAD1_ANIMATION "路面1_アニメーション
";
CM_ SG_ 794 ADAS31A_26_5_ROAD1_COLOR "路面1_色
";
CM_ SG_ 794 ADAS31A_25_0_LANE2_END_X "区画線2_終点_x座標
";
CM_ SG_ 794 ADAS31A_24_1_LANE2_END_Z "区画線2_終点_z座標
";
CM_ SG_ 794 ADAS31A_23_0_LANE2_MID3_X "区画線2_中点3_x座標
";
CM_ SG_ 794 ADAS31A_22_1_LANE2_MID3_Z "区画線2_中点3_z座標
";
CM_ SG_ 794 ADAS31A_21_0_LANE2_MID2_X "区画線2_中点2_x座標
";
CM_ SG_ 794 ADAS31A_20_1_LANE2_MID2_Z "区画線2_中点2_z座標
";
CM_ SG_ 794 ADAS31A_19_0_LANE2_MID1_X "区画線2_中点2_x座標
";
CM_ SG_ 794 ADAS31A_18_1_LANE2_MID1_Z "区画線2_中点2_z座標
";
CM_ SG_ 794 ADAS31A_17_0_LANE2_START_X "区画線2_始点_x座標
";
CM_ SG_ 794 ADAS31A_16_1_LANE2_START_Z "区画線2_始点_z座標
";
CM_ SG_ 794 ADAS31A_15_0_LANE2_BLINK "区画線2_点灯滅
";
CM_ SG_ 794 ADAS31A_15_1_LANE2_DISP "区画線2_表示指示
";
CM_ SG_ 794 ADAS31A_15_3_LANE2_COLOR "区画線2_色
";
CM_ SG_ 794 ADAS31A_15_5_LANE2_TYPE "区画線2_種別
";
CM_ SG_ 794 ADAS31A_14_0_LANE2_NO "区画線2_No
";
CM_ SG_ 794 ADAS31A_14_5_LANE1_NO "区画線1_No
";
CM_ SG_ 794 ADAS31A_13_0_LANE1_END_X "区画線1_終点_x座標
";
CM_ SG_ 794 ADAS31A_12_1_LANE1_END_Z "区画線1_終点_z座標
";
CM_ SG_ 794 ADAS31A_11_0_LANE1_MID3_X "区画線1_中点3_x座標
";
CM_ SG_ 794 ADAS31A_10_1_LANE1_MID3_Z "区画線1_中点3_z座標
";
CM_ SG_ 794 ADAS31A_9_0_LANE1_MID2_X "区画線1_中点2_x座標
";
CM_ SG_ 794 ADAS31A_8_1_LANE1_MID2_Z "区画線1_中点2_z座標
";
CM_ SG_ 794 ADAS31A_7_0_LANE1_MID1_X "区画線1_中点1_x座標
";
CM_ SG_ 794 ADAS31A_6_1_LANE1_MID1_Z "区画線1_中点1_z座標
";
CM_ SG_ 794 ADAS31A_5_0_LANE1_START_X "区画線1_始点_x座標
";
CM_ SG_ 794 ADAS31A_4_1_LANE1_START_Z "区画線1_始点_z座標
";
CM_ SG_ 794 ADAS31A_3_0_LANE1_BLINK "区画線1_点灯滅
";
CM_ SG_ 794 ADAS31A_3_1_LANE1_DISP "区画線1_表示指示
";
CM_ SG_ 794 ADAS31A_3_2_LANE1_COLOR "区画線1_色
";
CM_ SG_ 794 ADAS31A_3_5_LANE1_TYPE "区画線1_種別
";
CM_ SG_ 794 ADAS31A_2_0_E2E_COUNTER "E2Eカウンタ
";
CM_ SG_ 794 ADAS31A_0_0_E2E_CRC "CRC
";
CM_ SG_ 793 ADAS319_2_0_E2E_COUNTER "E2Eカウンタ
";
CM_ SG_ 793 ADAS319_0_0_E2E_CRC "CRC
";
CM_ SG_ 792 ADAS318_31_3_FCW_INIT_LAMP "FCW作動灯初期点灯フラグ
";
CM_ SG_ 792 ADAS318_31_2_ADAS_CAUTION_INIT "ADASﾏｽﾀｰｺｰｼｮﾝ初期点灯フラグ
";
CM_ SG_ 792 ADAS318_31_1_LANE_DEP_INIT "車線逸脱抑制機能初期点灯フラグ
";
CM_ SG_ 792 ADAS318_31_0_PRECRASH_INIT "前方衝突回避機能初期点灯フラグ
";
CM_ SG_ 792 ADAS318_18_0_DISP_RE_WRNG "後方センシング不可表示
";
CM_ SG_ 792 ADAS318_17_6_DISP_RE_SIDE_WRNG "後側方センシング不可表示
";
CM_ SG_ 792 ADAS318_17_4_DISP_FR_SIDE_WRNG "前側方センシング不可表示
";
CM_ SG_ 792 ADAS318_17_2_DISP_FR_WRNG "前方センシング不可表示
";
CM_ SG_ 792 ADAS318_17_0_DISP_ALL_WRNG "全方位センシング不可表示
";
CM_ SG_ 792 ADAS318_13_0_MSG_SIGN_UNRECOG "標識認識不可通知
";
CM_ SG_ 792 ADAS318_12_7_MSG_STRG_TS_WRNG "ステアリングタッチセンサ故障通知
";
CM_ SG_ 792 ADAS318_12_6_MSG_ADAS_SYS_ICON "ADAS機能停止通知(カスタマイズ)
";
CM_ SG_ 792 ADAS318_12_5_MSG_ADAS_FUNC_OFF "ADAS機能停止通知(共連れ)
";
CM_ SG_ 792 ADAS318_12_4_MSG_ADAS_HALT "高度運転支援一時停止通知
";
CM_ SG_ 792 ADAS318_12_3_MSG_ADAS_FAIL "高度運転支援故障通知
";
CM_ SG_ 792 ADAS318_12_2_MSG_PASS_MRM_HALT "同乗者MRM一時停止通知
";
CM_ SG_ 792 ADAS318_12_1_MSG_PASS_MRM_FAIL "同乗者MRM故障通知
";
CM_ SG_ 792 ADAS318_12_0_MSG_SNR_HALT "クリアランスソナー一時停止通知
";
CM_ SG_ 792 ADAS318_11_7_MSG_RAB_PED_HALT "歩行者RAB一時停止通知
";
CM_ SG_ 792 ADAS318_11_6_MSG_RAB_PED_FAIL "歩行者RABフェール通知
";
CM_ SG_ 792 ADAS318_11_5_MSG_RAB_HALT "RAB一時停止通知
";
CM_ SG_ 792 ADAS318_11_4_MSG_RAB_FAIL "RABフェール通知
";
CM_ SG_ 792 ADAS318_11_3_MSG_RCR_HALT_BLK "RCR一時停止通知(ブロッケージ)
";
CM_ SG_ 792 ADAS318_11_2_MSG_RCR_HALT "RCR一時停止通知
";
CM_ SG_ 792 ADAS318_11_1_MSG_RCR_FAIL "RCRフェール通知
";
CM_ SG_ 792 ADAS318_11_0_MSG_FCR_HALT "前側方レーダ一時停止通知
";
CM_ SG_ 792 ADAS318_10_7_MSG_FCR_FAIL "前側方レーダフェール通知
";
CM_ SG_ 792 ADAS318_10_6_MSG_MCAM_HALT "単眼カメラ一時停止通知
";
CM_ SG_ 792 ADAS318_10_5_MSG_MCAM_FAIL "単眼カメラフェール通知
";
CM_ SG_ 792 ADAS318_10_4_MSG_EYE_HALT "アイサイト一時停止通知(その他)
";
CM_ SG_ 792 ADAS318_10_3_MSG_EYE_HALT_TEMP "アイサイト一時停止通知(温度)
";
CM_ SG_ 792 ADAS318_10_2_MSG_EYE_HALT_WTR "アイサイト一時停止通知(天候不良)
";
CM_ SG_ 792 ADAS318_10_1_MSG_EYE_FAIL "アイサイトフェール通知
";
CM_ SG_ 792 ADAS318_10_0_MSG_ADASECU_FAIL "ADAS-ECUフェール通知
";
CM_ SG_ 792 ADAS318_9_1_STRG_HAP_WRNG_IND "ステアリングハプティックインジケータ
";
CM_ SG_ 792 ADAS318_9_0_STRG_TS_WRNG_IND "ステアリングタッチセンサインジケータ
";
CM_ SG_ 792 ADAS318_8_7_ELK_OFF_IND "ELK OFFインジケータ
";
CM_ SG_ 792 ADAS318_8_6_AES_OFF_IND "AES OFFインジケータ
";
CM_ SG_ 792 ADAS318_8_5_LDP_OFF_IND "LDP OFFインジケータ
";
CM_ SG_ 792 ADAS318_8_4_LKS_WRNG_IND "LKSインジケータ
";
CM_ SG_ 792 ADAS318_8_3_ACC_WRNG_IND "ACCインジケータ
";
CM_ SG_ 792 ADAS318_8_2_MRM_WRNG_IND "MRMインジケータ
";
CM_ SG_ 792 ADAS318_8_0_DDAW_STATE_IND "DDAWインジケータ
";
CM_ SG_ 792 ADAS318_7_6_ISA_STATE_IND "ISAインジケータ
";
CM_ SG_ 792 ADAS318_7_4_RAB_STATE_IND "RABインジケータ
";
CM_ SG_ 792 ADAS318_7_2_ACPE_STATE_IND "ACPEインジケータ
";
CM_ SG_ 792 ADAS318_7_0_ADAS_STATE_IND "高度運転支援インジケータ
";
CM_ SG_ 792 ADAS318_6_2_RAB_PED_STATE_IND "歩行者RABインジケータ
";
CM_ SG_ 792 ADAS318_6_0_SNR_STATE_IND "クリアランスソナーインジケータ
";
CM_ SG_ 792 ADAS318_5_6_SRVD_STATE_IND "SRVDインジケータ
";
CM_ SG_ 792 ADAS318_5_4_FCTB_STATE_IND "FCTBインジケータ
";
CM_ SG_ 792 ADAS318_5_2_MCAM_STATE_IND "単眼カメラインジケータ
";
CM_ SG_ 792 ADAS318_5_0_EYESIGHT_STATE_IND "EyeSightインジケータ
";
CM_ SG_ 792 ADAS318_3_4_ADAS_CAUTION_IND "ADASマスターコーションインジケータ
";
CM_ SG_ 792 ADAS318_3_2_LANE_DEP_STATE_IND "車線逸脱抑制機能インジケータ
";
CM_ SG_ 792 ADAS318_3_0_PRECRASH_STATE_IND "前方衝突回避機能インジケータ
";
CM_ SG_ 792 ADAS318_2_0_E2E_COUNTER "E2Eカウンタ
";
CM_ SG_ 792 ADAS318_0_0_E2E_CRC "CRC
";
CM_ SG_ 791 ADAS317_18_0_LIGHT_EAM_GREEN2 "EAM点灯指示_緑2灯
";
CM_ SG_ 791 ADAS317_17_0_LIGHT_EAM_GREEN1 "EAM点灯指示_緑1灯
";
CM_ SG_ 791 ADAS317_17_4_LIGHT_EAM_BLUE "EAM点灯指示_青
";
CM_ SG_ 791 ADAS317_16_0_LIGHT_EAM_YELLOW "EAM点灯指示_黄
";
CM_ SG_ 791 ADAS317_16_4_LIGHT_EAM_RED "EAM点灯指示_赤
";
CM_ SG_ 791 ADAS317_15_0_LINK_ICON_POSITION "リンクアイコン_表示位置
";
CM_ SG_ 791 ADAS317_15_2_LINK_ICON_SPD_SIGN "リンクアイコン_速度標識
";
CM_ SG_ 791 ADAS317_15_4_LINK_ICON_CC "リンクアイコン_クルコンアイコン
";
CM_ SG_ 791 ADAS317_14_0_SPD_CONT_ICON_COLOR "速度制御アイコン_色
";
CM_ SG_ 791 ADAS317_14_3_SPD_CONT_ICON_BLINK "速度制御アイコン_点灯滅
";
CM_ SG_ 791 ADAS317_14_4_SPD_CONT_ICON_DIST "速度制御アイコン_距離数値
";
CM_ SG_ 791 ADAS317_12_0_SPD_CONT_ICON_SPEED "速度制御アイコン_制限速度数値
";
CM_ SG_ 791 ADAS317_11_0_SPD_CONT_ICON_TYPE "速度制御アイコン_意匠
";
CM_ SG_ 791 ADAS317_10_0_SAFETY_MODE_PATTERN "安全重視モードアイコン_パターン
";
CM_ SG_ 791 ADAS317_10_2_SAFETY_MODE_COLOR "安全重視モードアイコン_色
";
CM_ SG_ 791 ADAS317_10_5_PDA_STEER_ICON "PDAステア制御アイコン
";
CM_ SG_ 791 ADAS317_9_0_FCW_INIT "FCW作動灯
";
CM_ SG_ 791 ADAS317_9_1_FCTI_ICON_LEFT "FCTIアイコン_左
";
CM_ SG_ 791 ADAS317_9_3_FCTI_ICON_RIGHT "FCTIアイコン_右
";
CM_ SG_ 791 ADAS317_9_5_IND_SAFETY_MODE "アクセル急踏み加速抑制機能ON灯
";
CM_ SG_ 791 ADAS317_9_6_LIMITER_BACK_SPEED "後退速度リミッター設定値表示
";
CM_ SG_ 791 ADAS317_8_0_LCF_ICON "LCFアイコン
";
CM_ SG_ 791 ADAS317_8_3_LCF_ICON_WORD "LCFアイコン_文言有無
";
CM_ SG_ 791 ADAS317_8_4_AD_DRV_ICON "高度運転支援アイコン
";
CM_ SG_ 791 ADAS317_8_6_ODD_ROAD_ICON "ODD対象道路アイコン
";
CM_ SG_ 791 ADAS317_7_0_INFO_SET_SPD "セット車速表示
";
CM_ SG_ 791 ADAS317_6_0_INFO_MAIN_CC "クルコンメイン表示
";
CM_ SG_ 791 ADAS317_6_3_HOLD_DISP "停止保持中HOLD表示
";
CM_ SG_ 791 ADAS317_5_1_ATTENUAT_MUTE "アッテネート_ミュート指示
";
CM_ SG_ 791 ADAS317_5_3_SOUND_STOP_FLAG "音即断フラグ
";
CM_ SG_ 791 ADAS317_5_4_ALARMCODE_SOUND "警報コード_音
";
CM_ SG_ 791 ADAS317_4_6_ALARMCODE_DISP "警報コード_表示
";
CM_ SG_ 791 ADAS317_2_0_E2E_COUNTER "E2Eカウンタ
";
CM_ SG_ 791 ADAS317_0_0_E2E_CRC "CRC
";
CM_ SG_ 2564481097 OBC18DAE049_DIAG_DATA "ﾃﾞｰﾀ
";
CM_ SG_ 2564442592 DNT18DA49E0_DIAG_DATA "ﾃﾞｰﾀ
";
CM_ SG_ 1099 EVCC44B_27_0_EVSE_ID_7_EVCC "EVSE ID_7_EVCC
";
CM_ SG_ 1099 EVCC44B_23_0_EVSE_ID_6_EVCC "EVSE ID_6_EVCC
";
CM_ SG_ 1099 EVCC44B_19_0_EVSE_ID_5_EVCC "EVSE ID_5_EVCC
";
CM_ SG_ 1099 EVCC44B_15_0_EVSE_ID_4_EVCC "EVSE ID_4_EVCC
";
CM_ SG_ 1099 EVCC44B_11_0_EVSE_ID_3_EVCC "EVSE ID_3_EVCC
";
CM_ SG_ 1099 EVCC44B_7_0_EVSE_ID_2_EVCC "EVSE ID_2_EVCC
";
CM_ SG_ 1099 EVCC44B_3_0_EVSE_ID_1_EVCC "EVSE ID_1_EVCC
";
CM_ SG_ 1099 EVCC44B_2_0_E2E_COUNTER "E2Eカウンタ
";
CM_ SG_ 1099 EVCC44B_0_0_E2E_CRC "CRC
";
CM_ SG_ 1094 EVCC446_3_0_CHGMODE "充放電モード
";
CM_ SG_ 1094 EVCC446_3_3_CHGFRM "充電方式
";
CM_ SG_ 1094 EVCC446_3_7_CHGCONNSTA "充電コネクタ接続状態
";
CM_ SG_ 1094 EVCC446_2_0_E2E_COUNTER "E2Eカウンタ
";
CM_ SG_ 1094 EVCC446_0_0_E2E_CRC "CRC
";
CM_ SG_ 1093 EVCC445_4_0_CHGCNRLOCSTT_DISPREQ "充電コネクタロック状態表示要求
";
CM_ SG_ 1093 EVCC445_3_0_DISPREQ "App表示要求ステータス
";
CM_ SG_ 1093 EVCC445_3_1_CNCTCONSTT_DISP "充電コネクタ接続状態
";
CM_ SG_ 1093 EVCC445_3_2_LIDOPSHSTT_DISP "リッド開閉状態
";
CM_ SG_ 1093 EVCC445_3_5_CNCTLCKSTT_DISP "充電コネクタロック状態
";
CM_ SG_ 1093 EVCC445_2_0_E2E_COUNTER "E2Eカウンタ
";
CM_ SG_ 1093 EVCC445_0_0_E2E_CRC "CRC
";
CM_ SG_ 112 SFT070_10_1_PER_UNLOCK "Pギヤ解除許可フラグ
";
CM_ SG_ 112 SFT070_6_1_SFT_SYS_FAIL "シフタCU故障フラグ
";
CM_ SG_ 112 SFT070_6_2_SFT_DIAGCODE_INFO "シフタCUダイアグコード情報
";
CM_ SG_ 112 SFT070_5_2_SFT_FAILSAFE_REQ "シフタCUフェールセーフ要求
";
CM_ SG_ 112 SFT070_5_4_SFT_FAILMASSAGE_REQ "シフタCUフェール時メッセージ要求
";
CM_ SG_ 112 SFT070_5_7_SFT_REJECT_AUTOPARK "シフタCU自動駐車制御リジェクトフラグ
";
CM_ SG_ 112 SFT070_4_0_SFT_DRIVER_OPR "シフタ操作位置情報
";
CM_ SG_ 112 SFT070_4_3_SFT_PSW "ドライバ―P操作フラグ
";
CM_ SG_ 112 SFT070_4_4_SFT_BUZZER "シフタCUブザー吹鳴要求
";
CM_ SG_ 112 SFT070_4_7_SFT_MASSAGE_REQ "シフタCUメッセージ要求
";
CM_ SG_ 112 SFT070_3_0_TARGET_RANGE "目標レンジ位置
";
CM_ SG_ 112 SFT070_3_3_PARKING_GEAR_INFO "シフタPギヤ駆動情報
";
CM_ SG_ 112 SFT070_3_5_DRIVER_REQ_RANGE "ドライバ―要求レンジ位置
";
CM_ SG_ 112 SFT070_2_0_E2E_COUNTER "E2Eカウンタ
";
CM_ SG_ 112 SFT070_0_0_E2E_CRC "CRC
";
CM_ SG_ 1551 ENM60F_26_0_ACCMHVPWR_LC "総エネルギー消費_Last Charge
";
CM_ SG_ 1551 ENM60F_23_7_ACCMHVPWR_TRIPB "総エネルギー消費_TripB
";
CM_ SG_ 1551 ENM60F_21_6_ACCMHVPWR_TRIPA "総エネルギー消費_TripA
";
CM_ SG_ 1551 ENM60F_20_4_OTRACCMHVRATE_LC "その他消費電力割合_Last Charge
";
CM_ SG_ 1551 ENM60F_19_2_ACOUTACCMRATE_LC "車内コンセント使用量割合_Last Charge
";
CM_ SG_ 1551 ENM60F_18_0_BADJACCMHVRATE_LC "バッテリー温調消費電力割合_Last Charge
";
CM_ SG_ 1551 ENM60F_16_6_ACNACCMHVRATE_LC "空調消費電力割合_Last Charge
";
CM_ SG_ 1551 ENM60F_15_4_MOTACCMHVRATE_LC "運転消費電力割合_Last Charge
";
CM_ SG_ 1551 ENM60F_14_2_OTRACCMHVRATE_TRIPB "その他消費電力割合_TripB
";
CM_ SG_ 1551 ENM60F_13_0_ACOUTACCMRATE_TRIPB "車内コンセント使用量割合_TripB
";
CM_ SG_ 1551 ENM60F_11_6_BADJACCMHVRATE_TRIPB "バッテリー温調消費電力割合_TripB
";
CM_ SG_ 1551 ENM60F_10_4_ACNACCMHVRATE_TRIPB "空調消費電力割合_TripB
";
CM_ SG_ 1551 ENM60F_9_2_MOTACCMHVRATE_TRIPB "運転消費電力割合_TripB
";
CM_ SG_ 1551 ENM60F_8_0_OTRACCMHVRATE_TRIPA "その他消費電力割合_TripA
";
CM_ SG_ 1551 ENM60F_6_6_ACOUTACCMRATE_TRIPA "車内コンセント使用量割合_TripA
";
CM_ SG_ 1551 ENM60F_5_4_BADJACCMHVRATE_TRIPA "バッテリー温調消費電力割合_TripA
";
CM_ SG_ 1551 ENM60F_4_2_ACNACCMHVRATE_TRIPA "空調消費電力割合_TripA
";
CM_ SG_ 1551 ENM60F_3_0_MOTACCMHVRATE_TRIPA "運転消費電力割合_TripA
";
CM_ SG_ 1551 ENM60F_2_0_E2E_COUNTER "E2Eカウンタ
";
CM_ SG_ 1551 ENM60F_0_0_E2E_CRC "CRC
";
CM_ SG_ 1550 ENM60E_28_0_DRNDISPREQ "排水表示要求
";
CM_ SG_ 1550 ENM60E_27_0_INJDISPREQ "注水表示要求
";
CM_ SG_ 1550 ENM60E_26_0_HVBTHMADJSTT "バッテリー温調状態
";
CM_ SG_ 1550 ENM60E_26_1_ACNOFFCMD "エアコン動作状態の表示要求
";
CM_ SG_ 1550 ENM60E_26_3_IJDRMDONOFF "注水排水モード有無
";
CM_ SG_ 1550 ENM60E_26_4_ACNHVDDRVADM "エアコン高圧デバイス駆動許可
";
CM_ SG_ 1550 ENM60E_26_5_ACNINHSIG "空調禁止信号
";
CM_ SG_ 1550 ENM60E_25_0_CNSPPWR_RATE "その他消費電力割合
";
CM_ SG_ 1550 ENM60E_24_0_V2LPWR_RATE "車内コンセント使用量割合
";
CM_ SG_ 1550 ENM60E_23_0_HVBCNSPPWR_RATE "バッテリー温調消費電力割合
";
CM_ SG_ 1550 ENM60E_22_0_ACNPWR_RATE "空調消費電力割合
";
CM_ SG_ 1550 ENM60E_21_0_DRVPWR_RATE "運転消費電力割合
";
CM_ SG_ 1550 ENM60E_20_0_AVECNSPPWR15 "車両平均電費15
";
CM_ SG_ 1550 ENM60E_19_0_AVECNSPPWR14 "車両平均電費14
";
CM_ SG_ 1550 ENM60E_18_0_AVECNSPPWR13 "車両平均電費13
";
CM_ SG_ 1550 ENM60E_17_0_AVECNSPPWR12 "車両平均電費12
";
CM_ SG_ 1550 ENM60E_16_0_AVECNSPPWR11 "車両平均電費11
";
CM_ SG_ 1550 ENM60E_15_0_AVECNSPPWR10 "車両平均電費10
";
CM_ SG_ 1550 ENM60E_14_0_AVECNSPPWR9 "車両平均電費9
";
CM_ SG_ 1550 ENM60E_13_0_AVECNSPPWR8 "車両平均電費8
";
CM_ SG_ 1550 ENM60E_12_0_AVECNSPPWR7 "車両平均電費7
";
CM_ SG_ 1550 ENM60E_11_0_AVECNSPPWR6 "車両平均電費6
";
CM_ SG_ 1550 ENM60E_10_0_AVECNSPPWR5 "車両平均電費5
";
CM_ SG_ 1550 ENM60E_9_0_AVECNSPPWR4 "車両平均電費4
";
CM_ SG_ 1550 ENM60E_8_0_AVECNSPPWR3 "車両平均電費３
";
CM_ SG_ 1550 ENM60E_7_0_AVECNSPPWR2 "車両平均電費２
";
CM_ SG_ 1550 ENM60E_6_0_AVECNSPPWR1 "車両平均電費1
";
CM_ SG_ 1550 ENM60E_5_0_HVBAVETEMP "平均セル温度
";
CM_ SG_ 1550 ENM60E_4_0_AUXCNSPPWR "補機消費電力
";
CM_ SG_ 1550 ENM60E_3_0_ACNCNSPPWR "空調消費電力
";
CM_ SG_ 1550 ENM60E_2_0_E2E_COUNTER "E2Eカウンタ
";
CM_ SG_ 1550 ENM60E_0_0_E2E_CRC "CRC
";
CM_ SG_ 1549 ENM60D_2_0_TOWMDSTS "トーイングステータス
";
CM_ SG_ 1549 ENM60D_1_0_MSG_COUNTER "メッセージカウンタ
";
CM_ SG_ 1549 ENM60D_0_0_CHECK_SUM "チェックサム
";
CM_ SG_ 1548 ENM60C_27_2_VEHPWRTRIPLOG "TRIP LOG用電力積算量
";
CM_ SG_ 1548 ENM60C_26_0_HVBWIN "Win現在値
";
CM_ SG_ 1548 ENM60C_24_6_THMADJPRDWIN "現在のWin見積り値
";
CM_ SG_ 1548 ENM60C_23_3_ACNOFF_DRVRANG "ACOFF時航続可能距離
";
CM_ SG_ 1548 ENM60C_22_0_ACNON_DRVRANG "ACON時航続可能距離
";
CM_ SG_ 1548 ENM60C_21_2_HVBTEMPSTT "表示用バッテリー温度状態
";
CM_ SG_ 1548 ENM60C_20_4_OUTLMTDISREQ "エネマネによる出力制限表示要求
";
CM_ SG_ 1548 ENM60C_20_7_CHGLMTDISREQ "エネマネによる充電制限表示要求
";
CM_ SG_ 1548 ENM60C_19_1_VEHPWREFF_TRIPB "TRIP_B電費
";
CM_ SG_ 1548 ENM60C_17_6_VEHPWREFF_TRIPA "TRIP_A電費
";
CM_ SG_ 1548 ENM60C_16_3_VEHPWREFF_ODO "TRIP_ODO電費
";
CM_ SG_ 1548 ENM60C_15_0_VEHPWREFF "瞬間電費
";
CM_ SG_ 1548 ENM60C_14_0_PRCNSTT "即時プレコン許可状態
";
CM_ SG_ 1548 ENM60C_14_2_PRCNSTTFBK "即時プレコンディショニング状態F/B
";
CM_ SG_ 1548 ENM60C_14_4_ACNLMTDISREQ "エネマネによる空調制限表示要求
";
CM_ SG_ 1548 ENM60C_13_0_STCTDISPREQ "即時プレコン通知表示要求
";
CM_ SG_ 1548 ENM60C_13_3_VEHPRDDIS_JDG "走行可能距離切替情報
";
CM_ SG_ 1548 ENM60C_13_6_PFOMDJDG "パフォーマンスモード判定
";
CM_ SG_ 1548 ENM60C_12_0_HVBTEMP "電池セル温度
";
CM_ SG_ 1548 ENM60C_11_0_HVBTGTTEMP "電池セル目標温度
";
CM_ SG_ 1548 ENM60C_10_0_PFOMDSTP "パフォーマンスモードキャンセル通知
";
CM_ SG_ 1548 ENM60C_10_3_HVBTHMADJSTT "表示用バッテリー温調状態
";
CM_ SG_ 1548 ENM60C_10_6_PFOMDCNTN "パフォーマンスモード継続推奨通知
";
CM_ SG_ 1548 THM60C_10_7_PWRMDJDG "パワーモード判定
";
CM_ SG_ 1548 ENM60C_9_0_ENHCHGTIM "表示用電池温調による充電時間効果
";
CM_ SG_ 1548 ENM60C_8_0_THMADJTIM_PRCNSW "プレコンSWによる電池温調所要時間
";
CM_ SG_ 1548 ENM60C_7_0_THMADJPRDSOC "電池温調予測消費(表示)SOC
";
CM_ SG_ 1548 ENM60C_6_0_HVBTHMADJPWR "表示用電池温調所要電力
";
CM_ SG_ 1548 ENM60C_5_0_THMADJTIM_PFOMD "パフォーマンスモードによる電池温調所要時間
";
CM_ SG_ 1548 ENM60C_4_0_HVBTHMADJTIM "表示用電池温調所要時間
";
CM_ SG_ 1548 ENM60C_3_1_TRLSTSDISREQ "トレーラー接続表示要求
";
CM_ SG_ 1548 ENM60C_3_3_TOWMDFAILDISREQ "トーイング異常時表示要求
";
CM_ SG_ 1548 ENM60C_3_6_CHGTIPDISPREQ "充電Tips通知要求
";
CM_ SG_ 1548 ENM60C_2_0_E2E_COUNTER "E2Eカウンタ
";
CM_ SG_ 1548 ENM60C_0_0_E2E_CRC "CRC
";
CM_ SG_ 857 THM359_5_1_HVBOUTLTEMPREL "電池出口水温センサ信頼性情報
";
CM_ SG_ 857 THM359_4_0_HVBOUTLTEMP "電池出口水温センサ温度
";
CM_ SG_ 857 THM359_3_1_HVBINLTEMPREL "電池入口水温センサ信頼性情報
";
CM_ SG_ 857 THM359_3_3_IJDRMDTRFREQ "注排水移行要求
";
CM_ SG_ 857 THM359_2_0_HVBINLTEMP "電池入口水温センサ温度
";
CM_ SG_ 857 THM359_1_0_MSG_COUNTER "メッセージカウンタ
";
CM_ SG_ 857 THM359_0_0_CHECK_SUM "チェックサム
";
CM_ SG_ 855 THM357_7_0_ACNINVTEMP "エアコンインバータ温度信号
";
CM_ SG_ 855 THM357_6_0_ACNINVINI "エアコンインバータイニシャルフラグ
";
CM_ SG_ 855 THM357_6_1_THMADJRSVCCSSTT "予約空調ステータス
";
CM_ SG_ 855 THM357_5_0_NVLMT "充電中の電池冷却能力向上許可
";
CM_ SG_ 855 THM357_5_1_ACNHVDDRVADM "エアコン高圧デバイス駆動許可
";
CM_ SG_ 855 THM357_5_3_SOAKTIM "ソーク時間
";
CM_ SG_ 855 THM357_4_0_INVCPUABN "エアコンインバータCPUエラーフラグ
";
CM_ SG_ 855 THM357_4_2_ACNINIEXEADM "エアコンイニシャライズ実施許可
";
CM_ SG_ 855 THM357_4_3_ACNINHSIG "空調禁止信号
";
CM_ SG_ 855 THM357_4_4_DRVBATCLG "駆動用電池冷却フラグ
";
CM_ SG_ 855 THM357_4_5_DRVBATWRM "駆動用電池昇温フラグ
";
CM_ SG_ 855 THM357_4_6_OILCLCTADM "オイル回収可否
";
CM_ SG_ 855 THM357_2_0_ACNINPWR "ｴｱｺﾝ入力電力
";
CM_ SG_ 855 THM357_0_0_MSG_COUNTER "メッセージカウンタ
";
CM_ SG_ 855 THM357_0_0_CHECK_SUM "チェックサム
";
CM_ SG_ 854 THM356_7_0_INVTEMPSNSABN "温度センサ異常
";
CM_ SG_ 854 THM356_7_1_STBSTT "STB状態(STBS)
";
CM_ SG_ 854 THM356_7_2_INVINTERR "Internal Error
";
CM_ SG_ 854 THM356_7_4_SELFINVCHK "ｾﾙﾌﾁｪｯｸ
";
CM_ SG_ 854 THM356_7_5_INVINTPWRABN "A/Cｲﾝﾊﾞｰﾀ内部電源異常
";
CM_ SG_ 854 THM356_6_0_INVCURSNSABN "電流センサ異常
";
CM_ SG_ 854 THM356_6_1_ACNMOTCTRLABN "モータ制御異常
";
CM_ SG_ 854 THM356_6_3_ACNCMNSTT_INV "ｴｱｺﾝｲﾝﾊﾞｰﾀ⇔統合ECU通信状態信号(インバータ検出)
";
CM_ SG_ 854 THM356_6_4_CMPSTT "コンプレッサ状態
";
CM_ SG_ 854 THM356_6_7_RESLOTEMPABN "ｻｰﾐｽﾀ低温異常
";
CM_ SG_ 854 THM356_5_2_FRCDAIRCYCLREQ "強制内気要求
";
CM_ SG_ 854 THM356_5_3_ACNCMNSTT_ICU "ｴｱｺﾝｲﾝﾊﾞｰﾀ⇔統合ECU通信状態信号(統合検出)
";
CM_ SG_ 854 THM356_5_4_INVMAINVLTDIAG "A/Cｲﾝﾊﾞｰﾀ主電源電圧ﾀﾞｲｱｸﾞ信号
";
CM_ SG_ 854 THM356_5_6_INVOVRHEAT "過熱系フラグ
";
CM_ SG_ 854 THM356_4_0_ACNSYSADMPWR "エアコンシステム使用許可電力
";
CM_ SG_ 854 THM356_2_0_ACNMOTSPD "A/C用ﾓｰﾀ回転数
";
CM_ SG_ 854 THM356_1_0_MSG_COUNTER "メッセージカウンタ
";
CM_ SG_ 854 THM356_0_0_CHECK_SUM "チェックサム
";
CM_ SG_ 853 THM355_6_0_LTCRFNWASTCALRLV "LTラジ放熱レベル
";
CM_ SG_ 853 THM355_6_3_ACNOVRLDSTT "過負荷警報
";
CM_ SG_ 853 THM355_6_5_STRTLMTSTT "起動制限状態信号
";
CM_ SG_ 853 THM355_6_6_DLYSTRTSTT "スロースタート状態信号
";
CM_ SG_ 853 THM355_5_7_HVHLKCHKOPEREQ "HVH漏電部位特定駆動要求
";
CM_ SG_ 853 THM355_4_0_HWPINSTDUTY "HT W/P指令duty
";
CM_ SG_ 853 THM355_3_2_HVHSTBOP "HVH STB線断線フラグ
";
CM_ SG_ 853 THM355_3_4_HVHSTBSTT "HVH STB状態フラグ
";
CM_ SG_ 853 THM355_3_6_HVHOPEHLD "水加熱ヒータ駆動保持制御状態
";
CM_ SG_ 853 THM355_2_0_HTFWVINSTDEG "HT4方弁駆動指示開度
";
CM_ SG_ 853 THM355_1_0_MSG_COUNTER "メッセージカウンタ
";
CM_ SG_ 853 THM355_0_0_CHECK_SUM "チェックサム
";
CM_ SG_ 852 THM354_7_0_HVHCLTPHI "HVH冷却水温度高温
";
CM_ SG_ 852 THM354_7_5_HVHOVHTSTT "HVHオーバーヒート検出
";
CM_ SG_ 852 THM354_7_7_HVHINTCMNABN "HVH内部通信エラー
";
CM_ SG_ 852 THM354_6_0_HVHVLT "HVH12Ｖ側電圧値
";
CM_ SG_ 852 THM354_5_0_HVHACTCNSPCUR "HVH実消費電流
";
CM_ SG_ 852 THM354_4_0_HVHINLCLTP "HVH入口水温
";
CM_ SG_ 852 THM354_3_0_HVHOUTLCLTP "HVH出口水温
";
CM_ SG_ 852 THM354_2_0_HVHIGBTABN "HVH　IGBT異常検出
";
CM_ SG_ 852 THM354_2_1_HVHSTBSTT "HVH STB状態フラグ
";
CM_ SG_ 852 THM354_2_3_HVHMEMABN "HVHメモリーエラー
";
CM_ SG_ 852 THM354_2_4_HVHSERVREQ "HVHサービス要求
";
CM_ SG_ 852 THM354_2_5_HVHSTTFBK "HVH状態フィードバック
";
CM_ SG_ 852 THM354_1_0_MSG_COUNTER "メッセージカウンタ
";
CM_ SG_ 852 THM354_1_4_HVHINLCLTPABN "HVH入口水温センサ異常
";
CM_ SG_ 852 THM354_1_5_HVHOUTLCLTPABN "HVH出口水温センサ異常
";
CM_ SG_ 852 THM354_1_6_HVHOVHTABN "HVHオーバーヒート検出センサ異常
";
CM_ SG_ 852 THM354_1_7_HVHLINABN "HVH LIN通信エラー
";
CM_ SG_ 852 THM354_0_0_CHECK_SUM "チェックサム
";
CM_ SG_ 851 THM353_7_5_LTCHTGLV "LT回路昇温レベル
";
CM_ SG_ 851 THM353_6_2_IMXANSCALR "水水IMX回答熱量
";
CM_ SG_ 851 THM353_5_1_LTCHTGTGTCLTP "LT回路昇温目標水温
";
CM_ SG_ 851 THM353_4_0_LTCCLGTGTCLTP "LT回路冷却目標水温
";
CM_ SG_ 851 THM353_3_3_LTCCLGLV "LT回路冷却レベル
";
CM_ SG_ 851 THM353_3_6_DEFRANS "除霜要求に対する回答
";
CM_ SG_ 851 THM353_3_7_CDVINIREQ "10方弁イニシャライズ要求
";
CM_ SG_ 851 THM353_2_0_CHILANSCALR "チラー回答吸熱量
";
CM_ SG_ 851 THM353_1_0_MSG_COUNTER "メッセージカウンタ
";
CM_ SG_ 851 THM353_1_4_CHILCLTPCHNGSTT "チラー水温急変状態
";
CM_ SG_ 851 THM353_0_0_CHECK_SUM "チェックサム
";
CM_ SG_ 850 THM352_7_2_HVHOVHTSTT "HVHオーバーヒート検出
";
CM_ SG_ 850 THM352_7_4_HVHINLCLTPABN "HVH入口水温センサ異常
";
CM_ SG_ 850 THM352_7_5_HVHOUTLCLTPABN "HVH出口水温センサ異常
";
CM_ SG_ 850 THM352_7_6_HVHOVHTABN "HVHオーバーヒート検出センサ異常
";
CM_ SG_ 850 THM352_7_7_HVHLINABN "HVH LIN通信エラー
";
CM_ SG_ 850 THM352_6_0_CDVINDDEG "LT10方弁指示開度
";
CM_ SG_ 850 THM352_5_3_LTCCHNGREQ "LT回路切替要求（空調回路切替判定用）
";
CM_ SG_ 850 THM352_4_6_LTCSTT "LT回路状態（空調回路切替判定用）
";
CM_ SG_ 850 THM352_3_0_BWPINSTDUTY "バッテリーW/P指令duty
";
CM_ SG_ 850 THM352_2_0_RFRCCHNGREQ "冷媒回路切替要求
";
CM_ SG_ 850 THM352_2_4_CHILCLTPCHNGSTT "チラー水温変更有無
";
CM_ SG_ 850 THM352_1_0_MSG_COUNTER "メッセージカウンタ
";
CM_ SG_ 850 THM352_1_4_HVHPRTRUN "HVH保護作動中
";
CM_ SG_ 850 THM352_1_5_BWPSTRTFLG "バッテリー用W/P起動停止フラグ
";
CM_ SG_ 850 THM352_1_6_EXSTTEMPABN "排気温度上昇異常
";
CM_ SG_ 850 THM352_0_0_CHECK_SUM "チェックサム
";
CM_ SG_ 1485 CHR5CD_27_0_EVSE_ID_7_CHR "EVSE_ID_7_CHR
";
CM_ SG_ 1485 CHR5CD_23_0_EVSE_ID_6_CHR "EVSE_ID_6_CHR
";
CM_ SG_ 1485 CHR5CD_19_0_EVSE_ID_5_CHR "EVSE_ID_5_CHR
";
CM_ SG_ 1485 CHR5CD_15_0_EVSE_ID_4_CHR "EVSE_ID_4_CHR
";
CM_ SG_ 1485 CHR5CD_11_0_EVSE_ID_3_CHR "EVSE_ID_3_CHR
";
CM_ SG_ 1485 CHR5CD_7_0_EVSE_ID_2_CHR "EVSE_ID_2_CHR
";
CM_ SG_ 1485 CHR5CD_3_0_EVSE_ID_1_CHR "EVSE_ID_1_CHR
";
CM_ SG_ 1485 CHR5CD_2_0_E2E_COUNTER "E2Eカウンタ
";
CM_ SG_ 1485 CHR5CD_0_0_E2E_CRC "CRC
";
CM_ SG_ 1116 CHR45C_29_0_BYTE21 "開発用変数21
";
CM_ SG_ 1116 CHR45C_28_0_BYTE20 "開発用変数20
";
CM_ SG_ 1116 CHR45C_27_0_BYTE19 "開発用変数19
";
CM_ SG_ 1116 CHR45C_26_0_BYTE18 "開発用変数18
";
CM_ SG_ 1116 CHR45C_25_0_BYTE17 "開発用変数17
";
CM_ SG_ 1116 CHR45C_24_0_BYTE16 "開発用変数16
";
CM_ SG_ 1116 CHR45C_23_0_BYTE15 "開発用変数15
";
CM_ SG_ 1116 CHR45C_22_0_BYTE14 "開発用変数14
";
CM_ SG_ 1116 CHR45C_21_0_BYTE13 "開発用変数13
";
CM_ SG_ 1116 CHR45C_20_0_BYTE12 "開発用変数12
";
CM_ SG_ 1116 CHR45C_19_0_BYTE11 "開発用変数11
";
CM_ SG_ 1116 CHR45C_18_0_BYTE10 "開発用変数10
";
CM_ SG_ 1116 CHR45C_17_0_BYTE9 "開発用変数9
";
CM_ SG_ 1116 CHR45C_16_0_BYTE8 "開発用変数8
";
CM_ SG_ 1116 CHR45C_15_0_BYTE7 "開発用変数7
";
CM_ SG_ 1116 CHR45C_14_0_BYTE6 "開発用変数6
";
CM_ SG_ 1116 CHR45C_13_0_BYTE5 "開発用変数5
";
CM_ SG_ 1116 CHR45C_12_0_BYTE4 "開発用変数4
";
CM_ SG_ 1116 CHR45C_11_0_BYTE3 "開発用変数3
";
CM_ SG_ 1116 CHR45C_10_0_BYTE2 "開発用変数2
";
CM_ SG_ 1116 CHR45C_9_0_LIDLOCK_DISC_DT "リッドロック断線検知
";
CM_ SG_ 1116 CHR45C_9_2_LIDOP "リッド開閉情報
";
CM_ SG_ 1116 CHR45C_8_3_CHGSTARTSTOP "充電開始終了
";
CM_ SG_ 1116 CHR45C_8_2_LIDOP_BUZ_REQ "リッド開_ブザー吹鳴要求
";
CM_ SG_ 1116 CHR45C_8_1_LIDOP_WARDISP_REQ "リッド開_警告表示要求
";
CM_ SG_ 1116 CHR45C_8_0_CHG_CNRCNTSTT "充電コネクタ接続状態(表示用)
";
CM_ SG_ 1116 CHR45C_6_0_FEDPWR_DISP "給電電力（表示用）
";
CM_ SG_ 1116 CHR45C_4_0_CHGPWR_DISP "充電電力（表示用）
";
CM_ SG_ 1116 CHR45C_3_0_CHGFEDSTT "充給電状態
";
CM_ SG_ 1116 CHR45C_2_0_E2E_COUNTER "E2Eカウンタ
";
CM_ SG_ 1116 CHR45C_0_0_E2E_CRC "CRC
";
CM_ SG_ 1111 CHR457_31_0_BYTE29 "開発用変数29
";
CM_ SG_ 1111 CHR457_30_0_BYTE28 "開発用変数28
";
CM_ SG_ 1111 CHR457_29_0_BYTE27 "開発用変数27
";
CM_ SG_ 1111 CHR457_28_0_BYTE26 "開発用変数26
";
CM_ SG_ 1111 CHR457_27_0_BYTE25 "開発用変数25
";
CM_ SG_ 1111 CHR457_26_0_BYTE24 "開発用変数24
";
CM_ SG_ 1111 CHR457_25_0_BYTE23 "開発用変数23
";
CM_ SG_ 1111 CHR457_24_0_BYTE22 "開発用変数22
";
CM_ SG_ 1111 CHR457_23_0_BYTE21 "開発用変数21
";
CM_ SG_ 1111 CHR457_22_0_BYTE20 "開発用変数20
";
CM_ SG_ 1111 CHR457_21_0_BYTE19 "開発用変数19
";
CM_ SG_ 1111 CHR457_20_0_BYTE18 "開発用変数18
";
CM_ SG_ 1111 CHR457_19_0_BYTE17 "開発用変数17
";
CM_ SG_ 1111 CHR457_18_0_BYTE16 "開発用変数16
";
CM_ SG_ 1111 CHR457_17_0_BYTE15 "開発用変数15
";
CM_ SG_ 1111 CHR457_16_0_BYTE14 "開発用変数14
";
CM_ SG_ 1111 CHR457_15_0_BYTE13 "開発用変数13
";
CM_ SG_ 1111 CHR457_14_0_BYTE12 "開発用変数12
";
CM_ SG_ 1111 CHR457_13_0_BYTE11 "開発用変数11
";
CM_ SG_ 1111 CHR457_12_6_ENERGY_CHARGED_DISP "充電電力量(kWh)
";
CM_ SG_ 1111 CHR457_11_7_DLTSOCCALC_FIN "デルタSOC(充電完了後)_統合CU
";
CM_ SG_ 1111 CHR457_11_0_DLTSOCCALC_STRT "デルタSOC(充電開始時)_統合CU
";
CM_ SG_ 1111 CHR457_10_6_STLMT_TYPE "決済方式_統合CU
";
CM_ SG_ 1111 CHR457_10_4_ACDC_INFO "AC/DC 情報_統合CU
";
CM_ SG_ 1111 CHR457_9_0_CHGTIM "充電時間_統合CU
";
CM_ SG_ 1111 CHR457_8_0_BYTE6 "開発用変数6
";
CM_ SG_ 1111 CHR457_7_0_BYTE5 "開発用変数5
";
CM_ SG_ 1111 CHR457_6_4_DCPWRSUPSTOP_DISP "給電停止完了通知(表示用)
";
CM_ SG_ 1111 CHR457_6_0_DCPWRSUPSTRT_DISP "給電開始通知(表示用)
";
CM_ SG_ 1111 CHR457_5_0_CHGSTRTNTCE_DISP "充電開始通知(表示用)
";
CM_ SG_ 1111 CHR457_5_4_CHGENDNTCE_DISP "充電終了通知(表示用)
";
CM_ SG_ 1111 CHR457_4_0_FEDSTPRSN_DISP "給電停止要因
";
CM_ SG_ 1111 CHR457_3_0_CHGSTPRSN_DISP "充電停止要因
";
CM_ SG_ 1111 CHR457_2_0_E2E_COUNTER "E2Eカウンタ
";
CM_ SG_ 1111 CHR457_0_0_E2E_CRC "CRC
";
CM_ SG_ 1109 CHR455_31_3_CHGCNRLOCSTT_DISPREQ "充電コネクタロック状態表示要求
";
CM_ SG_ 1109 CHR455_28_4_VEH_CHGPWRUPLMT "車両受け入れ可能上限電力
";
CM_ SG_ 1109 CHR455_27_4_V2H_MODE "V2H充放電モード
";
CM_ SG_ 1109 CHR455_26_4_DCPWRSUPSTT "DC給電状態
";
CM_ SG_ 1109 CHR455_26_3_CHGMNTDISP_REQ "充電画面表示要求
";
CM_ SG_ 1109 CHR455_26_2_MNTLIT_REQ "画面点灯要求
";
CM_ SG_ 1109 CHR455_25_0_CHGVLT_DISP "充電電圧(表示用)
";
CM_ SG_ 1109 CHR455_23_0_CHGCUR_DISP "充電電流(表示用)
";
CM_ SG_ 1109 CHR455_22_1_CHGSTPCOMP "充電停止完了通知
";
CM_ SG_ 1109 CHR455_20_1_ENERGY_CHARGED_DISP "充電電力量(kWh)
";
CM_ SG_ 1109 CHR455_19_2_DLTSOCCALC_FIN "デルタSOC(充電完了後)_統合CU
";
CM_ SG_ 1109 CHR455_18_3_DLTSOCCALC_STRT "デルタSOC(充電開始時)_統合CU
";
CM_ SG_ 1109 CHR455_18_2_STLMT_TYPE "決済方式_統合CU
";
CM_ SG_ 1109 CHR455_18_1_ACDC_INFO "AC/DC 情報_統合CU
";
CM_ SG_ 1109 CHR455_16_6_EVSEOUTPWR "充電スタンド出力電力
";
CM_ SG_ 1109 CHR455_13_3_CHG_FINTIM "充電完了時間_統合CU
";
CM_ SG_ 1109 CHR455_12_0_CHGTIM "充電時間_統合CU
";
CM_ SG_ 1109 CHR455_10_7_DCPWRSUP_PWR_DISP "DC車両供給電力（表示用）
";
CM_ SG_ 1109 CHR455_8_7_CHGPWR_DISP "充電電力（表示用）
";
CM_ SG_ 1109 CHR455_7_1_DCPWRSUP_ADMTIM "DC給電可能時間
";
CM_ SG_ 1109 CHR455_6_1_CHGSTT "充電状態
";
CM_ SG_ 1109 CHR455_5_2_FED_LOLMT "給電量下限値
";
CM_ SG_ 1109 CHR455_4_6_DCCHG_PWRUPLMT "DC充電電力上限設定値
";
CM_ SG_ 1109 CHR455_4_2_ACCHG_CURUPLMT "AC充電電流上限設定値
";
CM_ SG_ 1109 CHR455_3_3_CHG_HILMT "充電量上限値
";
CM_ SG_ 1109 CHR455_3_1_CHG_CNRLOCSTT "充電コネクタロック状態（表示用）
";
CM_ SG_ 1109 CHR455_3_0_CHG_CNRCNTSTT "充電コネクタ接続状態(表示用)
";
CM_ SG_ 1109 CHR455_2_0_E2E_COUNTER "E2Eカウンタ
";
CM_ SG_ 1109 CHR455_0_0_E2E_CRC "CRC
";
CM_ SG_ 1547 BAT60B_8_0_EXWATTMPERR_CNTR "高電圧_出口水温合理性異常カウンタ
";
CM_ SG_ 1547 BAT60B_7_7_SNSWATTMPERR_CNTR "高電圧_水温センサ合理性異常カウンタ
";
CM_ SG_ 1547 BAT60B_7_6_SNSSMKEMSERR_CNTR "高電圧_排煙異常カウンタ
";
CM_ SG_ 1547 BAT60B_7_5_SNSEXTMP2ERR_CNTR "高電圧_排気温度センサ合理性異常2カウンタ
";
CM_ SG_ 1547 BAT60B_7_4_SNSEXTMP1ERR_CNTR "高電圧_排気温度センサ合理性異常1カウンタ
";
CM_ SG_ 1547 BAT60B_7_3_DEVTSTCK3ERR_CNTR "高電圧_セル温度偏差異常(スタック3)カウンタ
";
CM_ SG_ 1547 BAT60B_7_2_DEVTSTCK2ERR_CNTR "高電圧_セル温度偏差異常(スタック2)カウンタ
";
CM_ SG_ 1547 BAT60B_7_1_DEVTSTCK1ERR_CNTR "高電圧_セル温度偏差異常(スタック1)カウンタ
";
CM_ SG_ 1547 BAT60B_7_0_OVERTLVL2ERR_CNTR "高電圧_セル温度上限超過Lv2異常カウンタ
";
CM_ SG_ 1547 BAT60B_6_7_OVERTLVL1ERR_CNTR "高電圧_セル温度上限超過Lv1異常カウンタ
";
CM_ SG_ 1547 BAT60B_6_6_RESDEVERR_CNTR "高電圧_電池抵抗偏差異常カウンタ
";
CM_ SG_ 1547 BAT60B_6_5_PWLINEOV6ERR_CNTR "高電圧_MSOP評価値超過異常6カウンタ
";
CM_ SG_ 1547 BAT60B_6_4_PWLINEOV5ERR_CNTR "高電圧_MSOP評価値超過異常5カウンタ
";
CM_ SG_ 1547 BAT60B_6_3_PWLINEOV4ERR_CNTR "高電圧_MSOP評価値超過異常4カウンタ
";
CM_ SG_ 1547 BAT60B_6_2_PWLINEOV3ERR_CNTR "高電圧_MSOP評価値超過異常3カウンタ
";
CM_ SG_ 1547 BAT60B_6_1_PWLINEOV2ERR_CNTR "高電圧_MSOP評価値超過異常2カウンタ
";
CM_ SG_ 1547 BAT60B_6_0_PWLINEOV1ERR_CNTR "高電圧_MSOP評価値超過異常1カウンタ
";
CM_ SG_ 1547 BAT60B_5_7_VWOUTOVERERR_CNTR "高電圧_Vwout超過異常カウンタ
";
CM_ SG_ 1547 BAT60B_5_6_VWINOVERERR_CNTR "高電圧_VWin超過異常カウンタ
";
CM_ SG_ 1547 BAT60B_5_5_ACTESTDEVERR_CNTR "高電圧_電池容量低下異常カウンタ
";
CM_ SG_ 1547 BAT60B_5_4_RWOUTUNDERR_CNTR "高電圧_Wout超過異常カウンタ
";
CM_ SG_ 1547 BAT60B_5_3_RWINOVRERR_CNTR "高電圧_Win超過異常カウンタ
";
CM_ SG_ 1547 BAT60B_5_2_HVOFFISOERR_CNTR "高電圧_絶縁抵抗低下異常(HVOFF)カウンタ
";
CM_ SG_ 1547 BAT60B_5_1_HVONISOERR_CNTR "高電圧_絶縁抵抗低下異常(HVON)カウンタ
";
CM_ SG_ 1547 BAT60B_5_0_HVSUMCOMPERR_CNTR "高電圧_セル電圧総和/総電圧比較異常カウンタ
";
CM_ SG_ 1547 BAT60B_4_7_CEUNDULV2ERR_CNTR "高電圧_セル電圧下限Lv2異常カウンタ
";
CM_ SG_ 1547 BAT60B_4_6_CEOVRULV2ERR_CNTR "高電圧_セル電圧上限Lv2異常カウンタ
";
CM_ SG_ 1547 BAT60B_4_5_ICHPEAKERR_CNTR "高電圧_充電過電流異常カウンタ
";
CM_ SG_ 1547 BAT60B_4_4_IDCHAPEAKERR_CNTR "高電圧_放電過電流異常カウンタ
";
CM_ SG_ 1547 BAT60B_4_3_HVOVRULV2ERR_CNTR "高電圧_総電圧上限Lv2異常カウンタ
";
CM_ SG_ 1547 BAT60B_4_2_HVUNDULV2ERR_CNTR "高電圧_総電圧上限Lv2異常カウンタ
";
CM_ SG_ 1547 BAT60B_4_1_CEUNDULV1ERR_CNTR "高電圧_セル電圧下限Lv1異常カウンタ
";
CM_ SG_ 1547 BAT60B_4_0_CEOVRULV1ERR_CNTR "高電圧_セル電圧上限Lv1異常カウンタ
";
CM_ SG_ 1547 BAT60B_3_7_HVOVRULV1ERR_CNTR "高電圧_総電圧上限Lv1異常カウンタ
";
CM_ SG_ 1547 BAT60B_3_6_CEUDIFDYNERR_CNTR "高電圧_セル電圧偏差異常(OCC)カウンタ
";
CM_ SG_ 1547 BAT60B_3_5_OVERSOCERR_CNTR "高電圧_SOC上限異常カウンタ
";
CM_ SG_ 1547 BAT60B_3_4_UNDERSOCERR_CNTR "高電圧_SOC下限異常カウンタ
";
CM_ SG_ 1547 BAT60B_3_3_HVUNDULV1ERR_CNTR "高電圧_総電圧下限Lv1異常カウンタ
";
CM_ SG_ 1547 BAT60B_3_2_ISOMEASERR_CNTR "高電圧_絶縁抵抗測定異常カウンタ
";
CM_ SG_ 1547 BAT60B_3_1_CHGAWINOVERR_CNTR "高電圧_Win超過異常(外部充電中)カウンタ
";
CM_ SG_ 1547 BAT60B_3_0_CEUHIDIFERR_CNTR "高電圧_セル電圧偏差異常(OCV)カウンタ
";
CM_ SG_ 1547 BAT60B_2_0_E2E_COUNTER "E2Eカウンタ
";
CM_ SG_ 1547 BAT60B_0_0_E2E_CRC "CRC
";
CM_ SG_ 1546 BAT60A_29_4_LVB_VOL "高電圧バッテリ_補機電圧
";
CM_ SG_ 1546 BAT60A_29_3_EXWATTMPERR "高電圧_出口水温合理性異常
";
CM_ SG_ 1546 BAT60A_29_2_SNSWATTMPERR "高電圧_水温センサ合理性異常
";
CM_ SG_ 1546 BAT60A_29_1_SNSSMKEMSERR "高電圧_排煙異常
";
CM_ SG_ 1546 BAT60A_29_0_SNSEXTMP2ERR "高電圧_排気温度センサ合理性異常2
";
CM_ SG_ 1546 BAT60A_28_7_SNSEXTMP1ERR "高電圧_排気温度センサ合理性異常1
";
CM_ SG_ 1546 BAT60A_28_6_DEVTSTCK3ERR "高電圧_セル温度偏差異常(スタック3)
";
CM_ SG_ 1546 BAT60A_28_5_DEVTSTCK2ERR "高電圧_セル温度偏差異常(スタック2)
";
CM_ SG_ 1546 BAT60A_28_4_DEVTSTCK1ERR "高電圧_セル温度偏差異常(スタック1)
";
CM_ SG_ 1546 BAT60A_28_3_OVERTLVL2ERR "高電圧_セル温度上限超過Lv2異常
";
CM_ SG_ 1546 BAT60A_28_2_OVERTLVL1ERR "高電圧_セル温度上限超過Lv1異常
";
CM_ SG_ 1546 BAT60A_28_1_RESDEVERR "高電圧_電池抵抗偏差異常
";
CM_ SG_ 1546 BAT60A_28_0_PWLINEOV6ERR "高電圧_MSOP評価値超過異常6
";
CM_ SG_ 1546 BAT60A_27_7_PWLINEOV5ERR "高電圧_MSOP評価値超過異常5
";
CM_ SG_ 1546 BAT60A_27_6_PWLINEOV4ERR "高電圧_MSOP評価値超過異常4
";
CM_ SG_ 1546 BAT60A_27_5_PWLINEOV3ERR "高電圧_MSOP評価値超過異常3
";
CM_ SG_ 1546 BAT60A_27_4_PWLINEOV2ERR "高電圧_MSOP評価値超過異常2
";
CM_ SG_ 1546 BAT60A_27_3_PWLINEOV1ERR "高電圧_MSOP評価値超過異常1
";
CM_ SG_ 1546 BAT60A_27_2_VWOUTOVERERR "高電圧_Vwout超過異常
";
CM_ SG_ 1546 BAT60A_27_1_VWINOVERERR "高電圧_VWin超過異常
";
CM_ SG_ 1546 BAT60A_27_0_ACTESTDEVERR "高電圧_電池容量低下異常
";
CM_ SG_ 1546 BAT60A_26_7_RWOUTUNDERR "高電圧_Wout超過異常
";
CM_ SG_ 1546 BAT60A_26_6_RWINOVRERR "高電圧_Win超過異常
";
CM_ SG_ 1546 BAT60A_26_5_HVOFFISOERR "高電圧_絶縁抵抗低下異常(HVOFF)
";
CM_ SG_ 1546 BAT60A_26_4_HVONISOERR "高電圧_絶縁抵抗低下異常(HVON)
";
CM_ SG_ 1546 BAT60A_26_3_HVSUMCOMPERR "高電圧_セル電圧総和/総電圧比較異常
";
CM_ SG_ 1546 BAT60A_26_2_CEUNDULV2ERR "高電圧_セル電圧下限Lv2異常
";
CM_ SG_ 1546 BAT60A_26_1_CEOVRULV2ERR "高電圧_セル電圧上限Lv2異常
";
CM_ SG_ 1546 BAT60A_26_0_ICHPEAKERR "高電圧_充電過電流異常
";
CM_ SG_ 1546 BAT60A_25_7_IDCHAPEAKERR "高電圧_放電過電流異常
";
CM_ SG_ 1546 BAT60A_25_6_HVOVRULV2ERR "高電圧_総電圧上限Lv2異常
";
CM_ SG_ 1546 BAT60A_25_5_HVUNDULV2ERR "高電圧_総電圧上限Lv2異常
";
CM_ SG_ 1546 BAT60A_25_4_CEUNDULV1ERR "高電圧_セル電圧下限Lv1異常
";
CM_ SG_ 1546 BAT60A_25_3_CEOVRULV1ERR "高電圧_セル電圧上限Lv1異常
";
CM_ SG_ 1546 BAT60A_25_2_HVOVRULV1ERR "高電圧_総電圧上限Lv1異常
";
CM_ SG_ 1546 BAT60A_25_1_CEUDIFDYNERR "高電圧_セル電圧偏差異常(OCC)
";
CM_ SG_ 1546 BAT60A_25_0_OVERSOCERR "高電圧_SOC上限異常
";
CM_ SG_ 1546 BAT60A_24_7_UNDERSOCERR "高電圧_SOC下限異常
";
CM_ SG_ 1546 BAT60A_24_6_HVUNDULV1ERR "高電圧_総電圧下限Lv1異常
";
CM_ SG_ 1546 BAT60A_24_5_ISOMEASERR "高電圧_絶縁抵抗測定異常
";
CM_ SG_ 1546 BAT60A_24_4_CHGAWINOVERR "高電圧_Win超過異常(外部充電中)
";
CM_ SG_ 1546 BAT60A_24_3_CEUHIDIFERR "高電圧_セル電圧偏差異常(OCV)
";
CM_ SG_ 1546 BAT60A_23_6_HVB_OUTLIMFCT "高電圧バッテリ_出力制限要因
";
CM_ SG_ 1546 BAT60A_23_1_HVB_INLIMFCT "高電圧バッテリ_入力制限要因
";
CM_ SG_ 1546 BAT60A_22_4_HVB_WOUT "高電圧バッテリ_Wout
";
CM_ SG_ 1546 BAT60A_21_2_HVB_WIN "高電圧バッテリ_Win
";
CM_ SG_ 1546 BAT60A_20_5_HVB_OPRMODE "高電圧バッテリ_動作モード
";
CM_ SG_ 1546 BAT60A_19_1_HVB_CELLSOHRMIN "高電圧バッテリ_最小セル抵抗劣化率
";
CM_ SG_ 1546 BAT60A_18_2_HVB_CELLSOHRMAX "高電圧バッテリ_最大セル抵抗劣化率
";
CM_ SG_ 1546 BAT60A_17_3_HVB_CELLSOHCMIN "高電圧バッテリ_最小セル容量劣化率
";
CM_ SG_ 1546 BAT60A_16_4_HVB_CELLSOHCMAX "高電圧バッテリ_最大セル容量劣化率
";
CM_ SG_ 1546 BAT60A_15_5_HVB_SOC "高電圧バッテリ_SOC
";
CM_ SG_ 1546 BAT60A_14_5_HVB_WATTEMP "高電圧バッテリ_電池水温
";
CM_ SG_ 1546 BAT60A_13_5_JB_TEMPSNS "JB_温度センサ
";
CM_ SG_ 1546 BAT60A_12_5_HVB_CELLTEMPMINNO "高電圧バッテリ_最小温度セル番号
";
CM_ SG_ 1546 BAT60A_11_5_HVB_CELLTEMPMAXNO "高電圧バッテリ_最大温度セル番号
";
CM_ SG_ 1546 BAT60A_10_5_HVB_CELLTEMPMIN "高電圧バッテリ_最小セル温度
";
CM_ SG_ 1546 BAT60A_9_5_HVB_CELLTEMPMAX "高電圧バッテリ_最大セル温度
";
CM_ SG_ 1546 BAT60A_8_2_HVB_CUR "高電圧バッテリ_電流
";
CM_ SG_ 1546 BAT60A_7_2_HVB_CELLVOLMINNO "高電圧バッテリ_最小電圧セル番号
";
CM_ SG_ 1546 BAT60A_6_2_HVB_CELLVOLMAXNO "高電圧バッテリ_最大電圧セル番号
";
CM_ SG_ 1546 BAT60A_4_5_HVB_CELLVOLMIN "高電圧バッテリ_最小セル電圧
";
CM_ SG_ 1546 BAT60A_3_0_HVB_CELLVOLMAX "高電圧バッテリ_最大セル電圧
";
CM_ SG_ 1546 BAT60A_2_0_E2E_COUNTER "E2Eカウンタ
";
CM_ SG_ 1546 BAT60A_0_0_E2E_CRC "CRC
";
CM_ SG_ 1680 BAT690_28_2_CHG_REMTI_GRF26 "残充電時間_グラフ26
";
CM_ SG_ 1680 BAT690_27_2_CHG_REMTI_GRF25 "残充電時間_グラフ25
";
CM_ SG_ 1680 BAT690_26_2_CHG_REMTI_GRF24 "残充電時間_グラフ24
";
CM_ SG_ 1680 BAT690_25_2_CHG_REMTI_GRF23 "残充電時間_グラフ23
";
CM_ SG_ 1680 BAT690_24_2_CHG_REMTI_GRF22 "残充電時間_グラフ22
";
CM_ SG_ 1680 BAT690_23_2_CHG_REMTI_GRF21 "残充電時間_グラフ21
";
CM_ SG_ 1680 BAT690_22_2_CHG_REMTI_GRF20 "残充電時間_グラフ20
";
CM_ SG_ 1680 BAT690_21_2_CHG_REMTI_GRF19 "残充電時間_グラフ19
";
CM_ SG_ 1680 BAT690_20_2_CHG_REMTI_GRF18 "残充電時間_グラフ18
";
CM_ SG_ 1680 BAT690_19_2_CHG_REMTI_GRF17 "残充電時間_グラフ17
";
CM_ SG_ 1680 BAT690_18_2_CHG_REMTI_GRF16 "残充電時間_グラフ16
";
CM_ SG_ 1680 BAT690_17_2_CHG_REMTI_GRF15 "残充電時間_グラフ15
";
CM_ SG_ 1680 BAT690_16_2_CHG_REMTI_GRF14 "残充電時間_グラフ14
";
CM_ SG_ 1680 BAT690_15_2_CHG_REMTI_GRF13 "残充電時間_グラフ13
";
CM_ SG_ 1680 BAT690_14_2_CHG_REMTI_GRF12 "残充電時間_グラフ12
";
CM_ SG_ 1680 BAT690_13_2_CHG_REMTI_GRF11 "残充電時間_グラフ11
";
CM_ SG_ 1680 BAT690_12_2_CHG_REMTI_GRF10 "残充電時間_グラフ10
";
CM_ SG_ 1680 BAT690_11_2_CHG_REMTI_GRF9 "残充電時間_グラフ9
";
CM_ SG_ 1680 BAT690_10_2_CHG_REMTI_GRF8 "残充電時間_グラフ8
";
CM_ SG_ 1680 BAT690_9_2_CHG_REMTI_GRF7 "残充電時間_グラフ7
";
CM_ SG_ 1680 BAT690_8_2_CHG_REMTI_GRF6 "残充電時間_グラフ6
";
CM_ SG_ 1680 BAT690_7_2_CHG_REMTI_GRF5 "残充電時間_グラフ5
";
CM_ SG_ 1680 BAT690_6_2_CHG_REMTI_GRF4 "残充電時間_グラフ4
";
CM_ SG_ 1680 BAT690_5_2_CHG_REMTI_GRF3 "残充電時間_グラフ3
";
CM_ SG_ 1680 BAT690_4_2_CHG_REMTI_GRF2 "残充電時間_グラフ2
";
CM_ SG_ 1680 BAT690_3_2_CHG_REMTI_GRF1 "残充電時間_グラフ1
";
CM_ SG_ 1680 BAT690_3_0_CHG_REMTI_GRF "残充電時間_グラフ_種類
";
CM_ SG_ 1680 BAT690_2_0_E2E_COUNTER "E2Eカウンタ
";
CM_ SG_ 1680 BAT690_0_0_E2E_CRC "CRC
";
CM_ SG_ 134 BAT086_2_0_E2E_COUNTER "E2Eカウンタ
";
CM_ SG_ 134 BAT086_0_0_E2E_CRC "CRC
";
CM_ SG_ 862 BAT35E_4_4_HVB_CONDCHK_FLG "高電圧バッテリ_点検お知らせ
";
CM_ SG_ 862 BAT35E_3_2_HVB_CTRLSOC_PERC "高電圧バッテリ_制御SOC_perc
";
CM_ SG_ 862 BAT35E_3_0_HVB_WRN_TEMP "高電圧バッテリ_温度通知要求
";
CM_ SG_ 862 BAT35E_2_0_E2E_COUNTER "E2Eカウンタ
";
CM_ SG_ 862 BAT35E_0_0_E2E_CRC "CRC
";
CM_ SG_ 861 BAT35D_28_5_HVB_ACTCHGWIN "高電圧バッテリ_実充電電力(瞬時値)
";
CM_ SG_ 861 BAT35D_27_2_HVB_TEMPAVE "高電圧バッテリ_温度_平均_degC
";
CM_ SG_ 861 BAT35D_25_1_HVB_AVBENE_UPL "高電圧バッテリ_使用可能エネルギー_上限_wh
";
CM_ SG_ 861 BAT35D_23_0_HVB_AVBENE_CUR "高電圧バッテリ_使用可能エネルギー_現在_wh
";
CM_ SG_ 861 BAT35D_20_7_HVB_AVBENE_LOL "高電圧バッテリ_使用可能エネルギー_下限_wh
";
CM_ SG_ 861 BAT35D_18_2_HVB_DISPSOHODO "高電圧バッテリ_表示SOH更新後走行距離
";
CM_ SG_ 861 BAT35D_17_0_HVB_DISPSOH_PERC "高電圧バッテリ_表示SOH_バッテリ劣化率_perc
";
CM_ SG_ 861 BAT35D_15_7_HVB_DISPSOH_R_AH "高電圧バッテリ_表示SOH_リザーブ容量_ah
";
CM_ SG_ 861 BAT35D_14_6_HVB_DISPSOH_AH "高電圧バッテリ_表示SOH_バッテリ容量_ah
";
CM_ SG_ 861 BAT35D_13_0_CHG_REMTI_UPS_ACN "残充電時間_充電量上限設定_空調ON_min
";
CM_ SG_ 861 BAT35D_11_2_CHG_REMTI_UPS "残充電時間_充電量上限設定_空調OFF_min
";
CM_ SG_ 861 BAT35D_9_4_CHG_REMTI_BLK_ACN "残充電時間_バルクSOC_空調ON_min
";
CM_ SG_ 861 BAT35D_7_6_CHG_REMTI_BLK "残充電時間_バルクSOC_空調OFF_min
";
CM_ SG_ 861 BAT35D_6_0_CHG_REMTI_ACN "残充電時間_空調ON_min
";
CM_ SG_ 861 BAT35D_4_2_CHG_REMTI "残充電時間_空調OFF_min
";
CM_ SG_ 861 BAT35D_3_0_HVB_DISPSOC_PERC "高電圧バッテリ_表示SOC_perc
";
CM_ SG_ 861 BAT35D_2_0_E2E_COUNTER "E2Eカウンタ
";
CM_ SG_ 861 BAT35D_0_0_E2E_CRC "CRC
";
CM_ SG_ 1685 BEV695_7_0_BRMK7 "トラシュ用データ7
";
CM_ SG_ 1685 BEV695_6_0_BRMK6 "トラシュ用データ6
";
CM_ SG_ 1685 BEV695_5_0_BRMK5 "トラシュ用データ5
";
CM_ SG_ 1685 BEV695_4_0_BRMK4 "トラシュ用データ4
";
CM_ SG_ 1685 BEV695_3_0_BRMK3 "トラシュ用データ3
";
CM_ SG_ 1685 BEV695_2_0_BRMK2 "トラシュ用データ2
";
CM_ SG_ 1685 BEV695_1_0_BRMK1 "トラシュ用データ1
";
CM_ SG_ 1685 BEV695_0_0_BRMK0 "トラシュ用データ0
";
CM_ SG_ 1539 BEV603_15_0_BATTEMPSTS_DISP "バッテリ温度状態(表示用)
";
CM_ SG_ 1539 BEV603_14_0_RR_MTRTEMPSTS_DISP "Rrモータ温度状態(表示用)
";
CM_ SG_ 1539 BEV603_14_3_FR_MTRTEMPSTS_DISP "Frモータ温度状態(表示用)
";
CM_ SG_ 1539 BEV603_13_0_BATTEMP_DISP "バッテリ温度(表示用)
";
CM_ SG_ 1539 BEV603_12_0_RR_MTRTEMP_DISP "Rrモータ温度(表示用)
";
CM_ SG_ 1539 BEV603_11_0_FR_MTRTEMP_DISP "Frモータ温度(表示用)
";
CM_ SG_ 1539 BEV603_10_2_TRQFLCREQ "トルク変動モード実施中表示要求
";
CM_ SG_ 1539 BEV603_10_4_TRQFLCNG "トルク変動モード禁止表示要求
";
CM_ SG_ 1539 BEV603_10_5_TRQFLCSTATE "トルク変動モード現在値
";
CM_ SG_ 1539 BEV603_10_6_TRQFLCDISP "トルク変動モード表示有無
";
CM_ SG_ 1539 BEV603_10_7_TRQVIBREQ "トルク変動モード実施中表示要求
";
CM_ SG_ 1539 BEV603_9_4_PADL_INHBUZ "パドル禁止時ブザー吹鳴フラグ
";
CM_ SG_ 1539 BEV603_9_5_PADL_LVL "パドル段数
";
CM_ SG_ 1539 BEV603_8_1_XMODE_INH "X-MODE選択禁止フラグ
";
CM_ SG_ 1539 BEV603_8_2_SIDRIVE_INH "SIドライブ選択禁止フラグ
";
CM_ SG_ 1539 BEV603_8_3_SIDRIVE_INHBUZ "SIドライブ禁止ブザー吹鳴フラグ
";
CM_ SG_ 1539 BEV603_8_4_ARBIT_SIDR "SIドライブ調停優先状態
";
CM_ SG_ 1539 BEV603_8_5_SIDRIVE_DISP "SIドライブモード表示情報
";
CM_ SG_ 1539 BEV603_7_4_ADPDEC_INHBUZ "アダプティブ減速禁止ブザー吹鳴フラグ
";
CM_ SG_ 1539 BEV603_7_5_ADPDEC_INH_ALL "アダプティブ減速禁止フラグ
";
CM_ SG_ 1539 BEV603_7_6_ADPDEC_DISP "アダプティブ減速表示情報
";
CM_ SG_ 1539 BEV603_7_7_ADPDEC_EQ "アダプティブ減速装備情報
";
CM_ SG_ 1539 BEV603_6_0_AWD_MODE "AWDモード
";
CM_ SG_ 1539 BEV603_6_3_AWD_STS_DISP "AWDモード割り込み表示要求
";
CM_ SG_ 1539 BEV603_6_4_DECSEL_INHMSG "減速度セレクト割り込み禁止表示要求
";
CM_ SG_ 1539 BEV603_6_7_AWD_MODE_EQUIP "AWDモード機能有無
";
CM_ SG_ 1539 BEV603_5_0_PDLBZR "パドル操作リジェクトブザー
";
CM_ SG_ 1539 BEV603_5_1_SFTDN_PERM "シフトダウン許可フラグ
";
CM_ SG_ 1539 BEV603_5_2_SFTUP_PERM "シフトアップ許可フラグ
";
CM_ SG_ 1539 BEV603_5_3_GEARSFT_MODE "変速モード
";
CM_ SG_ 1539 BEV603_5_4_DECSEL_INH_INDI "減速度セレクト禁止フラグ_Individual
";
CM_ SG_ 1539 BEV603_5_5_DECSEL_INH_B "減速度セレクト禁止フラグ_B
";
CM_ SG_ 1539 BEV603_5_6_DECSEL_INH_D "減速度セレクト禁止フラグ_D
";
CM_ SG_ 1539 BEV603_5_7_DECSEL_INH_ALL "減速度セレクト禁止フラグ_ALL
";
CM_ SG_ 1539 BEV603_4_1_DECSEL_DISP_INDI "減速度セレクト表示情報_Individual
";
CM_ SG_ 1539 BEV603_4_2_DECSEL_DISP_B "減速度セレクト表示情報_B
";
CM_ SG_ 1539 BEV603_4_4_DECLV_DECSEL "減速度レベル(減速度セレクト)
";
CM_ SG_ 1539 BEV603_4_6_DECSEL_DISP_ALL "減速度セレクト表示情報_ALL
";
CM_ SG_ 1539 BEV603_3_0_GEARLV_MANU "ギア段(多段手動変速)
";
CM_ SG_ 1539 BEV603_3_1_DECSEL_EQ_INDI "減速度セレクト段数装備情報_Individual
";
CM_ SG_ 1539 BEV603_3_2_DECSEL_EQ_B "減速度セレクト段数装備情報_B
";
CM_ SG_ 1539 BEV603_3_4_GEARLV_AUTO "ギア段(多段自動変速)
";
CM_ SG_ 1539 BEV603_3_6_DECSEL_EQ_ALL "減速度セレクト段数装備情報_ALL
";
CM_ SG_ 1539 BEV603_2_0_E2E_COUNTER "E2Eカウンタ
";
CM_ SG_ 1539 BEV603_0_0_E2E_CRC "CRC
";
CM_ SG_ 1538 BEV602_18_0_V2L_OUTLET_VOLTAGE "車内AC給電_コンセント電圧値
";
CM_ SG_ 1538 BEV602_16_0_LV_SYS_STATUS "12V電源システム状態
";
CM_ SG_ 1538 BEV602_15_0_DCM_REMOTE_INFO "DCMリモート指令情報
";
CM_ SG_ 1538 BEV602_14_7_RR_DISPMSG_RES_UNADJ "RrMG_レゾルバ未調整メッセージ表示要求
";
CM_ SG_ 1538 BEV602_14_6_FR_DISPMSG_RES_UNADJ "FrMG_レゾルバ未調整メッセージ表示要求
";
CM_ SG_ 1538 BEV602_14_4_DISPMSG_SC_SGLPH "Fr/RrMG_一相ON固着メッセージ表示要求
";
CM_ SG_ 1538 BEV602_14_2_CERT2_MODE "認証モード(2WD)
";
CM_ SG_ 1538 BEV602_14_0_SW_PWR_SPL "車内AC給電スイッチON/OFF状態
";
CM_ SG_ 1538 BEV602_13_0_TCSLMP_REQ "TCS作動灯要求
";
CM_ SG_ 1538 BEV602_13_1_AWDLMP_REQ "AWD警告点灯要求
";
CM_ SG_ 1538 BEV602_13_3_AWDWRNMSG_REQ "AWD警告灯メッセージ要求
";
CM_ SG_ 1538 BEV602_12_0_BOSLMP_REQ "BOS作動灯表示要求
";
CM_ SG_ 1538 BEV602_11_3_LVB_ABN "12Vバッテリ異常警告
";
CM_ SG_ 1538 BEV602_11_6_CERT4_MODE "認証モード(AWD)
";
CM_ SG_ 1538 BEV602_11_7_CERT2_MODE "認証モード(2WD)
";
CM_ SG_ 1538 BEV602_10_0_FACT_CERT_MODE "工場/認証モード
";
CM_ SG_ 1538 BEV602_10_1_FACT_MODE "工場モード
";
CM_ SG_ 1538 BEV602_10_2_EVBATLO_CAU "電欠警告灯点灯要求
";
CM_ SG_ 1538 BEV602_10_5_PWRLMT_ID "出力制限_原因種別
";
CM_ SG_ 1538 BEV602_9_1_DCRCHK_DSP_REQ "DCR溶着再診断表示要求
";
CM_ SG_ 1538 BEV602_9_4_LVB_FNCLMT_MSG "機能制限アナウンス（制限前の消費電力低減提言含む）
";
CM_ SG_ 1538 BEV602_9_7_CHG_MSG "充電中補助表示_表示要求
";
CM_ SG_ 1538 BEV602_8_0_LVB_ABN_DCDC "12Vバッテリ異常警告_種別（DCDC異常）
";
CM_ SG_ 1538 BEV602_8_4_LVB_ABN_LIB "12Vバッテリ異常通知（Lib）_表示要求
";
CM_ SG_ 1538 BEV602_8_7_CHG_CAU "チャージ警告灯
";
CM_ SG_ 1538 BEV602_7_0_V2L_STOP_MSG "車内AC給電停止要因通知
";
CM_ SG_ 1538 BEV602_6_0_V2L_SOC_LOWLMT "車内AC給電停止SOC値現在設定値
";
CM_ SG_ 1538 BEV602_5_0_V2L_OUTSTS_2 "車内AC給電状態_コンセント2
";
CM_ SG_ 1538 BEV602_5_1_V2L_OUTSTS_1 "車内AC給電状態_コンセント1
";
CM_ SG_ 1538 BEV602_5_2_ACCHCAU "アクセルホールド警報要求
";
CM_ SG_ 1538 BEV602_5_3_EVIND "EVｼｽﾃﾑ機能不全文言信号
";
CM_ SG_ 1538 BEV602_4_0_BEV_OBD_CAU "BEV_OBD警告灯点灯要求
";
CM_ SG_ 1538 BEV602_4_3_EV_CAU "EVコーション点灯要求
";
CM_ SG_ 1538 BEV602_4_5_PIROFF_MSG "引き摺り防止強制停止表示要求
";
CM_ SG_ 1538 BEV602_3_0_DRVRDY "運転可能表示状態
";
CM_ SG_ 1538 BEV602_3_2_RANGE_POS "現在レンジ位置情報
";
CM_ SG_ 1538 BEV602_2_0_E2E_COUNTER "E2Eカウンタ
";
CM_ SG_ 1538 BEV602_0_0_E2E_CRC "CRC
";
CM_ SG_ 541 BEV21D_4_0_V2L_PWR_2 "車内AC給電消費電力_コンセント2
";
CM_ SG_ 541 BEV21D_3_0_V2L_PWR_1 "車内AC給電消費電力_コンセント1
";
CM_ SG_ 541 BEV21D_2_0_E2E_COUNTER "E2Eカウンタ
";
CM_ SG_ 541 BEV21D_0_0_E2E_CRC "CRC
";
CM_ SG_ 269 BEV10D_22_0_SNDGAIN_CHG "音調整ゲインマップ切替信号
";
CM_ SG_ 269 BEV10D_21_0_EVENT_VOL_B "イベント音量B
";
CM_ SG_ 269 BEV10D_20_0_EVENT_VOL_A "イベント音量A
";
CM_ SG_ 269 BEV10D_18_0_RR_MTRTRQ_SND "Rrモータトルク(サウンド用)
";
CM_ SG_ 269 BEV10D_16_0_FR_MTRTRQ_SND "Frモータトルク(サウンド用)
";
CM_ SG_ 269 BEV10D_15_6_ENGON_SND "エンジン始動音演出トリガー
";
CM_ SG_ 269 BEV10D_15_7_BKF_SND "バックファイア音演出トリガー
";
CM_ SG_ 269 BEV10D_14_0_V_ENGRPM_SND "仮想エンジン回転数(サウンド用)
";
CM_ SG_ 269 BEV10D_12_0_V_RZRPM_DISP "レッドゾーン開始回転数
";
CM_ SG_ 269 BEV10D_11_6_SNDOUT_SET "音出力設定
";
CM_ SG_ 269 BEV10D_10_0_V_ENGRPM_DISP "仮想エンジン回転数(表示用)
";
CM_ SG_ 269 BEV10D_9_1_PMINPWRLMTNTC "回生制限(予告)_表示値
";
CM_ SG_ 269 BEV10D_8_0_PMOUTPWRLMTNTC "出力制限(予告)_表示値
";
CM_ SG_ 269 BEV10D_7_2_DCLLO_DISP "減速度低下表示
";
CM_ SG_ 269 BEV10D_7_4_PMINPWRLMTSTS "回生制限状態通知
";
CM_ SG_ 269 BEV10D_7_5_PMOUTPWRLMTSTS "出力制限状態通知
";
CM_ SG_ 269 BEV10D_6_0_PMPWR "車両パワー表示状態量
";
CM_ SG_ 269 BEV10D_5_1_PMINPWRLMT "回生制限_表示値
";
CM_ SG_ 269 BEV10D_4_0_PMOUTPWRLMT "出力制限_表示値
";
CM_ SG_ 269 BEV10D_3_0_LVB_SOC_LIB "12Vバッテリ容量（LiB）
";
CM_ SG_ 269 BEV10D_2_0_E2E_COUNTER "E2Eカウンタ
";
CM_ SG_ 269 BEV10D_0_0_E2E_CRC "CRC
";
CM_ SG_ 495 BEV1EF_6_0_RRMOTROT_BK "リアモータ回転数バックアップ状態
";
CM_ SG_ 495 BEV1EF_6_2_FRMOTROT_BK "フロントモータ回転数バックアップ状態
";
CM_ SG_ 495 BEV1EF_4_0_RRMOTROT "リアモータ回転数
";
CM_ SG_ 495 BEV1EF_2_0_FRMOTROT "フロントモータ回転数
";
CM_ SG_ 495 BEV1EF_1_0_MSG_COUNTER "ﾒｯｾｰｼﾞｶｳﾝﾀ
";
CM_ SG_ 495 BEV1EF_0_0_CHECK_SUM "ﾁｪｯｸｻﾑ
";
CM_ SG_ 494 BEV1EE_3_0_VIN_DATA "VIN Data
";
CM_ SG_ 494 BEV1EE_2_0_VIN_BYTE_NO "VIN ByteNo
";
CM_ SG_ 494 BEV1EE_1_0_MSG_COUNTER "ﾒｯｾｰｼﾞｶｳﾝﾀ
";
CM_ SG_ 494 BEV1EE_0_0_CHECK_SUM "ﾁｪｯｸｻﾑ
";
CM_ SG_ 267 BEV10B_6_7_SPEC8 "特殊分母8
";
CM_ SG_ 267 BEV10B_6_6_SPEC7 "特殊分母7
";
CM_ SG_ 267 BEV10B_6_5_SPEC6 "特殊分母6
";
CM_ SG_ 267 BEV10B_6_4_SPEC5 "特殊分母5
";
CM_ SG_ 267 BEV10B_6_3_SPEC4 "特殊分母4
";
CM_ SG_ 267 BEV10B_6_2_SPEC3 "特殊分母3
";
CM_ SG_ 267 BEV10B_6_1_SPEC2 "特殊分母2
";
CM_ SG_ 267 BEV10B_6_0_SPEC1 "特殊分母1
";
CM_ SG_ 267 BEV10B_5_2_DENO "一般分母
";
CM_ SG_ 267 BEV10B_5_1_PROHIBIT_INC "分子分母インクリメント禁止フラグ
";
CM_ SG_ 267 BEV10B_5_0_PERMIT_INC "一般分母インクリメント許可フラグ
";
CM_ SG_ 267 BEV10B_4_0_DCCNT "ドライビングサイクルカウンタ
";
CM_ SG_ 267 BEV10B_3_2_OBDRDY "OBD Ready状態
";
CM_ SG_ 267 BEV10B_3_0_DRVRDY "運転可能表示状態
";
CM_ SG_ 267 BEV10B_1_0_MSG_COUNTER "ﾒｯｾｰｼﾞｶｳﾝﾀ
";
CM_ SG_ 267 BEV10B_0_0_CHECK_SUM "ﾁｪｯｸｻﾑ
";
CM_ SG_ 117 BEV075_1_0_MSG_COUNTER "ﾒｯｾｰｼﾞｶｳﾝﾀ
";
CM_ SG_ 117 BEV075_0_0_CHECK_SUM "ﾁｪｯｸｻﾑ
";
CM_ SG_ 116 BEV074_7_0_LVPWRDWN "12V電力抑制信号
";
CM_ SG_ 116 BEV074_7_6_CHRCONSTA "充電コネクタ接続状態
";
CM_ SG_ 116 BEV074_7_7_VEHICLE_IGN "車両イグニッション情報
";
CM_ SG_ 116 BEV074_6_0_EV_CAU "EVコーション点灯要求
";
CM_ SG_ 116 BEV074_6_2_BEV_OBD_CAU "BEV_OBD警告灯点灯要求
";
CM_ SG_ 116 BEV074_6_5_SIDRIVE_DISP "SIドライブモード表示情報
";
CM_ SG_ 116 BEV074_5_0_ACCHG_STATE "AC充電状態
";
CM_ SG_ 116 BEV074_5_1_DCCHG_STATE "DC充電状態
";
CM_ SG_ 116 BEV074_5_2_RANGE_DG "シフト故障状態
";
CM_ SG_ 116 BEV074_5_3_ACCP_DG "アクセル故障状態
";
CM_ SG_ 116 BEV074_5_4_REZ_SPD_BK "レゾルバ車速バックアップ状態
";
CM_ SG_ 116 BEV074_5_6_OBDRDY "OBD Ready状態
";
CM_ SG_ 116 BEV074_5_7_FHVB "高電圧バッテリ異常
";
CM_ SG_ 116 BEV074_3_0_RANGE_POS "現在レンジ位置情報
";
CM_ SG_ 116 BEV074_3_3_DRVRDY "運転可能表示状態
";
CM_ SG_ 116 BEV074_3_5_HVSYSTS "高電圧システムステータス
";
CM_ SG_ 116 BEV074_3_7_REZ_SPD_GL "レゾルバ車速_GL
";
CM_ SG_ 116 BEV074_2_0_ACCP_USR "アクセル開度(ユーザー)
";
CM_ SG_ 116 BEV074_1_0_MSG_COUNTER "ﾒｯｾｰｼﾞｶｳﾝﾀ
";
CM_ SG_ 116 BEV074_1_4_RANGE_DG2 "シフト故障状態2
";
CM_ SG_ 116 BEV074_1_5_REZ_SPD_BK "レゾルバ車速バックアップ状態
";
CM_ SG_ 116 BEV074_0_0_CHECK_SUM "ﾁｪｯｸｻﾑ
";
BA_DEF_ SG_  "Fhi_SignalComment" STRING ;
BA_DEF_ SG_  "GenSigInactiveValue" INT 0 10000;
BA_DEF_ SG_  "GenSigStartValue" FLOAT 0 100000000000;
BA_DEF_ SG_  "GenSigSendType" ENUM  "Cyclic","OnWrite","OnWriteWithRepetition","OnChange","OnChangeWithRepetition","IfActive","IfActiveWithRepetition","NoSigSendType";
BA_DEF_ BO_  "MsgRoutingId" STRING ;
BA_DEF_ BO_  "DiagResponse" ENUM  "No","Yes";
BA_DEF_ BO_  "DiagRequest" ENUM  "No","Yes";
BA_DEF_ BO_  "DiagState" ENUM  "No","Yes";
BA_DEF_ BO_  "GenMsgILSupport" ENUM  "No","Yes";
BA_DEF_ BO_  "GenMsgNrOfRepetition" INT 0 999999;
BA_DEF_ BO_  "GenMsgDelayTime" INT 0 1000;
BA_DEF_ BO_  "GenMsgCycleTimeFast" INT 0 10000;
BA_DEF_ BO_  "GenMsgCycleTime" INT 0 10000;
BA_DEF_ BO_  "GenMsgSendType" ENUM  "Cyclic","NotUsed","NotUsed","NotUsed","NotUsed","Cyclic","NotUsed","IfActive","NoMsgSendType";
BA_DEF_ BO_  "CANFD_BRS" ENUM  "0","1";
BA_DEF_ BO_  "VFrameFormat" ENUM  "StandardCAN","ExtendedCAN","reserved","reserved","reserved","reserved","reserved","reserved","reserved","reserved","reserved","reserved","reserved","reserved","StandardCAN_FD","ExtendedCAN_FD";
BA_DEF_DEF_  "Fhi_SignalComment" "";
BA_DEF_DEF_  "GenSigInactiveValue" 0;
BA_DEF_DEF_  "GenSigStartValue" 0;
BA_DEF_DEF_  "GenSigSendType" "NoSigSendType";
BA_DEF_DEF_  "MsgRoutingId" "";
BA_DEF_DEF_  "DiagResponse" "No";
BA_DEF_DEF_  "DiagRequest" "No";
BA_DEF_DEF_  "DiagState" "No";
BA_DEF_DEF_  "GenMsgILSupport" "Yes";
BA_DEF_DEF_  "GenMsgNrOfRepetition" 0;
BA_DEF_DEF_  "GenMsgDelayTime" 0;
BA_DEF_DEF_  "GenMsgCycleTimeFast" 0;
BA_DEF_DEF_  "GenMsgCycleTime" 0;
BA_DEF_DEF_  "GenMsgSendType" "Cyclic";
BA_DEF_DEF_  "CANFD_BRS" "1";
BA_DEF_DEF_  "VFrameFormat" "StandardCAN";
BA_ "GenMsgNrOfRepetition" BO_ 824 2;
BA_ "GenMsgCycleTimeFast" BO_ 824 50;
BA_ "GenMsgDelayTime" BO_ 824 50;
BA_ "GenMsgCycleTime" BO_ 824 100;
BA_ "VFrameFormat" BO_ 824 14;
BA_ "GenMsgNrOfRepetition" BO_ 823 2;
BA_ "GenMsgCycleTimeFast" BO_ 823 50;
BA_ "GenMsgDelayTime" BO_ 823 50;
BA_ "GenMsgCycleTime" BO_ 823 100;
BA_ "VFrameFormat" BO_ 823 14;
BA_ "GenMsgNrOfRepetition" BO_ 822 2;
BA_ "GenMsgCycleTimeFast" BO_ 822 50;
BA_ "GenMsgDelayTime" BO_ 822 50;
BA_ "GenMsgCycleTime" BO_ 822 100;
BA_ "VFrameFormat" BO_ 822 14;
BA_ "GenMsgNrOfRepetition" BO_ 821 2;
BA_ "GenMsgCycleTimeFast" BO_ 821 50;
BA_ "GenMsgDelayTime" BO_ 821 50;
BA_ "GenMsgCycleTime" BO_ 821 100;
BA_ "VFrameFormat" BO_ 821 14;
BA_ "GenMsgNrOfRepetition" BO_ 817 2;
BA_ "GenMsgCycleTimeFast" BO_ 817 50;
BA_ "GenMsgDelayTime" BO_ 817 50;
BA_ "GenMsgCycleTime" BO_ 817 100;
BA_ "VFrameFormat" BO_ 817 14;
BA_ "GenMsgNrOfRepetition" BO_ 813 2;
BA_ "GenMsgCycleTimeFast" BO_ 813 50;
BA_ "GenMsgDelayTime" BO_ 813 50;
BA_ "GenMsgCycleTime" BO_ 813 100;
BA_ "VFrameFormat" BO_ 813 14;
BA_ "GenMsgNrOfRepetition" BO_ 812 2;
BA_ "GenMsgCycleTimeFast" BO_ 812 50;
BA_ "GenMsgDelayTime" BO_ 812 50;
BA_ "GenMsgCycleTime" BO_ 812 100;
BA_ "VFrameFormat" BO_ 812 14;
BA_ "GenMsgNrOfRepetition" BO_ 797 2;
BA_ "GenMsgCycleTimeFast" BO_ 797 50;
BA_ "GenMsgDelayTime" BO_ 797 50;
BA_ "GenMsgCycleTime" BO_ 797 100;
BA_ "VFrameFormat" BO_ 797 14;
BA_ "GenMsgNrOfRepetition" BO_ 796 2;
BA_ "GenMsgCycleTimeFast" BO_ 796 50;
BA_ "GenMsgDelayTime" BO_ 796 50;
BA_ "GenMsgCycleTime" BO_ 796 100;
BA_ "VFrameFormat" BO_ 796 14;
BA_ "GenMsgNrOfRepetition" BO_ 795 2;
BA_ "GenMsgCycleTimeFast" BO_ 795 50;
BA_ "GenMsgDelayTime" BO_ 795 50;
BA_ "GenMsgCycleTime" BO_ 795 100;
BA_ "VFrameFormat" BO_ 795 14;
BA_ "GenMsgNrOfRepetition" BO_ 794 2;
BA_ "GenMsgCycleTimeFast" BO_ 794 50;
BA_ "GenMsgDelayTime" BO_ 794 50;
BA_ "GenMsgCycleTime" BO_ 794 100;
BA_ "VFrameFormat" BO_ 794 14;
BA_ "GenMsgNrOfRepetition" BO_ 793 2;
BA_ "GenMsgCycleTimeFast" BO_ 793 50;
BA_ "GenMsgDelayTime" BO_ 793 50;
BA_ "GenMsgCycleTime" BO_ 793 100;
BA_ "VFrameFormat" BO_ 793 14;
BA_ "GenMsgNrOfRepetition" BO_ 792 2;
BA_ "GenMsgCycleTimeFast" BO_ 792 50;
BA_ "GenMsgDelayTime" BO_ 792 50;
BA_ "GenMsgCycleTime" BO_ 792 100;
BA_ "VFrameFormat" BO_ 792 14;
BA_ "GenMsgNrOfRepetition" BO_ 791 2;
BA_ "GenMsgCycleTimeFast" BO_ 791 50;
BA_ "GenMsgDelayTime" BO_ 791 50;
BA_ "GenMsgCycleTime" BO_ 791 100;
BA_ "VFrameFormat" BO_ 791 14;
BA_ "GenMsgCycleTime" BO_ 276 20;
BA_ "VFrameFormat" BO_ 276 14;
BA_ "VFrameFormat" BO_ 2564481097 1;
BA_ "MsgRoutingId" BO_ 2564481097 "253 ";
BA_ "GenMsgILSupport" BO_ 2564481097 0;
BA_ "DiagResponse" BO_ 2564481097 1;
BA_ "GenMsgNrOfRepetition" BO_ 2564481097 1;
BA_ "GenMsgSendType" BO_ 2564481097 8;
BA_ "MsgRoutingId" BO_ 2564442592 "252 ";
BA_ "GenMsgILSupport" BO_ 2564442592 0;
BA_ "DiagRequest" BO_ 2564442592 1;
BA_ "GenMsgNrOfRepetition" BO_ 2564442592 1;
BA_ "GenMsgSendType" BO_ 2564442592 8;
BA_ "VFrameFormat" BO_ 2564442592 1;
BA_ "GenMsgILSupport" BO_ 1099 0;
BA_ "MsgRoutingId" BO_ 1099 "246 ";
BA_ "GenMsgCycleTime" BO_ 1099 100;
BA_ "VFrameFormat" BO_ 1099 14;
BA_ "GenMsgILSupport" BO_ 1094 0;
BA_ "MsgRoutingId" BO_ 1094 "241 ";
BA_ "GenMsgCycleTime" BO_ 1094 100;
BA_ "VFrameFormat" BO_ 1094 14;
BA_ "GenMsgILSupport" BO_ 1093 0;
BA_ "MsgRoutingId" BO_ 1093 "240 ";
BA_ "GenMsgNrOfRepetition" BO_ 1093 1;
BA_ "GenMsgCycleTime" BO_ 1093 100;
BA_ "VFrameFormat" BO_ 1093 14;
BA_ "GenMsgCycleTime" BO_ 112 8;
BA_ "VFrameFormat" BO_ 112 14;
BA_ "MsgRoutingId" BO_ 1551 "238 ";
BA_ "GenMsgNrOfRepetition" BO_ 1551 3;
BA_ "GenMsgCycleTimeFast" BO_ 1551 20;
BA_ "GenMsgDelayTime" BO_ 1551 10;
BA_ "GenMsgCycleTime" BO_ 1551 1000;
BA_ "VFrameFormat" BO_ 1551 14;
BA_ "MsgRoutingId" BO_ 1550 "237 ";
BA_ "GenMsgNrOfRepetition" BO_ 1550 3;
BA_ "GenMsgCycleTimeFast" BO_ 1550 20;
BA_ "GenMsgDelayTime" BO_ 1550 10;
BA_ "GenMsgCycleTime" BO_ 1550 1000;
BA_ "VFrameFormat" BO_ 1550 14;
BA_ "MsgRoutingId" BO_ 1549 "236 ";
BA_ "GenMsgNrOfRepetition" BO_ 1549 3;
BA_ "GenMsgCycleTimeFast" BO_ 1549 20;
BA_ "GenMsgDelayTime" BO_ 1549 10;
BA_ "GenMsgCycleTime" BO_ 1549 1000;
BA_ "VFrameFormat" BO_ 1549 14;
BA_ "MsgRoutingId" BO_ 1548 "235 ";
BA_ "GenMsgNrOfRepetition" BO_ 1548 3;
BA_ "GenMsgCycleTimeFast" BO_ 1548 20;
BA_ "GenMsgDelayTime" BO_ 1548 10;
BA_ "GenMsgCycleTime" BO_ 1548 1000;
BA_ "VFrameFormat" BO_ 1548 14;
BA_ "MsgRoutingId" BO_ 857 "234 ";
BA_ "GenMsgNrOfRepetition" BO_ 857 3;
BA_ "GenMsgCycleTimeFast" BO_ 857 20;
BA_ "GenMsgDelayTime" BO_ 857 10;
BA_ "GenMsgCycleTime" BO_ 857 100;
BA_ "VFrameFormat" BO_ 857 14;
BA_ "MsgRoutingId" BO_ 855 "233 ";
BA_ "GenMsgNrOfRepetition" BO_ 855 3;
BA_ "GenMsgCycleTimeFast" BO_ 855 20;
BA_ "GenMsgDelayTime" BO_ 855 10;
BA_ "GenMsgCycleTime" BO_ 855 100;
BA_ "VFrameFormat" BO_ 855 14;
BA_ "MsgRoutingId" BO_ 854 "232 ";
BA_ "GenMsgNrOfRepetition" BO_ 854 3;
BA_ "GenMsgCycleTimeFast" BO_ 854 20;
BA_ "GenMsgDelayTime" BO_ 854 10;
BA_ "GenMsgCycleTime" BO_ 854 100;
BA_ "VFrameFormat" BO_ 854 14;
BA_ "MsgRoutingId" BO_ 853 "231 ";
BA_ "GenMsgNrOfRepetition" BO_ 853 3;
BA_ "GenMsgCycleTimeFast" BO_ 853 20;
BA_ "GenMsgDelayTime" BO_ 853 10;
BA_ "GenMsgCycleTime" BO_ 853 100;
BA_ "VFrameFormat" BO_ 853 14;
BA_ "MsgRoutingId" BO_ 852 "230 ";
BA_ "GenMsgNrOfRepetition" BO_ 852 3;
BA_ "GenMsgCycleTimeFast" BO_ 852 20;
BA_ "GenMsgDelayTime" BO_ 852 10;
BA_ "GenMsgCycleTime" BO_ 852 100;
BA_ "VFrameFormat" BO_ 852 14;
BA_ "MsgRoutingId" BO_ 851 "229 ";
BA_ "GenMsgCycleTime" BO_ 851 100;
BA_ "VFrameFormat" BO_ 851 14;
BA_ "MsgRoutingId" BO_ 850 "228 ";
BA_ "GenMsgNrOfRepetition" BO_ 850 3;
BA_ "GenMsgCycleTimeFast" BO_ 850 20;
BA_ "GenMsgDelayTime" BO_ 850 10;
BA_ "GenMsgCycleTime" BO_ 850 100;
BA_ "VFrameFormat" BO_ 850 14;
BA_ "MsgRoutingId" BO_ 1485 "227 ";
BA_ "GenMsgNrOfRepetition" BO_ 1485 3;
BA_ "GenMsgCycleTimeFast" BO_ 1485 100;
BA_ "GenMsgSendType" BO_ 1485 8;
BA_ "VFrameFormat" BO_ 1485 14;
BA_ "MsgRoutingId" BO_ 1116 "226 ";
BA_ "GenMsgCycleTime" BO_ 1116 100;
BA_ "VFrameFormat" BO_ 1116 14;
BA_ "MsgRoutingId" BO_ 1111 "225 ";
BA_ "GenMsgNrOfRepetition" BO_ 1111 3;
BA_ "GenMsgCycleTime" BO_ 1111 100;
BA_ "VFrameFormat" BO_ 1111 14;
BA_ "MsgRoutingId" BO_ 1109 "224 ";
BA_ "GenMsgCycleTime" BO_ 1109 100;
BA_ "VFrameFormat" BO_ 1109 14;
BA_ "GenMsgCycleTime" BO_ 1547 1000;
BA_ "VFrameFormat" BO_ 1547 14;
BA_ "MsgRoutingId" BO_ 1546 "223 ";
BA_ "GenMsgCycleTime" BO_ 1546 1000;
BA_ "VFrameFormat" BO_ 1546 14;
BA_ "MsgRoutingId" BO_ 1680 "222 ";
BA_ "GenMsgCycleTime" BO_ 1680 1000;
BA_ "VFrameFormat" BO_ 1680 14;
BA_ "GenMsgCycleTime" BO_ 134 10;
BA_ "VFrameFormat" BO_ 134 14;
BA_ "MsgRoutingId" BO_ 862 "221 ";
BA_ "GenMsgCycleTime" BO_ 862 100;
BA_ "VFrameFormat" BO_ 862 14;
BA_ "MsgRoutingId" BO_ 861 "220 ";
BA_ "GenMsgCycleTime" BO_ 861 100;
BA_ "VFrameFormat" BO_ 861 14;
BA_ "GenMsgCycleTime" BO_ 1685 1000;
BA_ "VFrameFormat" BO_ 1685 14;
BA_ "MsgRoutingId" BO_ 1539 "218 ";
BA_ "GenMsgNrOfRepetition" BO_ 1539 1;
BA_ "GenMsgDelayTime" BO_ 1539 10;
BA_ "GenMsgCycleTime" BO_ 1539 1000;
BA_ "VFrameFormat" BO_ 1539 14;
BA_ "MsgRoutingId" BO_ 1538 "217 ";
BA_ "GenMsgNrOfRepetition" BO_ 1538 1;
BA_ "GenMsgDelayTime" BO_ 1538 10;
BA_ "GenMsgCycleTime" BO_ 1538 1000;
BA_ "VFrameFormat" BO_ 1538 14;
BA_ "MsgRoutingId" BO_ 541 "216 ";
BA_ "GenMsgCycleTime" BO_ 541 50;
BA_ "VFrameFormat" BO_ 541 14;
BA_ "MsgRoutingId" BO_ 269 "215 ";
BA_ "GenMsgCycleTime" BO_ 269 20;
BA_ "VFrameFormat" BO_ 269 14;
BA_ "MsgRoutingId" BO_ 495 "213 ";
BA_ "GenMsgCycleTime" BO_ 495 30;
BA_ "VFrameFormat" BO_ 495 14;
BA_ "MsgRoutingId" BO_ 494 "212 ";
BA_ "GenMsgCycleTime" BO_ 494 30;
BA_ "VFrameFormat" BO_ 494 14;
BA_ "MsgRoutingId" BO_ 267 "211 ";
BA_ "GenMsgCycleTime" BO_ 267 20;
BA_ "VFrameFormat" BO_ 267 14;
BA_ "MsgRoutingId" BO_ 117 "210 ";
BA_ "GenMsgCycleTime" BO_ 117 10;
BA_ "VFrameFormat" BO_ 117 14;
BA_ "MsgRoutingId" BO_ 116 "209 ";
BA_ "GenMsgCycleTime" BO_ 116 10;
BA_ "VFrameFormat" BO_ 116 14;
BA_ "GenSigStartValue" SG_ 792 ADAS318_31_3_FCW_INIT_LAMP 1;
BA_ "GenSigSendType" SG_ 2564481097 OBC18DAE049_DIAG_DATA 2;
BA_ "GenSigSendType" SG_ 2564442592 DNT18DA49E0_DIAG_DATA 2;
BA_ "GenSigSendType" SG_ 1093 EVCC445_3_0_DISPREQ 3;
BA_ "GenSigStartValue" SG_ 112 SFT070_4_0_SFT_DRIVER_OPR 3;
BA_ "GenSigStartValue" SG_ 112 SFT070_3_0_TARGET_RANGE 5;
BA_ "GenSigStartValue" SG_ 112 SFT070_3_3_PARKING_GEAR_INFO 2;
BA_ "GenSigStartValue" SG_ 112 SFT070_3_5_DRIVER_REQ_RANGE 5;
BA_ "GenSigStartValue" SG_ 1551 ENM60F_26_0_ACCMHVPWR_LC 131070;
BA_ "GenSigStartValue" SG_ 1551 ENM60F_23_7_ACCMHVPWR_TRIPB 131070;
BA_ "GenSigStartValue" SG_ 1551 ENM60F_21_6_ACCMHVPWR_TRIPA 131070;
BA_ "GenSigStartValue" SG_ 1551 ENM60F_20_4_OTRACCMHVRATE_LC 1022;
BA_ "GenSigStartValue" SG_ 1551 ENM60F_19_2_ACOUTACCMRATE_LC 1022;
BA_ "GenSigStartValue" SG_ 1551 ENM60F_18_0_BADJACCMHVRATE_LC 1022;
BA_ "GenSigStartValue" SG_ 1551 ENM60F_16_6_ACNACCMHVRATE_LC 1022;
BA_ "GenSigStartValue" SG_ 1551 ENM60F_15_4_MOTACCMHVRATE_LC 1022;
BA_ "GenSigStartValue" SG_ 1551 ENM60F_14_2_OTRACCMHVRATE_TRIPB 1022;
BA_ "GenSigStartValue" SG_ 1551 ENM60F_13_0_ACOUTACCMRATE_TRIPB 1022;
BA_ "GenSigStartValue" SG_ 1551 ENM60F_11_6_BADJACCMHVRATE_TRIPB 1022;
BA_ "GenSigStartValue" SG_ 1551 ENM60F_10_4_ACNACCMHVRATE_TRIPB 1022;
BA_ "GenSigStartValue" SG_ 1551 ENM60F_9_2_MOTACCMHVRATE_TRIPB 1022;
BA_ "GenSigStartValue" SG_ 1551 ENM60F_8_0_OTRACCMHVRATE_TRIPA 1022;
BA_ "GenSigStartValue" SG_ 1551 ENM60F_6_6_ACOUTACCMRATE_TRIPA 1022;
BA_ "GenSigStartValue" SG_ 1551 ENM60F_5_4_BADJACCMHVRATE_TRIPA 1022;
BA_ "GenSigStartValue" SG_ 1551 ENM60F_4_2_ACNACCMHVRATE_TRIPA 1022;
BA_ "GenSigStartValue" SG_ 1551 ENM60F_3_0_MOTACCMHVRATE_TRIPA 1022;
BA_ "GenSigStartValue" SG_ 1548 ENM60C_26_0_HVBWIN 1023;
BA_ "GenSigStartValue" SG_ 1548 ENM60C_24_6_THMADJPRDWIN 1023;
BA_ "GenSigStartValue" SG_ 1548 ENM60C_23_3_ACNOFF_DRVRANG 1022;
BA_ "GenSigStartValue" SG_ 1548 ENM60C_22_0_ACNON_DRVRANG 1022;
BA_ "GenSigStartValue" SG_ 1548 ENM60C_19_1_VEHPWREFF_TRIPB 2046;
BA_ "GenSigStartValue" SG_ 1548 ENM60C_17_6_VEHPWREFF_TRIPA 2046;
BA_ "GenSigStartValue" SG_ 1548 ENM60C_16_3_VEHPWREFF_ODO 2046;
BA_ "GenSigStartValue" SG_ 1548 ENM60C_15_0_VEHPWREFF 2046;
BA_ "GenSigStartValue" SG_ 1548 ENM60C_13_3_VEHPRDDIS_JDG 2;
BA_ "GenSigStartValue" SG_ 1548 ENM60C_12_0_HVBTEMP 130;
BA_ "GenSigStartValue" SG_ 1548 ENM60C_11_0_HVBTGTTEMP 130;
BA_ "GenSigStartValue" SG_ 1548 ENM60C_9_0_ENHCHGTIM 255;
BA_ "GenSigStartValue" SG_ 1548 ENM60C_8_0_THMADJTIM_PRCNSW 255;
BA_ "GenSigStartValue" SG_ 1548 ENM60C_7_0_THMADJPRDSOC 255;
BA_ "GenSigStartValue" SG_ 1548 ENM60C_6_0_HVBTHMADJPWR 255;
BA_ "GenSigStartValue" SG_ 1548 ENM60C_5_0_THMADJTIM_PFOMD 255;
BA_ "GenSigStartValue" SG_ 1548 ENM60C_4_0_HVBTHMADJTIM 255;
BA_ "GenSigStartValue" SG_ 857 THM359_2_0_HVBINLTEMP 130;
BA_ "GenSigStartValue" SG_ 855 THM357_7_0_ACNINVTEMP 60;
BA_ "GenSigStartValue" SG_ 855 THM357_5_0_NVLMT 1;
BA_ "GenSigStartValue" SG_ 853 THM355_4_0_HWPINSTDUTY 819;
BA_ "GenSigStartValue" SG_ 851 THM353_4_0_LTCCLGTGTCLTP 511;
BA_ "GenSigStartValue" SG_ 850 THM352_3_0_BWPINSTDUTY 819;
BA_ "GenSigSendType" SG_ 1485 CHR5CD_27_0_EVSE_ID_7_CHR 4;
BA_ "GenSigSendType" SG_ 1485 CHR5CD_23_0_EVSE_ID_6_CHR 4;
BA_ "GenSigSendType" SG_ 1485 CHR5CD_19_0_EVSE_ID_5_CHR 4;
BA_ "GenSigSendType" SG_ 1485 CHR5CD_15_0_EVSE_ID_4_CHR 4;
BA_ "GenSigSendType" SG_ 1485 CHR5CD_11_0_EVSE_ID_3_CHR 4;
BA_ "GenSigSendType" SG_ 1485 CHR5CD_7_0_EVSE_ID_2_CHR 4;
BA_ "GenSigSendType" SG_ 1485 CHR5CD_3_0_EVSE_ID_1_CHR 4;
BA_ "GenSigSendType" SG_ 1485 CHR5CD_2_0_E2E_COUNTER 4;
BA_ "GenSigSendType" SG_ 1485 CHR5CD_0_0_E2E_CRC 4;
BA_ "GenSigSendType" SG_ 1111 CHR457_12_6_ENERGY_CHARGED_DISP 3;
BA_ "GenSigSendType" SG_ 1111 CHR457_11_7_DLTSOCCALC_FIN 3;
BA_ "GenSigSendType" SG_ 1111 CHR457_11_0_DLTSOCCALC_STRT 3;
BA_ "GenSigSendType" SG_ 1111 CHR457_10_6_STLMT_TYPE 3;
BA_ "GenSigSendType" SG_ 1111 CHR457_10_4_ACDC_INFO 3;
BA_ "GenSigSendType" SG_ 1111 CHR457_9_0_CHGTIM 3;
BA_ "GenSigSendType" SG_ 1111 CHR457_6_4_DCPWRSUPSTOP_DISP 3;
BA_ "GenSigSendType" SG_ 1111 CHR457_6_0_DCPWRSUPSTRT_DISP 3;
BA_ "GenSigSendType" SG_ 1111 CHR457_5_0_CHGSTRTNTCE_DISP 3;
BA_ "GenSigSendType" SG_ 1111 CHR457_5_4_CHGENDNTCE_DISP 3;
BA_ "GenSigSendType" SG_ 1111 CHR457_4_0_FEDSTPRSN_DISP 3;
BA_ "GenSigSendType" SG_ 1111 CHR457_3_0_CHGSTPRSN_DISP 3;
BA_ "GenSigStartValue" SG_ 1109 CHR455_28_4_VEH_CHGPWRUPLMT 131070;
BA_ "GenSigStartValue" SG_ 1109 CHR455_25_0_CHGVLT_DISP 1022;
BA_ "GenSigStartValue" SG_ 1109 CHR455_23_0_CHGCUR_DISP 65534;
BA_ "GenSigStartValue" SG_ 1109 CHR455_19_2_DLTSOCCALC_FIN 126;
BA_ "GenSigStartValue" SG_ 1109 CHR455_18_3_DLTSOCCALC_STRT 126;
BA_ "GenSigStartValue" SG_ 1109 CHR455_16_6_EVSEOUTPWR 1022;
BA_ "GenSigStartValue" SG_ 1109 CHR455_13_3_CHG_FINTIM 137217726;
BA_ "GenSigStartValue" SG_ 1109 CHR455_10_7_DCPWRSUP_PWR_DISP 254;
BA_ "GenSigStartValue" SG_ 1109 CHR455_7_1_DCPWRSUP_ADMTIM 16382;
BA_ "GenSigStartValue" SG_ 1109 CHR455_6_1_CHGSTT 254;
BA_ "GenSigStartValue" SG_ 1109 CHR455_4_6_DCCHG_PWRUPLMT 14;
BA_ "GenSigStartValue" SG_ 1109 CHR455_4_2_ACCHG_CURUPLMT 14;
BA_ "GenSigStartValue" SG_ 1109 CHR455_3_3_CHG_HILMT 126;
BA_ "GenSigStartValue" SG_ 1680 BAT690_3_0_CHG_REMTI_GRF 3;
BA_ "GenSigStartValue" SG_ 861 BAT35D_28_5_HVB_ACTCHGWIN 65534;
BA_ "GenSigStartValue" SG_ 861 BAT35D_27_2_HVB_TEMPAVE 100;
BA_ "GenSigStartValue" SG_ 861 BAT35D_18_2_HVB_DISPSOHODO 2097150;
BA_ "GenSigStartValue" SG_ 861 BAT35D_17_0_HVB_DISPSOH_PERC 254;
BA_ "GenSigStartValue" SG_ 861 BAT35D_15_7_HVB_DISPSOH_R_AH 510;
BA_ "GenSigStartValue" SG_ 861 BAT35D_14_6_HVB_DISPSOH_AH 510;
BA_ "GenSigStartValue" SG_ 861 BAT35D_13_0_CHG_REMTI_UPS_ACN 16382;
BA_ "GenSigStartValue" SG_ 861 BAT35D_11_2_CHG_REMTI_UPS 16382;
BA_ "GenSigStartValue" SG_ 861 BAT35D_3_0_HVB_DISPSOC_PERC 254;
BA_ "GenSigStartValue" SG_ 1539 BEV603_13_0_BATTEMP_DISP 254;
BA_ "GenSigStartValue" SG_ 1539 BEV603_12_0_RR_MTRTEMP_DISP 254;
BA_ "GenSigStartValue" SG_ 1539 BEV603_11_0_FR_MTRTEMP_DISP 254;
BA_ "GenSigSendType" SG_ 1539 BEV603_10_2_TRQFLCREQ 3;
BA_ "GenSigSendType" SG_ 1539 BEV603_10_4_TRQFLCNG 3;
BA_ "GenSigSendType" SG_ 1539 BEV603_10_5_TRQFLCSTATE 3;
BA_ "GenSigSendType" SG_ 1539 BEV603_10_6_TRQFLCDISP 3;
BA_ "GenSigSendType" SG_ 1539 BEV603_10_7_TRQVIBREQ 3;
BA_ "GenSigSendType" SG_ 1539 BEV603_9_4_PADL_INHBUZ 3;
BA_ "GenSigSendType" SG_ 1539 BEV603_9_5_PADL_LVL 3;
BA_ "GenSigSendType" SG_ 1539 BEV603_8_1_XMODE_INH 3;
BA_ "GenSigSendType" SG_ 1539 BEV603_8_2_SIDRIVE_INH 3;
BA_ "GenSigSendType" SG_ 1539 BEV603_8_3_SIDRIVE_INHBUZ 3;
BA_ "GenSigSendType" SG_ 1539 BEV603_8_4_ARBIT_SIDR 3;
BA_ "GenSigSendType" SG_ 1539 BEV603_8_5_SIDRIVE_DISP 3;
BA_ "GenSigSendType" SG_ 1539 BEV603_7_4_ADPDEC_INHBUZ 3;
BA_ "GenSigSendType" SG_ 1539 BEV603_7_5_ADPDEC_INH_ALL 3;
BA_ "GenSigSendType" SG_ 1539 BEV603_7_6_ADPDEC_DISP 3;
BA_ "GenSigSendType" SG_ 1539 BEV603_7_7_ADPDEC_EQ 3;
BA_ "GenSigSendType" SG_ 1539 BEV603_6_0_AWD_MODE 3;
BA_ "GenSigSendType" SG_ 1539 BEV603_6_3_AWD_STS_DISP 3;
BA_ "GenSigSendType" SG_ 1539 BEV603_6_4_DECSEL_INHMSG 3;
BA_ "GenSigSendType" SG_ 1539 BEV603_6_7_AWD_MODE_EQUIP 3;
BA_ "GenSigSendType" SG_ 1539 BEV603_5_0_PDLBZR 3;
BA_ "GenSigSendType" SG_ 1539 BEV603_5_1_SFTDN_PERM 3;
BA_ "GenSigSendType" SG_ 1539 BEV603_5_2_SFTUP_PERM 3;
BA_ "GenSigSendType" SG_ 1539 BEV603_5_3_GEARSFT_MODE 3;
BA_ "GenSigSendType" SG_ 1539 BEV603_5_4_DECSEL_INH_INDI 3;
BA_ "GenSigSendType" SG_ 1539 BEV603_5_5_DECSEL_INH_B 3;
BA_ "GenSigSendType" SG_ 1539 BEV603_5_6_DECSEL_INH_D 3;
BA_ "GenSigSendType" SG_ 1539 BEV603_5_7_DECSEL_INH_ALL 3;
BA_ "GenSigSendType" SG_ 1539 BEV603_4_1_DECSEL_DISP_INDI 3;
BA_ "GenSigSendType" SG_ 1539 BEV603_4_2_DECSEL_DISP_B 3;
BA_ "GenSigSendType" SG_ 1539 BEV603_4_4_DECLV_DECSEL 3;
BA_ "GenSigSendType" SG_ 1539 BEV603_4_6_DECSEL_DISP_ALL 3;
BA_ "GenSigSendType" SG_ 1539 BEV603_3_0_GEARLV_MANU 3;
BA_ "GenSigSendType" SG_ 1539 BEV603_3_1_DECSEL_EQ_INDI 3;
BA_ "GenSigSendType" SG_ 1539 BEV603_3_2_DECSEL_EQ_B 3;
BA_ "GenSigSendType" SG_ 1539 BEV603_3_4_GEARLV_AUTO 3;
BA_ "GenSigSendType" SG_ 1539 BEV603_3_6_DECSEL_EQ_ALL 3;
BA_ "GenSigSendType" SG_ 1538 BEV602_18_0_V2L_OUTLET_VOLTAGE 3;
BA_ "GenSigSendType" SG_ 1538 BEV602_16_0_LV_SYS_STATUS 3;
BA_ "GenSigSendType" SG_ 1538 BEV602_15_0_DCM_REMOTE_INFO 3;
BA_ "GenSigSendType" SG_ 1538 BEV602_14_4_DISPMSG_SC_SGLPH 3;
BA_ "GenSigSendType" SG_ 1538 BEV602_14_2_CERT2_MODE 3;
BA_ "GenSigSendType" SG_ 1538 BEV602_14_0_SW_PWR_SPL 3;
BA_ "GenSigStartValue" SG_ 1538 BEV602_14_0_SW_PWR_SPL 2;
BA_ "GenSigSendType" SG_ 1538 BEV602_13_0_TCSLMP_REQ 3;
BA_ "GenSigSendType" SG_ 1538 BEV602_13_1_AWDLMP_REQ 3;
BA_ "GenSigSendType" SG_ 1538 BEV602_13_3_AWDWRNMSG_REQ 3;
BA_ "GenSigSendType" SG_ 1538 BEV602_12_0_BOSLMP_REQ 3;
BA_ "GenSigSendType" SG_ 1538 BEV602_11_3_LVB_ABN 3;
BA_ "GenSigSendType" SG_ 1538 BEV602_11_6_CERT4_MODE 3;
BA_ "GenSigSendType" SG_ 1538 BEV602_11_7_CERT2_MODE 3;
BA_ "GenSigSendType" SG_ 1538 BEV602_10_0_FACT_CERT_MODE 3;
BA_ "GenSigSendType" SG_ 1538 BEV602_10_1_FACT_MODE 3;
BA_ "GenSigSendType" SG_ 1538 BEV602_10_2_EVBATLO_CAU 3;
BA_ "GenSigSendType" SG_ 1538 BEV602_10_5_PWRLMT_ID 3;
BA_ "GenSigSendType" SG_ 1538 BEV602_9_1_DCRCHK_DSP_REQ 3;
BA_ "GenSigSendType" SG_ 1538 BEV602_9_4_LVB_FNCLMT_MSG 3;
BA_ "GenSigSendType" SG_ 1538 BEV602_9_7_CHG_MSG 3;
BA_ "GenSigSendType" SG_ 1538 BEV602_8_0_LVB_ABN_DCDC 3;
BA_ "GenSigSendType" SG_ 1538 BEV602_8_4_LVB_ABN_LIB 3;
BA_ "GenSigSendType" SG_ 1538 BEV602_8_7_CHG_CAU 3;
BA_ "GenSigSendType" SG_ 1538 BEV602_7_0_V2L_STOP_MSG 3;
BA_ "GenSigSendType" SG_ 1538 BEV602_6_0_V2L_SOC_LOWLMT 3;
BA_ "GenSigStartValue" SG_ 1538 BEV602_6_0_V2L_SOC_LOWLMT 2000;
BA_ "GenSigSendType" SG_ 1538 BEV602_5_0_V2L_OUTSTS_2 3;
BA_ "GenSigSendType" SG_ 1538 BEV602_5_1_V2L_OUTSTS_1 3;
BA_ "GenSigSendType" SG_ 1538 BEV602_5_2_ACCHCAU 3;
BA_ "GenSigSendType" SG_ 1538 BEV602_5_3_EVIND 3;
BA_ "GenSigSendType" SG_ 1538 BEV602_4_0_BEV_OBD_CAU 3;
BA_ "GenSigSendType" SG_ 1538 BEV602_4_3_EV_CAU 3;
BA_ "GenSigSendType" SG_ 1538 BEV602_4_5_PIROFF_MSG 3;
BA_ "GenSigSendType" SG_ 1538 BEV602_3_0_DRVRDY 3;
BA_ "GenSigSendType" SG_ 1538 BEV602_3_2_RANGE_POS 3;
BA_ "GenSigStartValue" SG_ 1538 BEV602_3_2_RANGE_POS 6;
BA_ "GenSigStartValue" SG_ 269 BEV10D_12_0_V_RZRPM_DISP 255;
BA_ "GenSigStartValue" SG_ 269 BEV10D_3_0_LVB_SOC_LIB 255;
BA_ "GenSigStartValue" SG_ 116 BEV074_3_0_RANGE_POS 6;
VAL_ 792 ADAS318_31_3_FCW_INIT_LAMP 1 "TURN_ON" 0 "TURN_OFF" ;
VAL_ 792 ADAS318_18_0_DISP_RE_WRNG 3 "No_Definition" 2 " FAIL" 1 "HALT" 0 "TURN_OFF" ;
VAL_ 792 ADAS318_17_6_DISP_RE_SIDE_WRNG 3 "No_Definition" 2 "FAIL" 1 "HALT" 0 "TURN_OFF" ;
VAL_ 792 ADAS318_17_4_DISP_FR_SIDE_WRNG 3 "No_Definition" 2 "FAIL" 1 "HALT" 0 "TURN_OFF" ;
VAL_ 792 ADAS318_17_2_DISP_FR_WRNG 3 "No_Definition" 2 "FAIL" 1 "HALT" 0 "TURN_OFF" ;
VAL_ 792 ADAS318_17_0_DISP_ALL_WRNG 3 "No_Definition" 2 "FAIL" 1 "HALT" 0 "TURN_OFF" ;
VAL_ 792 ADAS318_13_0_MSG_SIGN_UNRECOG 1 "TURN_ON" 0 "TURN_OFF" ;
VAL_ 792 ADAS318_12_7_MSG_STRG_TS_WRNG 1 "TURN_ON" 0 "TURN_OFF" ;
VAL_ 792 ADAS318_12_6_MSG_ADAS_SYS_ICON 1 "TURN_ON" 0 "TURN_OFF" ;
VAL_ 792 ADAS318_12_5_MSG_ADAS_FUNC_OFF 1 "TURN_ON" 0 "TURN_OFF" ;
VAL_ 792 ADAS318_12_4_MSG_ADAS_HALT 1 "TURN_ON" 0 "TURN_OFF" ;
VAL_ 792 ADAS318_12_3_MSG_ADAS_FAIL 1 "TURN_ON" 0 "TURN_OFF" ;
VAL_ 792 ADAS318_12_2_MSG_PASS_MRM_HALT 1 "TURN_ON" 0 "TURN_OFF" ;
VAL_ 792 ADAS318_12_1_MSG_PASS_MRM_FAIL 1 "TURN_ON" 0 "TURN_OFF" ;
VAL_ 792 ADAS318_12_0_MSG_SNR_HALT 1 "TURN_ON" 0 "TURN_OFF" ;
VAL_ 792 ADAS318_11_7_MSG_RAB_PED_HALT 1 "TURN_ON" 0 "TURN_OFF" ;
VAL_ 792 ADAS318_11_6_MSG_RAB_PED_FAIL 1 "TURN_ON" 0 "TURN_OFF" ;
VAL_ 792 ADAS318_11_5_MSG_RAB_HALT 1 "TURN_ON" 0 "TURN_OFF" ;
VAL_ 792 ADAS318_11_4_MSG_RAB_FAIL 1 "TURN_ON" 0 "TURN_OFF" ;
VAL_ 792 ADAS318_11_3_MSG_RCR_HALT_BLK 1 "TURN_ON" 0 "TURN_OFF" ;
VAL_ 792 ADAS318_11_2_MSG_RCR_HALT 1 "TURN_ON" 0 "TURN_OFF" ;
VAL_ 792 ADAS318_11_1_MSG_RCR_FAIL 1 "TURN_ON" 0 "TURN_OFF" ;
VAL_ 792 ADAS318_11_0_MSG_FCR_HALT 1 "TURN_ON" 0 "TURN_OFF" ;
VAL_ 792 ADAS318_10_7_MSG_FCR_FAIL 1 "TURN_ON" 0 "TURN_OFF" ;
VAL_ 792 ADAS318_10_6_MSG_MCAM_HALT 1 "TURN_ON" 0 "TURN_OFF" ;
VAL_ 792 ADAS318_10_5_MSG_MCAM_FAIL 1 "TURN_ON" 0 "TURN_OFF" ;
VAL_ 792 ADAS318_10_4_MSG_EYE_HALT 1 "TURN_ON" 0 "TURN_OFF" ;
VAL_ 792 ADAS318_10_3_MSG_EYE_HALT_TEMP 1 "TURN_ON" 0 "TURN_OFF" ;
VAL_ 792 ADAS318_10_2_MSG_EYE_HALT_WTR 1 "TURN_ON" 0 "TURN_OFF" ;
VAL_ 792 ADAS318_10_1_MSG_EYE_FAIL 1 "TURN_ON" 0 "TURN_OFF" ;
VAL_ 792 ADAS318_10_0_MSG_ADASECU_FAIL 1 "TURN_ON" 0 "TURN_OFF" ;
VAL_ 792 ADAS318_9_1_STRG_HAP_WRNG_IND 1 "TURN_ON" 0 "TURN_OFF" ;
VAL_ 792 ADAS318_9_0_STRG_TS_WRNG_IND 1 "TURN_ON" 0 "TURN_OFF" ;
VAL_ 792 ADAS318_8_7_ELK_OFF_IND 1 "TURN_ON" 0 "TURN_OFF" ;
VAL_ 792 ADAS318_8_6_AES_OFF_IND 1 "TURN_ON" 0 "TURN_OFF" ;
VAL_ 792 ADAS318_8_5_LDP_OFF_IND 1 "TURN_ON" 0 "TURN_OFF" ;
VAL_ 792 ADAS318_8_4_LKS_WRNG_IND 1 "TURN_ON" 0 "TURN_OFF" ;
VAL_ 792 ADAS318_8_3_ACC_WRNG_IND 1 "TURN_ON" 0 "TURN_OFF" ;
VAL_ 792 ADAS318_8_2_MRM_WRNG_IND 1 "TURN_ON" 0 "TURN_OFF" ;
VAL_ 792 ADAS318_8_0_DDAW_STATE_IND 3 "No_Definition" 2 "FAIL/HALT" 1 "OFF" 0 "TURN_OFF" ;
VAL_ 792 ADAS318_7_6_ISA_STATE_IND 3 "No_Definition" 2 "FAIL/HALT" 1 "OFF" 0 "TURN_OFF" ;
VAL_ 792 ADAS318_7_4_RAB_STATE_IND 3 "No_Definition" 2 "FAIL/HALT" 1 "OFF" 0 "TURN_OFF" ;
VAL_ 792 ADAS318_7_2_ACPE_STATE_IND 3 "No_Definition" 2 "FAIL/HALT" 1 "OFF" 0 "TURN_OFF" ;
VAL_ 792 ADAS318_6_2_RAB_PED_STATE_IND 3 "No_Definition" 2 "FAIL/HALT" 1 "OFF" 0 "TURN_OFF" ;
VAL_ 792 ADAS318_6_0_SNR_STATE_IND 3 "No_Definition" 2 "FAIL/HALT" 1 "OFF" 0 "TURN_OFF" ;
VAL_ 792 ADAS318_5_6_SRVD_STATE_IND 3 "No_Definition" 2 "FAIL/HALT" 1 "OFF" 0 "TURN_OFF" ;
VAL_ 792 ADAS318_5_4_FCTB_STATE_IND 3 "No_Definition" 2 "FAIL/HALT" 1 "OFF" 0 "TURN_OFF" ;
VAL_ 792 ADAS318_5_2_MCAM_STATE_IND 3 "No_Definition" 2 "FAIL/HALT" 1 "OFF" 0 "TURN_OFF" ;
VAL_ 792 ADAS318_5_0_EYESIGHT_STATE_IND 3 "No_Definition" 2 "FAIL" 1 "HALT" 0 "TURN_OFF" ;
VAL_ 792 ADAS318_3_4_ADAS_CAUTION_IND 3 "No_Definition" 2 "WHITE_ON" 1 "AMBER_ON" 0 "TURN_OFF" ;
VAL_ 792 ADAS318_3_2_LANE_DEP_STATE_IND 3 "No_Definition" 2 "FAIL/HALT" 1 "OFF" 0 "TURN_OFF" ;
VAL_ 792 ADAS318_3_0_PRECRASH_STATE_IND 3 "No_Definition" 2 "FAIL/HALT" 1 "OFF" 0 "TURN_OFF" ;
VAL_ 1093 EVCC445_4_0_CHGCNRLOCSTT_DISPREQ 2 "Lock_Display_Request" 1 "Unlock_Display_Request" 0 "Hidden" ;
VAL_ 1093 EVCC445_3_0_DISPREQ 1 "Request" 0 "No_Request" ;
VAL_ 1093 EVCC445_3_1_CNCTCONSTT_DISP 1 "Connector_Connected" 0 "Connector_Not_Connected" ;
VAL_ 1093 EVCC445_3_2_LIDOPSHSTT_DISP 2 "Lid_Open" 1 "Lid_Closed" 0 "Indeterminate" ;
VAL_ 1093 EVCC445_3_5_CNCTLCKSTT_DISP 2 "Locked_State" 1 "Unlocked_State" 0 "Initial" ;
VAL_ 112 SFT070_6_1_SFT_SYS_FAIL 1 "Fault" 0 "Non fault" ;
VAL_ 112 SFT070_5_2_SFT_FAILSAFE_REQ 3 "-" 2 "-" 1 "ON" 0 "OFF" ;
VAL_ 112 SFT070_5_4_SFT_FAILMASSAGE_REQ 7 "Message pattern 7" 6 "Message pattern 6" 5 "Message pattern 5" 4 "Message pattern 4" 3 "Message pattern 3" 2 "Message pattern 2" 1 "Message pattern 1" 0 "OFF" ;
VAL_ 112 SFT070_4_0_SFT_DRIVER_OPR 7 "-" 6 "-" 5 "-" 4 "Blank" 3 "Home" 2 "Drive" 1 "Neutral" 0 "Reverse" ;
VAL_ 112 SFT070_4_3_SFT_PSW 1 "ON" 0 "OFF" ;
VAL_ 112 SFT070_4_4_SFT_BUZZER 7 "-" 6 "buzzer pattern 6" 5 "buzzer pattern 5" 4 "buzzer pattern 4" 3 "buzzer pattern 3" 2 "buzzer pattern 2" 1 "buzzer pattern 1" 0 "OFF" ;
VAL_ 112 SFT070_4_7_SFT_MASSAGE_REQ 7 "Message pattern 7" 6 "Message pattern 6" 5 "Message pattern 5" 4 "Message pattern 4" 3 "Message pattern 3" 2 "Message pattern 2" 1 "Message pattern 1" 0 "OFF" ;
VAL_ 112 SFT070_3_0_TARGET_RANGE 7 "-" 6 "-" 5 "Hold" 4 "Brake" 3 "Drive" 2 "Neutral" 1 "Reverse" 0 "Park" ;
VAL_ 112 SFT070_3_3_PARKING_GEAR_INFO 3 "-" 2 "Unknown" 1 "Parking" 0 "Not Parking" ;
VAL_ 112 SFT070_3_5_DRIVER_REQ_RANGE 7 "-" 6 "Blank" 5 "Home" 4 "Brake" 3 "Drive" 2 "Neutral" 1 "Reverse" 0 "Park" ;
VAL_ 1550 ENM60E_28_0_DRNDISPREQ 31 "排水前提条件不成立" 30 "排水動作不良" 29 "キャンセル完了" 28 "キャンセル中" 27 "" 26 "" 25 "" 24 "" 23 "" 22 "" 21 "" 20 "" 19 "" 18 "" 17 "" 16 "" 15 "" 14 "" 13 "" 12 "" 11 "" 10 "" 9 "" 8 "" 7 "" 6 "" 5 "" 4 "注水終了完了" 3 "注水終了中" 2 "排水準備完了" 1 "排水準備中" 0 "排水表示要求なし" ;
VAL_ 1550 ENM60E_27_0_INJDISPREQ 31 "注水前提条件不成立" 30 "注水動作不良" 29 "キャンセル完了" 28 "キャンセル中" 27 "" 26 "" 25 "" 24 "" 23 "" 22 "" 21 "" 20 "" 19 "" 18 "" 17 "" 16 "" 15 "" 14 "" 13 "" 12 "注水終了完了" 11 "注水終了中" 10 "エア抜き4回目完了" 9 "エア抜き4回目中" 8 "エア抜き3回目完了" 7 "エア抜き3回目中" 6 "エア抜き2回目完了" 5 "エア抜き2回目中" 4 "エア抜き1回目完了" 3 "エア抜き1回目中" 2 "注水準備完了" 1 "注水準備中" 0 "注水表示要求なし" ;
VAL_ 1550 ENM60E_26_0_HVBTHMADJSTT 1 "バッテリー温調ON" 0 "バッテリー温調OFF" ;
VAL_ 1550 ENM60E_26_1_ACNOFFCMD 3 "Pattern3" 2 "Pattern2" 1 "Pattern1" 0 "OFF" ;
VAL_ 1550 ENM60E_26_3_IJDRMDONOFF 1 "注水排水モードあり" 0 "注水排水モードなし" ;
VAL_ 1550 ENM60E_26_4_ACNHVDDRVADM 1 "許可" 0 "非許可" ;
VAL_ 1550 ENM60E_26_5_ACNINHSIG 1 "許可" 0 "禁止" ;
VAL_ 1549 ENM60D_2_0_TOWMDSTS 1 "ON" 0 "OFF" ;
VAL_ 1548 ENM60C_21_2_HVBTEMPSTT 7 "RESERVED" 6 "RESERVED" 5 "RESERVED" 4 "XTHOT" 3 "HOT" 2 "COLD" 1 "XTCOLD" 0 "OFF" ;
VAL_ 1548 ENM60C_20_4_OUTLMTDISREQ 7 "RESERVED" 6 "RESERVED" 5 "RESERVED" 4 "LV4" 3 "LV3" 2 "LV2" 1 "LV1" 0 "OFF（初期値）" ;
VAL_ 1548 ENM60C_20_7_CHGLMTDISREQ 7 "RESERVED" 6 "RESERVED" 5 "RESERVED" 4 "LV4" 3 "LV3" 2 "LV2" 1 "LV1" 0 "OFF（初期値）" ;
VAL_ 1548 ENM60C_14_0_PRCNSTT 3 "Reserved" 2 "Reserved" 1 "ON" 0 "OFF" ;
VAL_ 1548 ENM60C_14_2_PRCNSTTFBK 3 "Reserved" 2 "ON（CoolDOWN）" 1 "ON（WarmUP）" 0 "OFF" ;
VAL_ 1548 ENM60C_14_4_ACNLMTDISREQ 7 "RESERVED" 6 "RESERVED" 5 "RESERVED" 4 "LV4" 3 "LV3" 2 "LV2" 1 "LV1" 0 "OFF（初期値）" ;
VAL_ 1548 ENM60C_13_0_STCTDISPREQ 7 "RESERVED" 6 "RESERVED" 5 "RESERVED" 4 "RESERVED" 3 "RESERVED" 2 "ON(HOT)" 1 "ON(COOL)" 0 "OFF" ;
VAL_ 1548 ENM60C_13_3_VEHPRDDIS_JDG 7 "バッファ" 6 "バッファ" 5 "バッファ" 4 "バッファ" 3 "バッファ" 2 "--" 1 "ACOFF" 0 "ACON" ;
VAL_ 1548 ENM60C_13_6_PFOMDJDG 3 "未定義" 2 "点滅" 1 "点灯" 0 "OFF" ;
VAL_ 1548 ENM60C_10_0_PFOMDSTP 7 "未定義" 6 "未定義" 5 "未定義" 4 "未定義" 3 "未定義" 2 "未定義" 1 "あり" 0 "なし" ;
VAL_ 1548 ENM60C_10_3_HVBTHMADJSTT 7 "RESERVE" 6 "EMERGENCY" 5 "IMPROVING" 4 "MAX WARM" 3 "WARM" 2 "COOL" 1 "MAX COOL" 0 "OFF" ;
VAL_ 1548 ENM60C_10_6_PFOMDCNTN 1 "あり" 0 "なし" ;
VAL_ 1548 THM60C_10_7_PWRMDJDG 1 "ON" 0 "OFF" ;
VAL_ 1548 ENM60C_3_1_TRLSTSDISREQ 3 "RESERVE" 2 "ON (DISCONNECT)" 1 "ON (CONNECT)" 0 "OFF" ;
VAL_ 1548 ENM60C_3_3_TOWMDFAILDISREQ 1 "ON " 0 "OFF" ;
VAL_ 1548 ENM60C_3_6_CHGTIPDISPREQ 3 "RESERVE" 2 "ON (STOP)" 1 "ON" 0 "OFF" ;
VAL_ 857 THM359_5_1_HVBOUTLTEMPREL 3 "正常" 2 "異常" 1 "仮異常" 0 "未確定" ;
VAL_ 857 THM359_3_1_HVBINLTEMPREL 3 "正常" 2 "異常" 1 "仮異常" 0 "未確定" ;
VAL_ 857 THM359_3_3_IJDRMDTRFREQ 1 "注排水移行要求あり" 0 "注排水移行要求なし" ;
VAL_ 855 THM357_6_0_ACNINVINI 1 "マイコンリセット後" 0 "通常作動可能時 " ;
VAL_ 855 THM357_6_1_THMADJRSVCCSSTT 7 "RESERVED" 6 "RESERVED" 5 "RESERVED" 4 "RESERVED" 3 "RESERVED" 2 "RESERVED" 1 "ON" 0 "OFF" ;
VAL_ 855 THM357_5_0_NVLMT 1 "禁止" 0 "許可" ;
VAL_ 855 THM357_5_1_ACNHVDDRVADM 1 "許可" 0 "非許可" ;
VAL_ 855 THM357_4_0_INVCPUABN 1 "エラー検出時" 0 "正常時 " ;
VAL_ 855 THM357_4_2_ACNINIEXEADM 1 "許可" 0 "禁止" ;
VAL_ 855 THM357_4_3_ACNINHSIG 1 "許可" 0 "禁止" ;
VAL_ 855 THM357_4_4_DRVBATCLG 1 "ON" 0 "OFF" ;
VAL_ 855 THM357_4_5_DRVBATWRM 1 "ON" 0 "OFF" ;
VAL_ 855 THM357_4_6_OILCLCTADM 3 "未使用" 2 "未使用" 1 "可" 0 "否" ;
VAL_ 854 THM356_7_0_INVTEMPSNSABN 1 "Temperature sensor Error (温度センサ異常)" 0 "No error (異常なし)" ;
VAL_ 854 THM356_7_1_STBSTT 1 "ON" 0 "OFF" ;
VAL_ 854 THM356_7_2_INVINTERR 3 "Over Load (過負荷)" 2 "Output Line Open Contact (出力断線) " 1 "Output Line Short  circuit (出力ショート)" 0 "No error (異常なし)" ;
VAL_ 854 THM356_7_4_SELFINVCHK 1 "SECHON(ｲﾝﾊﾞｰﾀの故障)" 0 "SECHOFF(正常)" ;
VAL_ 854 THM356_7_5_INVINTPWRABN 3 "未定義 " 2 "制御電源系 内部電源異常 " 1 "未定義 " 0 "制御電源系 正常 " ;
VAL_ 854 THM356_6_0_INVCURSNSABN 1 "Current sensor Error (電流センサ異常)" 0 "No error (異常なし)" ;
VAL_ 854 THM356_6_1_ACNMOTCTRLABN 3 "A/C System Error (システム異常停止)" 2 "Software Over Current (ソフト過電流)" 1 "Start Fail (起動失敗)" 0 "No error (異常なし)" ;
VAL_ 854 THM356_6_3_ACNCMNSTT_INV 1 "ACICON(サムチェックエラーが５回以上)or(統合ECU→ACインバータ間通信異常)" 0 "ACICOFF(正常時)" ;
VAL_ 854 THM356_6_4_CMPSTT 7 "( Reserved )" 6 "( Reserved )" 5 "Comp out of range (要求回転数異常)" 4 "Comp shutdown (復帰不可異常)" 3 "Comp Stopped (復帰可能異常) " 2 "Comp degraded (コンプレッサ制限運転)" 1 "Comp on (コンプレッサ動作)" 0 "Comp off (コンプレッサ停止)" ;
VAL_ 854 THM356_6_7_RESLOTEMPABN 1 "THCT ON（ｻｰﾐｽﾀが動作保証温度以下）" 0 "THCT OFF(正常) " ;
VAL_ 854 THM356_5_2_FRCDAIRCYCLREQ 1 "要求あり" 0 "要求なし" ;
VAL_ 854 THM356_5_3_ACNCMNSTT_ICU 1 "ON" 0 "OFF" ;
VAL_ 854 THM356_5_4_INVMAINVLTDIAG 3 "主電源電圧がHVｼｽﾃﾑ故障範囲" 2 "主電源電圧が正常範囲以上" 1 "主電源電圧が範囲未満" 0 "主電源電圧正常範囲内にある" ;
VAL_ 854 THM356_5_6_INVOVRHEAT 3 "(Reserved)" 2 "Over heat warning (オーバーヒートによる保護停止(過熱S))" 1 "Low temperature warning (低温警報)" 0 "No error(異状なし)" ;
VAL_ 853 THM355_6_0_LTCRFNWASTCALRLV 7 "未定義" 6 "未定義" 5 "DC-Lv2" 4 "DC-Lv1" 3 "通常-Lv3" 2 "通常-Lv2" 1 "通常-Lv1" 0 "Lv0" ;
VAL_ 853 THM355_6_3_ACNOVRLDSTT 3 "未定義" 2 "過負荷警報　領域2" 1 "過負荷警報　領域１" 0 "異常なし" ;
VAL_ 853 THM355_6_5_STRTLMTSTT 1 "制限中" 0 "未実施" ;
VAL_ 853 THM355_6_6_DLYSTRTSTT 1 "完了" 0 "未実施" ;
VAL_ 853 THM355_5_7_HVHLKCHKOPEREQ 1 "ON" 0 "OFF" ;
VAL_ 853 THM355_3_2_HVHSTBOP 1 "ON" 0 "OFF" ;
VAL_ 853 THM355_3_4_HVHSTBSTT 3 "噛みこみあり" 2 "STB ON" 1 "STB OFF" 0 "未確定" ;
VAL_ 853 THM355_3_6_HVHOPEHLD 3 "(定義なし)" 2 "保持実施中" 1 "保持待機中" 0 "停止" ;
VAL_ 852 THM354_7_0_HVHCLTPHI 1 "警告" 0 "異常無し" ;
VAL_ 852 THM354_7_5_HVHOVHTSTT 1 "あり" 0 "なし" ;
VAL_ 852 THM354_7_7_HVHINTCMNABN 1 "警告" 0 "異常無し" ;
VAL_ 852 THM354_2_0_HVHIGBTABN 1 "異常有り" 0 "異常無し" ;
VAL_ 852 THM354_2_1_HVHSTBSTT 3 "噛みこみあり" 2 "STBON" 1 "STBOFF" 0 "未確定" ;
VAL_ 852 THM354_2_3_HVHMEMABN 1 "異常有り" 0 "異常無し" ;
VAL_ 852 THM354_2_4_HVHSERVREQ 1 "異常有り" 0 "異常無し" ;
VAL_ 852 THM354_2_5_HVHSTTFBK 7 "Resesrved" 6 "Resesrved" 5 "Resesrved" 4 "通常動作モード" 3 "永久ロック" 2 "サービスまでロック" 1 "次回起動までロック" 0 "OFF" ;
VAL_ 852 THM354_1_4_HVHINLCLTPABN 1 "異常有り" 0 "正常" ;
VAL_ 852 THM354_1_5_HVHOUTLCLTPABN 1 "異常有り" 0 "正常" ;
VAL_ 852 THM354_1_6_HVHOVHTABN 1 "異常有り" 0 "正常" ;
VAL_ 851 THM353_7_5_LTCHTGLV 7 "Lv7" 6 "Lv6" 5 "Lv5" 4 "Lv4" 3 "Lv3" 2 "Lv2" 1 "Lv1" 0 "昇温要求無し" ;
VAL_ 851 THM353_3_3_LTCCLGLV 7 "Lv7" 6 "Lv6" 5 "Lv5" 4 "Lv4" 3 "Lv3" 2 "Lv2" 1 "Lv1" 0 "冷却要求無し" ;
VAL_ 851 THM353_3_6_DEFRANS 1 "受諾" 0 "未受諾" ;
VAL_ 851 THM353_3_7_CDVINIREQ 1 "要求あり" 0 "要求なし" ;
VAL_ 851 THM353_1_4_CHILCLTPCHNGSTT 3 "予備" 2 "急上昇" 1 "急低下" 0 "通常" ;
VAL_ 850 THM352_7_2_HVHOVHTSTT 1 "あり" 0 "なし" ;
VAL_ 850 THM352_7_4_HVHINLCLTPABN 1 "異常有り" 0 "正常" ;
VAL_ 850 THM352_7_5_HVHOUTLCLTPABN 1 "異常有り" 0 "正常" ;
VAL_ 850 THM352_7_6_HVHOVHTABN 1 "異常有り" 0 "正常" ;
VAL_ 850 THM352_7_7_HVHLINABN 1 "通信エラー" 0 "正常" ;
VAL_ 850 THM352_5_3_LTCCHNGREQ 13 "チラー熱移動なし_HT_LT間熱移動なし" 12 "チラー熱移動なし_HT_LT間熱移動あり_除霜なし_PT通水あり" 11 "チラー熱移動なし_HT_LT間熱移動あり_除霜なし_PT通水なし" 10 "チラー熱移動なし_HT_LT間熱移動あり_除霜あり" 9 "チラーLTラジエータ間熱移動あり_HT_LT間熱移動なし" 8 "チラー電池間熱移動あり_HT_LT間熱移動なし" 7 "チラーLTデバイス間熱移動あり_HT_LT間熱移動なし_水水HEX通水あり" 6 "チラーLTデバイス間熱移動あり_HT_LT間熱移動なし_水水HEX通水なし" 5 "チラーLTラジエータ間熱移動あり_HT_LT間熱移動あり" 4 "チラー水水HEX間熱移動あり_HT_LT間熱移動あり_電池＆PT通水あり" 3 "チラー水水HEX間熱移動あり_HT_LT間熱移動あり_電池＆PT通水なし" 2 "チラー電池間熱移動あり_HT_LT間熱移動あり_除霜なし" 1 "チラー電池間熱移動あり_HT_LT間熱移動あり_除霜あり" 0 "回路不明_移行要求無し" ;
VAL_ 850 THM352_4_6_LTCSTT 13 "チラー熱移動なし_HT_LT間熱移動なし" 12 "チラー熱移動なし_HT_LT間熱移動あり_除霜なし_PT通水あり" 11 "チラー熱移動なし_HT_LT間熱移動あり_除霜なし_PT通水なし" 10 "チラー熱移動なし_HT_LT間熱移動あり_除霜あり" 9 "チラーLTラジエータ間熱移動あり_HT_LT間熱移動なし" 8 "チラー電池間熱移動あり_HT_LT間熱移動なし" 7 "チラーLTデバイス間熱移動あり_HT_LT間熱移動なし_水水HEX通水あり" 6 "チラーLTデバイス間熱移動あり_HT_LT間熱移動なし_水水HEX通水なし" 5 "チラーLTラジエータ間熱移動あり_HT_LT間熱移動あり" 4 "チラー水水HEX間熱移動あり_HT_LT間熱移動あり_電池＆PT通水あり" 3 "チラー水水HEX間熱移動あり_HT_LT間熱移動あり_電池＆PT通水なし" 2 "チラー電池間熱移動あり_HT_LT間熱移動あり_除霜なし" 1 "チラー電池間熱移動あり_HT_LT間熱移動あり_除霜あり" 0 "回路不明_移行要求無し" ;
VAL_ 850 THM352_2_0_RFRCCHNGREQ 8 "冷媒-D-3_チラー_廃熱HP暖房" 7 "冷媒-D-2_チラー_電池冷却有" 6 "冷媒-D-1_チラー_外気HP_TL" 5 "冷媒-C_OFF" 4 "冷媒-B-3_エバ_チラー_廃熱HP暖房" 3 "冷媒-B-2_エバ_チラー_電池冷却有" 2 "冷媒-B-1_エバ_チラー_外気HP_TL" 1 "冷媒-A_エバ" 0 "移行要求無し" ;
VAL_ 850 THM352_2_4_CHILCLTPCHNGSTT 3 "予備" 2 "水温下降" 1 "水温上昇" 0 "変動なし" ;
VAL_ 850 THM352_1_4_HVHPRTRUN 1 "有り" 0 "無し" ;
VAL_ 850 THM352_1_5_BWPSTRTFLG 1 "動作中" 0 "停止" ;
VAL_ 850 THM352_1_6_EXSTTEMPABN 1 "異常" 0 "正常" ;
VAL_ 1116 CHR45C_9_0_LIDLOCK_DISC_DT 3 "Reserve" 2 "Normal" 1 "Error" 0 "Undetermined" ;
VAL_ 1116 CHR45C_9_2_LIDOP 3 "Reserve" 2 "Lid_Open" 1 "Lid_Closed" 0 "Indeterminate" ;
VAL_ 1116 CHR45C_8_2_LIDOP_BUZ_REQ 1 "HornRequest" 0 "NoHornRequest" ;
VAL_ 1116 CHR45C_8_1_LIDOP_WARDISP_REQ 1 "TextA" 0 "Norequest" ;
VAL_ 1116 CHR45C_8_0_CHG_CNRCNTSTT 1 "嵌合" 0 "未接続" ;
VAL_ 1116 CHR45C_3_0_CHGFEDSTT 6 "文言F" 5 "文言E" 4 "文言D" 3 "文言C" 2 "文言B" 1 "文言A" 0 "要求なし" ;
VAL_ 1111 CHR457_10_6_STLMT_TYPE 2 "Other_EIMPnC" 1 "PnC" 0 "EIM" ;
VAL_ 1111 CHR457_10_4_ACDC_INFO 2 "Other_ACDC" 1 "DC" 0 "AC" ;
VAL_ 1111 CHR457_6_4_DCPWRSUPSTOP_DISP 1 "Power_Supply_Stop_ON" 0 "Power_Supply_Stop_OFF" ;
VAL_ 1111 CHR457_6_0_DCPWRSUPSTRT_DISP 1 "Power_Supply_Start_ON" 0 "Power_Supply_Start_OFF" ;
VAL_ 1111 CHR457_5_0_CHGSTRTNTCE_DISP 1 "Start_Notification_Request_Present" 0 "No_Request" ;
VAL_ 1111 CHR457_5_4_CHGENDNTCE_DISP 1 "End_Notification_Request_Present" 0 "No_Request" ;
VAL_ 1111 CHR457_4_0_FEDSTPRSN_DISP 255 "Fail" 254 "Initial" 26 "Power_Supply_Error_Notification_Message_Display" 25 "Power_Supply_Error_Notification_Message_Display" 17 "Power_Supply_Error_Caution_Message_Display" 16 "Power_Supply_Error_Caution_Message_Display" 15 "Power_Supply_Error_Caution_Message_Display" 14 "Power_Supply_Error_Caution_Message_Display" 5 "Power_Supply_Error_Warning_Message_Display" 4 "Power_Supply_Error_Warning_Message_Display" 3 "Power_Supply_Error_Warning_Message_Display" 2 "Power_Supply_Error_Warning_Message_Display" 1 "Power_Supply_Error_Warning_Message_Display" ;
VAL_ 1111 CHR457_3_0_CHGSTPRSN_DISP 255 "Fail" 254 "Initial" 27 "Charging_Error_Notification_Message_Display" 26 "Charging_Error_Notification_Message_Display" 25 "Charging_Error_Notification_Message_Display" 18 "Charging_Error_Caution_Message_Display" 17 "Charging_Error_Caution_Message_Display" 16 "Charging_Error_Caution_Message_Display" 15 "Charging_Error_Caution_Message_Display" 14 "Charging_Error_Caution_Message_Display" 5 "Charging_Error_Warning_Message_Display" 4 "Charging_Error_Warning_Message_Display" 3 "Charging_Error_Warning_Message_Display" 2 "Charging_Error_Warning_Message_Display" 1 "Charging_Error_Warning_Message_Display" ;
VAL_ 1109 CHR455_31_3_CHGCNRLOCSTT_DISPREQ 2 "Lock_Display_Request" 1 "Unlock_Display_Request" 0 "Hidden" ;
VAL_ 1109 CHR455_27_4_V2H_MODE 1 "ON_(Charge/Discharge_Possible)" 0 "OFF" ;
VAL_ 1109 CHR455_26_4_DCPWRSUPSTT 255 "Not_Connected_or_Out_of_Range" 7 "Power_Supply_Abnormality" 6 "Connector_Fault" 5 "Power_Supply_Stopped" 4 "Power_Supplying" 3 "Communicating" 2 "Before_Power_Supply" 1 "Before_Connection" 0 "Non_Power_Supply" ;
VAL_ 1109 CHR455_26_3_CHGMNTDISP_REQ 1 "Request" 0 "No_Request" ;
VAL_ 1109 CHR455_26_2_MNTLIT_REQ 1 "Request" 0 "No_Request" ;
VAL_ 1109 CHR455_22_1_CHGSTPCOMP 1 "通知あり" 0 "通知なし" ;
VAL_ 1109 CHR455_18_2_STLMT_TYPE 1 "PnC" 0 "EIM" ;
VAL_ 1109 CHR455_18_1_ACDC_INFO 1 "DC" 0 "AC" ;
VAL_ 1109 CHR455_6_1_CHGSTT 255 "Not_Connected_or_Out_of_Range" 254 "Initial_Value" 9 "Warming_Up" 8 "Charging_Abnormality" 7 "Connector_Fault" 6 "Charging_Reservation_Standby" 5 "Charging_Complete" 4 "Charging" 3 "Communicating" 2 "Before_Charging" 1 "Before_Connection" 0 "Non_Charging" ;
VAL_ 1109 CHR455_4_6_DCCHG_PWRUPLMT 15 "Fail" 14 "Initial" 8 "50kW" 7 "75kW" 6 "100kW" 5 "125kW" 4 "150kW" 3 "175kW" 2 "200kW" 1 "225kW" 0 "Norequest" ;
VAL_ 1109 CHR455_4_2_ACCHG_CURUPLMT 15 "Fail" 14 "Initial" 6 "8A" 5 "12A" 4 "16A" 3 "24A" 2 "32A" 1 "40A" 0 "MAX" ;
VAL_ 1109 CHR455_3_1_CHG_CNRLOCSTT 3 "Undefined" 2 "LockState" 1 "UnlockState" 0 "Initial" ;
VAL_ 1109 CHR455_3_0_CHG_CNRCNTSTT 1 "Connector_Connected" 0 "Connector_Not_Connected" ;
VAL_ 862 BAT35E_4_4_HVB_CONDCHK_FLG 3 "NONE" 2 "NONE" 1 "ON" 0 "OFF" ;
VAL_ 862 BAT35E_3_0_HVB_WRN_TEMP 3 "NONE" 2 "LOW_TEMP" 1 "HI_TEMP" 0 "NO_REQ" ;
VAL_ 1539 BEV603_15_0_BATTEMPSTS_DISP 5 "Hi" 4 "Hi-数字" 3 "Mid" 2 "Lo-数字" 1 "Lo" 0 "NOT ACTIVE" ;
VAL_ 1539 BEV603_14_0_RR_MTRTEMPSTS_DISP 5 "Hi" 4 "Hi-数字" 3 "Mid" 2 "Lo-数字" 1 "Lo" 0 "NOT ACTIVE" ;
VAL_ 1539 BEV603_14_3_FR_MTRTEMPSTS_DISP 5 "Hi" 4 "Hi-数字" 3 "Mid" 2 "Lo-数字" 1 "Lo" 0 "NOT ACTIVE" ;
VAL_ 1539 BEV603_10_2_TRQFLCREQ 3 "NONE" 2 "ON#2" 1 "ON#1" 0 "OFF" ;
VAL_ 1539 BEV603_10_4_TRQFLCNG 1 "INHIBIT" 0 "PERMIT" ;
VAL_ 1539 BEV603_10_5_TRQFLCSTATE 1 "ON" 0 "OFF" ;
VAL_ 1539 BEV603_10_6_TRQFLCDISP 1 "ON" 0 "OFF" ;
VAL_ 1539 BEV603_10_7_TRQVIBREQ 1 "REQ" 0 "NON_REQ" ;
VAL_ 1539 BEV603_9_4_PADL_INHBUZ 1 "REQ" 0 "NON_REQ" ;
VAL_ 1539 BEV603_8_1_XMODE_INH 1 "INHIBIT" 0 "PERMIT" ;
VAL_ 1539 BEV603_8_2_SIDRIVE_INH 1 "INHIBIT" 0 "PERMIT" ;
VAL_ 1539 BEV603_8_3_SIDRIVE_INHBUZ 1 "REQ" 0 "NON_REQ" ;
VAL_ 1539 BEV603_8_4_ARBIT_SIDR 1 "PERMIT" 0 "INHIBIT" ;
VAL_ 1539 BEV603_8_5_SIDRIVE_DISP 7 "PreS#" 6 "S#_TADAN" 5 "X(MUD･SAND･GRAVEL)" 4 "X(SNOW･DART)" 3 "S" 2 "I" 1 "S#" 0 "TURN_OFF" ;
VAL_ 1539 BEV603_7_4_ADPDEC_INHBUZ 1 "REQ" 0 "NON_REQ" ;
VAL_ 1539 BEV603_7_5_ADPDEC_INH_ALL 1 "INHIBIT" 0 "PERMIT" ;
VAL_ 1539 BEV603_7_6_ADPDEC_DISP 1 "ON" 0 "OFF" ;
VAL_ 1539 BEV603_7_7_ADPDEC_EQ 1 "EQUIP" 0 "NON" ;
VAL_ 1539 BEV603_6_0_AWD_MODE 7 "AWD MODE #Fail" 4 "AWD MODE #4" 3 "AWD MODE #3" 2 "AWD MODE #2" 1 "AWD MODE #1" 0 "AWD MODE #0" ;
VAL_ 1539 BEV603_6_3_AWD_STS_DISP 7 "REQ #7" 6 "REQ #6" 5 "REQ #5" 4 "REQ #4" 3 "REQ #3" 2 "REQ #2" 1 "REQ #1" 0 "NON REQ" ;
VAL_ 1539 BEV603_6_4_DECSEL_INHMSG 15 "MSG#15" 14 "MSG#14" 13 "MSG#13" 12 "MSG#12" 11 "MSG#11" 10 "MSG#10" 9 "MSG#9" 8 "MSG#8" 7 "MSG#7" 6 "MSG#6" 5 "MSG#5" 4 "MSG#4" 3 "MSG#3" 2 "MSG#2" 1 "MSG#1" 0 "NO_MSG" ;
VAL_ 1539 BEV603_6_7_AWD_MODE_EQUIP 1 "AWD MODE" 0 "NON AWD MODE" ;
VAL_ 1539 BEV603_5_0_PDLBZR 1 "ON" 0 "OFF" ;
VAL_ 1539 BEV603_5_1_SFTDN_PERM 1 "PERMIT" 0 "INHIBIT" ;
VAL_ 1539 BEV603_5_2_SFTUP_PERM 1 "PERMIT" 0 "INHIBIT" ;
VAL_ 1539 BEV603_5_3_GEARSFT_MODE 3 "TADAN_MANUAL" 2 "TADAN_AUTO" 1 "DEC_SELECT" 0 "NOT ACTIVE" ;
VAL_ 1539 BEV603_5_4_DECSEL_INH_INDI 1 "INHIBIT" 0 "PERMIT" ;
VAL_ 1539 BEV603_5_5_DECSEL_INH_B 1 "INHIBIT" 0 "PERMIT" ;
VAL_ 1539 BEV603_5_6_DECSEL_INH_D 1 "INHIBIT" 0 "PERMIT" ;
VAL_ 1539 BEV603_5_7_DECSEL_INH_ALL 1 "INHIBIT" 0 "PERMIT" ;
VAL_ 1539 BEV603_4_1_DECSEL_DISP_INDI 1 "INHIBIT" 0 "PERMIT" ;
VAL_ 1539 BEV603_4_2_DECSEL_DISP_B 3 "Blank" 2 "Hi" 1 "Mid,Standard" 0 "Lo" ;
VAL_ 1539 BEV603_4_4_DECLV_DECSEL 8 "8" 7 "7" 6 "6" 5 "5" 4 "4" 3 "3" 2 "2" 1 "1" 0 "NOT ACTIVE" ;
VAL_ 1539 BEV603_4_6_DECSEL_DISP_ALL 3 "Blank" 2 "Hi" 1 "Mid,Standard" 0 "Lo" ;
VAL_ 1539 BEV603_3_0_GEARLV_MANU 8 "8" 7 "7" 6 "6" 5 "5" 4 "4" 3 "3" 2 "2" 1 "1" 0 "NOT ACTIVE" ;
VAL_ 1539 BEV603_3_1_DECSEL_EQ_INDI 1 "EQUIP" 0 "NON" ;
VAL_ 1539 BEV603_3_2_DECSEL_EQ_B 3 "BLANK" 2 "3TYPE" 1 "2TYPE" 0 "NON" ;
VAL_ 1539 BEV603_3_4_GEARLV_AUTO 8 "8" 7 "7" 6 "6" 5 "5" 4 "4" 3 "3" 2 "2" 1 "1" 0 "NOT ACTIVE" ;
VAL_ 1539 BEV603_3_6_DECSEL_EQ_ALL 3 "BLANK" 2 "3TYPE" 1 "2TYPE" 0 "NON" ;
VAL_ 1538 BEV602_16_0_LV_SYS_STATUS 3 "未定義" 2 "異常/低下LV2" 1 "異常/低下LV1" 0 "正常" ;
VAL_ 1538 BEV602_15_0_DCM_REMOTE_INFO 7 "Error Notification" 6 "Battery alert notification" 5 "Power supply end notification" 4 "Power supply start notification" 3 "Charging end notification" 2 "Charging status data feed" 1 "Charging start notification" 0 "No notification" ;
VAL_ 1538 BEV602_14_7_RR_DISPMSG_RES_UNADJ 1 "REQ" 0 "NON_REQ" ;
VAL_ 1538 BEV602_14_6_FR_DISPMSG_RES_UNADJ 1 "REQ" 0 "NON_REQ" ;
VAL_ 1538 BEV602_14_4_DISPMSG_SC_SGLPH 3 "Message_3" 2 "Message_2" 1 "Message_1" 0 "No_Message" ;
VAL_ 1538 BEV602_14_2_CERT2_MODE 2 "active(rear-wheel drive)" 1 "active(front-wheel drive)" 0 "Not active" ;
VAL_ 1538 BEV602_14_0_SW_PWR_SPL 3 "fail" 2 "OFF" 1 "ON" 0 "first" ;
VAL_ 1538 BEV602_13_0_TCSLMP_REQ 1 "REQ" 0 "NON_REQ" ;
VAL_ 1538 BEV602_13_1_AWDLMP_REQ 3 "TURN_ON" 2 "BLINK#2" 1 "BLINK#1" 0 "TURN_OFF" ;
VAL_ 1538 BEV602_13_3_AWDWRNMSG_REQ 2 "MSG#2" 1 "MSG#1" 0 "NO_MSG" ;
VAL_ 1538 BEV602_12_0_BOSLMP_REQ 3 "NON" 2 "NON" 1 "REQ" 0 "NON_REQ" ;
VAL_ 1538 BEV602_11_3_LVB_ABN 4 "12V充電システム通信異常" 3 "再始動不可" 2 "補機LIB故障" 1 "充電不足" 0 "表示要求なし" ;
VAL_ 1538 BEV602_11_6_CERT4_MODE 1 "ON" 0 "OFF" ;
VAL_ 1538 BEV602_10_0_FACT_CERT_MODE 1 "ON" 0 "OFF" ;
VAL_ 1538 BEV602_10_1_FACT_MODE 1 "ON" 0 "OFF" ;
VAL_ 1538 BEV602_10_2_EVBATLO_CAU 7 "Undegined" 6 "Undegined" 5 "Undegined" 4 "Undegined" 3 "Message3" 2 "Message2" 1 "Message1" 0 "No_Message" ;
VAL_ 1538 BEV602_10_5_PWRLMT_ID 3 "Message_3" 2 "Message_2" 1 "Message_1" 0 "No_Message" ;
VAL_ 1538 BEV602_9_1_DCRCHK_DSP_REQ 4 "charging system check complete" 3 "charging system fail (not clothing lid )" 2 "charging system check act" 1 "charging system fail" 0 "default" ;
VAL_ 1538 BEV602_9_4_LVB_FNCLMT_MSG 3 "抑制レベル2" 2 "抑制レベル1" 1 "逼迫状態" 0 "表示要求なし" ;
VAL_ 1538 BEV602_8_0_LVB_ABN_DCDC 2 "DCDCコンバータ出力停止中" 1 "DCDCコンバータ出力制限中" 0 "表示要求なし" ;
VAL_ 1538 BEV602_8_4_LVB_ABN_LIB 3 "補機LiB交換通知" 2 "補機LiB発熱レベル2" 1 "補機LiB発熱レベル1" 0 "表示要求なし" ;
VAL_ 1538 BEV602_8_7_CHG_CAU 1 "点灯要求あり" 0 "点灯要求なし" ;
VAL_ 1538 BEV602_7_0_V2L_STOP_MSG 8 "display8" 7 "display7" 6 "display6" 5 "display5" 4 "display4" 3 "display3" 2 "display2" 1 "display1" 0 "nondisplay" ;
VAL_ 1538 BEV602_5_0_V2L_OUTSTS_2 1 "V2L ACT" 0 "V2L OFF" ;
VAL_ 1538 BEV602_5_1_V2L_OUTSTS_1 1 "V2L ACT" 0 "V2L OFF" ;
VAL_ 1538 BEV602_5_2_ACCHCAU 1 "ON" 0 "OFF" ;
VAL_ 1538 BEV602_5_3_EVIND 49 "Undefined" 48 "Undefined" 41 "Undefined" 40 "Undefined" 39 "Undefined" 38 "Undefined" 37 "Undefined" 36 "Undefined" 35 "Undefined" 34 "Undefined" 33 "Undefined" 32 "Undefined" 25 "Undefined" 24 "Undefined" 23 "Undefined" 22 "Undefined" 21 "Undefined" 20 "Undefined" 19 "Undefined" 18 "Undefined" 17 "Undefined" 16 "Undefined" 9 "Message_9" 8 "Message_8" 7 "Message_7" 6 "Message_6" 5 "Message_5" 4 "Message_4" 3 "Message_3" 2 "Message_2" 1 "Message_1" 0 "No_Message" ;
VAL_ 1538 BEV602_4_0_BEV_OBD_CAU 7 "Undefine" 6 "Undefine" 5 "Undefine" 4 "Initial_Check" 3 "Flash_3Hz" 2 "Flash_1Hz" 1 "Turn_On" 0 "Turn_Off" ;
VAL_ 1538 BEV602_4_3_EV_CAU 3 "Undefine" 2 "Flash" 1 "Turn_On" 0 "Turn_Off" ;
VAL_ 1538 BEV602_4_5_PIROFF_MSG 1 "display" 0 "nondisplay" ;
VAL_ 1538 BEV602_3_0_DRVRDY 3 "Undefine" 2 "Turn_ON" 1 "Flash" 0 "Turn_Off" ;
VAL_ 1538 BEV602_3_2_RANGE_POS 7 "未定義" 6 "blank" 5 "未定義" 4 "B" 3 "D" 2 "N" 1 "R" 0 "P" ;
VAL_ 269 BEV10D_15_6_ENGON_SND 1 "ON" 0 "OFF" ;
VAL_ 269 BEV10D_15_7_BKF_SND 1 "ON" 0 "OFF" ;
VAL_ 269 BEV10D_11_6_SNDOUT_SET 1 "ON" 0 "OFF" ;
VAL_ 269 BEV10D_7_2_DCLLO_DISP 3 "NONE" 2 "NONE" 1 "MSG#A" 0 "NO_MSG" ;
VAL_ 269 BEV10D_7_4_PMINPWRLMTSTS 1 "ON" 0 "OFF" ;
VAL_ 269 BEV10D_7_5_PMOUTPWRLMTSTS 1 "ON" 0 "OFF" ;
VAL_ 495 BEV1EF_6_0_RRMOTROT_BK 3 "FS固定値" 2 "FSバックアップ値(符号無し)" 1 "FSバックアップ値" 0 "センサ値" ;
VAL_ 495 BEV1EF_6_2_FRMOTROT_BK 3 "FS固定値" 2 "FSバックアップ値(符号無し)" 1 "FSバックアップ値" 0 "センサ値" ;
VAL_ 267 BEV10B_6_7_SPEC8 1 "PERMIT" 0 "INHIBIT" ;
VAL_ 267 BEV10B_6_6_SPEC7 1 "PERMIT" 0 "INHIBIT" ;
VAL_ 267 BEV10B_6_5_SPEC6 1 "PERMIT" 0 "INHIBIT" ;
VAL_ 267 BEV10B_6_4_SPEC5 1 "PERMIT" 0 "INHIBIT" ;
VAL_ 267 BEV10B_6_3_SPEC4 1 "PERMIT" 0 "INHIBIT" ;
VAL_ 267 BEV10B_6_2_SPEC3 1 "PERMIT" 0 "INHIBIT" ;
VAL_ 267 BEV10B_6_1_SPEC2 1 "PERMIT" 0 "INHIBIT" ;
VAL_ 267 BEV10B_6_0_SPEC1 1 "PERMIT" 0 "INHIBIT" ;
VAL_ 267 BEV10B_5_2_DENO 1 "PERMIT" 0 "INHIBIT" ;
VAL_ 267 BEV10B_5_1_PROHIBIT_INC 1 "INHIBIT" 0 "PERMIT" ;
VAL_ 267 BEV10B_5_0_PERMIT_INC 1 "PERMIT" 0 "INHIBIT" ;
VAL_ 267 BEV10B_3_2_OBDRDY 1 "OBDReady-ON" 0 "OBDReady-OFF" ;
VAL_ 267 BEV10B_3_0_DRVRDY 3 "Undefine" 2 "Turn_ON" 1 "Flash" 0 "Turn_Off" ;
VAL_ 116 BEV074_7_0_LVPWRDWN 3 "抑制レベル3" 2 "抑制レベル2" 1 "抑制レベル1" 0 "抑制要求なし" ;
VAL_ 116 BEV074_7_6_CHRCONSTA 1 "Connected" 0 "NotConnected" ;
VAL_ 116 BEV074_7_7_VEHICLE_IGN 1 "ON" 0 "OFF" ;
VAL_ 116 BEV074_6_0_EV_CAU 3 "Undefine" 2 "Flash" 1 "Turn_On" 0 "Turn_Off" ;
VAL_ 116 BEV074_6_2_BEV_OBD_CAU 7 "Undefine" 6 "Undefine" 5 "Undefine" 4 "Initial_Check" 3 "Flash_3Hz" 2 "Flash_1Hz" 1 "Turn_On" 0 "Turn_Off" ;
VAL_ 116 BEV074_6_5_SIDRIVE_DISP 7 "PreS#" 6 "S#_TADAN" 5 "X(DEEP SNOW・MUD)" 4 "X(SNOW･DIRT)" 3 "S" 2 "I" 1 "S#" 0 "TURN_OFF" ;
VAL_ 116 BEV074_5_0_ACCHG_STATE 1 "充電実施中" 0 "充電未実施" ;
VAL_ 116 BEV074_5_1_DCCHG_STATE 1 "DC充電実施中" 0 "DC充電未実施" ;
VAL_ 116 BEV074_5_2_RANGE_DG 1 "異常" 0 "正常" ;
VAL_ 116 BEV074_5_3_ACCP_DG 1 "ON" 0 "OFF" ;
VAL_ 116 BEV074_5_4_REZ_SPD_BK 3 "FS固定値" 2 "FSバックアップ値(符号無し)" 1 "FSバックアップ値" 0 "センサ値" ;
VAL_ 116 BEV074_5_6_OBDRDY 1 "Ready-ON" 0 "Ready-OFF" ;
VAL_ 116 BEV074_5_7_FHVB 1 "ON" 0 "OFF" ;
VAL_ 116 BEV074_3_0_RANGE_POS 7 "未定義" 6 "blank" 5 "未定義" 4 "B" 3 "D" 2 "N" 1 "R" 0 "P" ;
VAL_ 116 BEV074_3_3_DRVRDY 3 "Undefine" 2 "Turn_ON" 1 "Flash" 0 "Turn_Off" ;
VAL_ 116 BEV074_3_5_HVSYSTS 3 "停止処理中" 2 "起動処理中" 1 "起動" 0 "停止" ;
VAL_ 116 BEV074_1_4_RANGE_DG2 1 "異常" 0 "正常" ;
VAL_ 116 BEV074_1_5_REZ_SPD_BK 5 "FS固定値" 4 "RrFSバックアップ値(符号無し)" 3 "FrFSバックアップ値(符号無し)" 2 "Rrセンサ値" 1 "Frセンサ値" 0 "FrRrセンサ値" ;
